VERSION "dbc-export 1 2026.26.6.5"

NS_ :

BS_:

BU_: ADSP APB APP APS APSB BB BMS CC CMP CMPD CP DAS DI DIF DIR DPB EPAS3P EPAS3S EPASTP EPASTS EPBL EPBR ESP EVSE FC GTW HCML HCMR HVP IBST ICR IDB LS OCS1P PARK PCS PCS2 PM PMF PMR PNCD PTC RADC RCM RCM2 RCM3 RCU SCCM SCM SCS SDCR TAS TCU TCU2 TPMS TRCM UI UIS UMC USM V2G VC VCBATT VCBATT0 VCBATT1 VCBATT2 VCCC VCFRONT VCFRONT1 VCFRONT2 VCLEFT VCRIGHT VCSEAT2L VCSEAT2R VCSEC VEH

BO_ 1060 PCS_alertLog: 8 PCS
 SG_ PCS_alertID M : 0|7@1+ (1,0) [0|127] "" Vector__XXX
 SG_ PCS_alertSet : 15|1@1+ (1,0) [0|1] "" Vector__XXX
 SG_ PCS_alertSource : 61|3@1+ (1,0) [0|7] "" Vector__XXX
 SG_ PCS_a001_llcFrequency m1 : 16|8@1+ (1,50) [50|305] "" Vector__XXX
 SG_ PCS_a001_llcCurrent m1 : 24|8@1+ (0.1,0) [0|25.5] "" Vector__XXX
 SG_ PCS_a001_phState m1 : 32|4@1+ (1,0) [0|15] "" Vector__XXX
 SG_ PCS_a001_pfcCurrentRms m1 : 36|9@1+ (0.1,0) [0|51.1] "" Vector__XXX
 SG_ PCS_a001_intBusV m1 : 45|9@1+ (1,0) [0|511] "" Vector__XXX
 SG_ PCS_a002_phState m2 : 16|4@1+ (1,0) [0|15] "" Vector__XXX
 SG_ PCS_a003_phState m3 : 16|4@1+ (1,0) [0|15] "" Vector__XXX
 SG_ PCS_a004_phState m4 : 16|4@1+ (1,0) [0|15] "" Vector__XXX
 SG_ PCS_a005_outputV m5 : 16|8@1+ (2,0) [0|510] "" Vector__XXX
 SG_ PCS_a005_outputVOvThreshold m5 : 24|8@1+ (2,0) [0|510] "" Vector__XXX
 SG_ PCS_a006_phState m6 : 16|4@1+ (1,0) [0|15] "" Vector__XXX
 SG_ PCS_a006_intBusPrechargeTarget m6 : 20|9@1+ (1,0) [0|511] "" Vector__XXX
 SG_ PCS_a006_intBusV m6 : 29|9@1+ (1,0) [0|511] "" Vector__XXX
 SG_ PCS_a006_inputVrms m6 : 38|9@1+ (1,0) [0|511] "" Vector__XXX
 SG_ PCS_a006_inputVToIntBusDeltaMax m6 : 47|7@1+ (1,0) [0|127] "" Vector__XXX
 SG_ PCS_a006_inputFrequency m6 : 54|7@1+ (1,40) [40|167] "" Vector__XXX
 SG_ PCS_a007_phATemperature m7 : 16|7@1+ (1,0) [0|127] "" Vector__XXX
 SG_ PCS_a007_phBTemperature m7 : 23|7@1+ (1,0) [0|127] "" Vector__XXX
 SG_ PCS_a007_phCTemperature m7 : 30|7@1+ (1,0) [0|127] "" Vector__XXX
 SG_ PCS_a007_ambientTemperature m7 : 37|7@1+ (1,0) [0|127] "" Vector__XXX
 SG_ PCS_a007_inputVrms m7 : 44|9@1+ (1,0) [0|511] "" Vector__XXX
 SG_ PCS_a007_inputIrms m7 : 53|8@1+ (0.5,0) [0|127.5] "" Vector__XXX
 SG_ PCS_a008_phState m8 : 16|4@1+ (1,0) [0|15] "" Vector__XXX
 SG_ PCS_a008_phaseTemperature m8 : 20|11@1- (0.1,40) [-62.4|142.3] "" Vector__XXX
 SG_ PCS_a008_inputVrms m8 : 31|9@1+ (1,0) [0|511] "" Vector__XXX
 SG_ PCS_a008_inputIrms m8 : 40|10@1+ (0.1,0) [0|102.3] "" Vector__XXX
 SG_ PCS_a009_phState m9 : 16|4@1+ (1,0) [0|15] "" Vector__XXX
 SG_ PCS_a009_pfcCurrentRms m9 : 20|9@1+ (0.1,0) [0|51.1] "" Vector__XXX
 SG_ PCS_a009_pfcCurrentTarget m9 : 32|12@1+ (0.01,0) [0|40.95] "" Vector__XXX
 SG_ PCS_a009_llcCurrent m9 : 44|8@1+ (0.1,0) [0|25.5] "" Vector__XXX
 SG_ PCS_a009_intBusV m9 : 52|8@1+ (2,0) [0|510] "" Vector__XXX
 SG_ PCS_a010_phState m10 : 16|4@1+ (1,0) [0|15] "" Vector__XXX
 SG_ PCS_a010_pfcCurrentRms m10 : 20|9@1+ (0.1,0) [0|51.1] "" Vector__XXX
 SG_ PCS_a010_llcCurrent m10 : 32|8@1+ (0.1,0) [0|25.5] "" Vector__XXX
 SG_ PCS_a010_intBusV m10 : 40|9@1+ (1,0) [0|511] "" Vector__XXX
 SG_ PCS_a010_intBusVTarget m10 : 49|9@1+ (1,0) [0|511] "" Vector__XXX
 SG_ PCS_a011_phState m11 : 16|4@1+ (1,0) [0|15] "" Vector__XXX
 SG_ PCS_a011_llcCurrent m11 : 20|8@1+ (0.1,0) [0|25.5] "" Vector__XXX
 SG_ PCS_a011_llcCurrentTarget m11 : 28|8@1+ (0.1,0) [0|25.5] "" Vector__XXX
 SG_ PCS_a011_llcFrequency m11 : 36|8@1+ (1,50) [50|305] "" Vector__XXX
 SG_ PCS_a011_intBusV m11 : 44|8@1+ (2,0) [0|510] "" Vector__XXX
 SG_ PCS_a011_outputV m11 : 52|8@1+ (2,0) [0|510] "" Vector__XXX
 SG_ PCS_a013_phState m13 : 16|4@1+ (1,0) [0|15] "" Vector__XXX
 SG_ PCS_a013_intBusPrechargeTarget m13 : 20|9@1+ (1,0) [0|511] "" Vector__XXX
 SG_ PCS_a013_intBusV m13 : 29|9@1+ (1,0) [0|511] "" Vector__XXX
 SG_ PCS_a013_inputVrms m13 : 38|9@1+ (1,0) [0|511] "" Vector__XXX
 SG_ PCS_a013_inputVToIntBusDeltaMax m13 : 47|7@1+ (1,0) [0|127] "" Vector__XXX
 SG_ PCS_a013_inputFrequency m13 : 54|7@1+ (1,40) [40|167] "" Vector__XXX
 SG_ PCS_a014_phaTemperature m14 : 16|11@1- (0.1,40) [-62.4|142.3] "" Vector__XXX
 SG_ PCS_a014_phbTemperature m14 : 27|11@1- (0.1,40) [-62.4|142.3] "" Vector__XXX
 SG_ PCS_a014_phcTemperature m14 : 40|11@1- (0.1,40) [-62.4|142.3] "" Vector__XXX
 SG_ PCS_a015_lvBusVoltage m15 : 16|8@1+ (0.15625,0) [0|39.84375] "" Vector__XXX
 SG_ PCS_a016_phAVoltSrcMissingDetect m16 : 16|1@1+ (1,0) [0|1] "" Vector__XXX
 SG_ PCS_a016_phBVoltSrcMissingDetect m16 : 17|1@1+ (1,0) [0|1] "" Vector__XXX
 SG_ PCS_a016_phCVoltSrcMissingDetect m16 : 18|1@1+ (1,0) [0|1] "" Vector__XXX
 SG_ PCS_a018_PhaseDiff_L1N_L2N m18 : 16|9@1+ (1,-1) [-1|510] "" Vector__XXX
 SG_ PCS_a018_PhaseDiff_L2N_L3N m18 : 25|9@1+ (1,-1) [-1|510] "" Vector__XXX
 SG_ PCS_a018_PhaseDiff_L1N_L3N m18 : 34|9@1+ (1,-1) [-1|510] "" Vector__XXX
 SG_ PCS_a018_PhaseDiff_L1L2_L1N m18 : 43|9@1+ (1,-1) [-1|510] "" Vector__XXX
 SG_ PCS_a018_L1NLocked m18 : 52|1@1+ (1,0) [0|1] "" Vector__XXX
 SG_ PCS_a018_L2NLocked m18 : 53|1@1+ (1,0) [0|1] "" Vector__XXX
 SG_ PCS_a018_L3NLocked m18 : 54|1@1+ (1,0) [0|1] "" Vector__XXX
 SG_ PCS_a018_L1L2Locked m18 : 55|1@1+ (1,0) [0|1] "" Vector__XXX
 SG_ PCS_a019_pcsMaxAvailablePower m19 : 16|8@1+ (0.1,0) [0|25.5] "" Vector__XXX
 SG_ PCS_a019_utilityPowerAvailable m19 : 24|8@1+ (0.1,0) [0|25.5] "" Vector__XXX
 SG_ PCS_a019_userPowerRequest m19 : 32|8@1+ (0.1,0) [0|25.5] "" Vector__XXX
 SG_ PCS_a019_phAFaulted m19 : 40|1@1+ (1,0) [0|1] "" Vector__XXX
 SG_ PCS_a019_phBFaulted m19 : 41|1@1+ (1,0) [0|1] "" Vector__XXX
 SG_ PCS_a019_phCFaulted m19 : 42|1@1+ (1,0) [0|1] "" Vector__XXX
 SG_ PCS_a020_chargeEnableLine m20 : 16|1@1+ (1,0) [0|1] "" Vector__XXX
 SG_ PCS_a020_chargeEnableCan m20 : 17|1@1+ (1,0) [0|1] "" Vector__XXX
 SG_ PCS_a021_HVP_hvsControl m21 : 16|1@1+ (1,0) [0|1] "" Vector__XXX
 SG_ PCS_a023_CP_chargeStatus m23 : 16|1@1+ (1,0) [0|1] "" Vector__XXX
 SG_ PCS_a023_CP_status m23 : 17|1@1+ (1,0) [0|1] "" Vector__XXX
 SG_ PCS_a024_VCFRONT_sensors m24 : 16|1@1+ (1,0) [0|1] "" Vector__XXX
 SG_ PCS_a024_VCFRONT_vehicleStatus m24 : 17|1@1+ (1,0) [0|1] "" Vector__XXX
 SG_ PCS_a024_VCFRONT_systemStatus m24 : 18|1@1+ (1,0) [0|1] "" Vector__XXX
 SG_ PCS_a024_VCFRONT_coolant m24 : 19|1@1+ (1,0) [0|1] "" Vector__XXX
 SG_ PCS_a024_VCFRONT_vehNm m24 : 20|1@1+ (1,0) [0|1] "" Vector__XXX
 SG_ PCS_a024_VC_pcsManagement m24 : 21|1@1+ (1,0) [0|1] "" Vector__XXX
 SG_ PCS_a024_VCFRONT_LVPowerState m24 : 22|1@1+ (1,0) [0|1] "" Vector__XXX
 SG_ PCS_a025_cpu2ErrorCode m25 : 16|4@1+ (1,0) [0|15] "" Vector__XXX
 SG_ PCS_a025_bootromStatus m25 : 20|4@1+ (1,0) [0|15] "" Vector__XXX
 SG_ PCS_a025_bootloaderStatus m25 : 24|4@1+ (1,0) [0|15] "" Vector__XXX
 SG_ PCS_a025_bootromRequestFlag m25 : 28|1@1+ (1,0) [0|1] "" Vector__XXX
 SG_ PCS_a025_bootromRequestStatusFla m25 : 29|1@1+ (1,0) [0|1] "" Vector__XXX
 SG_ PCS_a025_cpu2StoredAppCrcLsb16 m25 : 32|16@1+ (1,0) [0|65535] "" Vector__XXX
 SG_ PCS_a027_chgPhATemp m27 : 16|8@1- (1,40) [-88|167] "" Vector__XXX
 SG_ PCS_a027_chgPhBTemp m27 : 24|8@1- (1,40) [-88|167] "" Vector__XXX
 SG_ PCS_a027_chgPhCTemp m27 : 32|8@1- (1,40) [-88|167] "" Vector__XXX
 SG_ PCS_a027_chgPhANoFlowBucket m27 : 40|5@1+ (0.2,0) [0|6.2] "" Vector__XXX
 SG_ PCS_a027_chgPhBNoFlowBucket m27 : 48|5@1+ (0.2,0) [0|6.2] "" Vector__XXX
 SG_ PCS_a027_chgPhCNoFlowBucket m27 : 56|5@1+ (0.2,0) [0|6.2] "" Vector__XXX
 SG_ PCS_a028_outputV m28 : 16|10@1+ (0.5,0) [0|511.5] "" Vector__XXX
 SG_ PCS_a028_outputVUvThreshold m28 : 26|10@1+ (0.5,0) [0|511.5] "" Vector__XXX
 SG_ PCS_a029_inputVrms m29 : 16|9@1+ (1,0) [0|511] "" Vector__XXX
 SG_ PCS_a029_chgInputPower m29 : 32|8@1+ (0.1,0) [0|25.5] "" Vector__XXX
 SG_ PCS_a029_bmsPowerCommand m29 : 40|8@1+ (0.1,0) [0|25.5] "" Vector__XXX
 SG_ PCS_a029_phaseConfig m29 : 48|4@1+ (1,0) [0|15] "" Vector__XXX
 SG_ PCS_a032_phATransientRetryCount m32 : 16|9@1+ (0.1,0) [0|51.1] "" Vector__XXX
 SG_ PCS_a032_phBTransientRetryCount m32 : 25|9@1+ (0.1,0) [0|51.1] "" Vector__XXX
 SG_ PCS_a032_phCTransientRetryCount m32 : 34|9@1+ (0.1,0) [0|51.1] "" Vector__XXX
 SG_ PCS_a032_phAFaulted m32 : 43|1@1+ (1,0) [0|1] "" Vector__XXX
 SG_ PCS_a032_phBFaulted m32 : 44|1@1+ (1,0) [0|1] "" Vector__XXX
 SG_ PCS_a032_phCFaulted m32 : 45|1@1+ (1,0) [0|1] "" Vector__XXX
 SG_ PCS_a033_HV_busV m33 : 16|12@1+ (0.146484375,0) [0|599.853515625] "" Vector__XXX
 SG_ PCS_a034_HV_busV m34 : 16|12@1+ (0.146484375,0) [0|599.853515625] "" Vector__XXX
 SG_ PCS_a035_LV_busV m35 : 16|12@1+ (0.009765625,0) [0|39.990234375] "" Vector__XXX
 SG_ PCS_a037_dcdcPwmDeassertedCount m37 : 16|8@1+ (1,0) [0|255] "" Vector__XXX
 SG_ PCS_a038_dcdcClaFaultCode m38 : 16|4@1+ (1,0) [0|15] "" Vector__XXX
 SG_ PCS_a038_dcdcSubState m38 : 20|5@1+ (1,0) [0|31] "" Vector__XXX
 SG_ PCS_a038_dcdcLvBusV m38 : 25|8@1+ (0.15625,0) [0|39.84375] "" Vector__XXX
 SG_ PCS_a038_dcdcHvBusV m38 : 33|10@1+ (0.5859375,0) [0|599.4140625] "" Vector__XXX
 SG_ PCS_a038_dcdcLvBusCurrent_A m38 : 43|10@1- (0.78125,0) [-400|399.21875] "" Vector__XXX
 SG_ PCS_a038_dcdcPwmEnableDeasserted m38 : 53|7@1+ (1,0) [0|127] "" Vector__XXX
 SG_ PCS_a038_dcdcPwmEnableLine m38 : 60|1@1+ (1,0) [0|1] "" Vector__XXX
 SG_ PCS_a040_dcdcLvVoltageTarget m40 : 16|8@1+ (0.1,0) [0|25.5] "" Vector__XXX
 SG_ PCS_a040_dcdcLvVoltage m40 : 24|8@1+ (0.1,0) [0|25.5] "" Vector__XXX
 SG_ PCS_a040_dcdcLvOutputCurrent m40 : 32|13@1- (0.1,0) [-409.6|409.5] "" Vector__XXX
 SG_ PCS_a041_dcdcTemperature m41 : 16|11@1- (0.1,40) [-62.4|142.3] "" Vector__XXX
 SG_ PCS_a042_dcdcEnableLine m42 : 16|1@1+ (1,0) [0|1] "" Vector__XXX
 SG_ PCS_a042_dcdcEnableCan m42 : 17|1@1+ (1,0) [0|1] "" Vector__XXX
 SG_ PCS_a043_dcdcLvBusV m43 : 16|10@1+ (0.0390625,0) [0|39.9609375] "" Vector__XXX
 SG_ PCS_a043_dcdcHvBusV m43 : 26|12@1+ (0.146484375,0) [0|599.853515625] "" Vector__XXX
 SG_ PCS_a043_hvPrechargeTargetV m43 : 40|12@1+ (0.146484375,0) [0|599.853515625] "" Vector__XXX
 SG_ PCS_a044_FaultReasonCode m44 : 16|2@1+ (1,0) [0|3] "" Vector__XXX
 SG_ PCS_a044_shortTime_us m44 : 18|10@1+ (0.0312805473804,0) [0|31.9999999701] "" Vector__XXX
 SG_ PCS_a044_dcdcLvBusCurrent_A m44 : 28|10@1+ (0.391006857157,0) [0|400.000014872] "" Vector__XXX
 SG_ PCS_a044_vTankPeak_abs_V m44 : 38|10@1+ (1,0) [0|1023] "" Vector__XXX
 SG_ PCS_a045_hvBusEstimated_C_uF m45 : 16|10@1+ (7.820137,0) [0|8000.000151] "" Vector__XXX
 SG_ PCS_a045_hvBusEstimated_R_kOhm m45 : 26|10@1+ (0.0488758571446,0) [0|50.0000018589] "" Vector__XXX
 SG_ PCS_a046_hvBusEstimated_C_uF m46 : 16|10@1+ (7.820137,0) [0|8000.000151] "" Vector__XXX
 SG_ PCS_a046_hvBusEstimated_R_kOhm m46 : 26|10@1+ (0.0488758571446,0) [0|50.0000018589] "" Vector__XXX
 SG_ PCS_a047_cpu1BootLoaderCrcMismat m47 : 16|1@1+ (1,0) [0|1] "" Vector__XXX
 SG_ PCS_a047_cpu2BootLoaderCrcMismat m47 : 17|1@1+ (1,0) [0|1] "" Vector__XXX
 SG_ PCS_a047_calculatedBootloaderCrc m47 : 24|32@1+ (1,0) [0|4294967295] "" Vector__XXX
 SG_ PCS_a049_dcdcTemperature m49 : 16|11@1- (0.1,40) [-62.4|142.3] "" Vector__XXX
 SG_ PCS_a051_phState m51 : 16|4@1+ (1,0) [0|15] "" Vector__XXX
 SG_ PCS_a051_pfcCurrentRms m51 : 20|9@1+ (0.1,0) [0|51.1] "" Vector__XXX
 SG_ PCS_a051_llcCurrent m51 : 29|8@1+ (0.1,0) [0|25.5] "" Vector__XXX
 SG_ PCS_a051_intBusV m51 : 37|9@1+ (1,0) [0|511] "" Vector__XXX
 SG_ PCS_a051_intBusVTarget m51 : 46|9@1+ (1,0) [0|511] "" Vector__XXX
 SG_ PCS_a051_intBusStaticRipple m51 : 55|6@1+ (1,0) [0|63] "" Vector__XXX
 SG_ PCS_a052_inputVrms m52 : 16|9@1+ (1,0) [0|511] "" Vector__XXX
 SG_ PCS_a053_inputVrms m53 : 16|9@1+ (1,0) [0|511] "" Vector__XXX
 SG_ PCS_a053_inputIrms m53 : 25|10@1+ (0.1,0) [0|102.3] "" Vector__XXX
 SG_ PCS_a053_acChargeCurrentLimit m53 : 40|7@1+ (1,0) [0|127] "" Vector__XXX
 SG_ PCS_a053_startingInputVrms m53 : 47|9@1+ (1,0) [0|511] "" Vector__XXX
 SG_ PCS_a053_phaseConfig m53 : 56|4@1+ (1,0) [0|15] "" Vector__XXX
 SG_ PCS_a054_inputVrms m54 : 16|9@1+ (1,0) [0|511] "" Vector__XXX
 SG_ PCS_a054_inputIrms m54 : 25|10@1+ (0.1,0) [0|102.3] "" Vector__XXX
 SG_ PCS_a054_acChargeCurrentLimit m54 : 40|7@1+ (1,0) [0|127] "" Vector__XXX
 SG_ PCS_a054_startingInputVrms m54 : 47|9@1+ (1,0) [0|511] "" Vector__XXX
 SG_ PCS_a054_phaseConfig m54 : 56|4@1+ (1,0) [0|15] "" Vector__XXX
 SG_ PCS_a057_inputVrms m57 : 16|10@1+ (0.5,0) [0|511.5] "" Vector__XXX
 SG_ PCS_a057_inputFrequency m57 : 26|9@1+ (0.1,40) [40|91.1] "" Vector__XXX
 SG_ PCS_a058_inputVrms m58 : 16|10@1+ (0.5,0) [0|511.5] "" Vector__XXX
 SG_ PCS_a058_inputFrequency m58 : 26|12@1+ (0.01,40) [40|80.95] "" Vector__XXX
 SG_ PCS_a059_inputVrms m59 : 16|10@1+ (0.5,0) [0|511.5] "" Vector__XXX
 SG_ PCS_a059_inputOvRmsThreshold m59 : 26|10@1+ (0.5,0) [0|511.5] "" Vector__XXX
 SG_ PCS_a060_inputVPeak m60 : 16|10@1+ (0.5,0) [0|511.5] "" Vector__XXX
 SG_ PCS_a060_inputOvPeakThreshold m60 : 26|10@1+ (0.5,0) [0|511.5] "" Vector__XXX
 SG_ PCS_a061_chgInputVdcOffset_L1N m61 : 16|8@1+ (1,0) [0|255] "" Vector__XXX
 SG_ PCS_a061_chgInputVdcOffset_L2N m61 : 24|8@1+ (1,0) [0|255] "" Vector__XXX
 SG_ PCS_a061_chgInputVdcOffset_L3N m61 : 32|8@1+ (1,0) [0|255] "" Vector__XXX
 SG_ PCS_a061_chgInputVdcOffset_L1L2 m61 : 40|8@1+ (1,0) [0|255] "" Vector__XXX
 SG_ PCS_a061_PllSourceIrrational_L1N m61 : 48|1@1+ (1,0) [0|1] "" Vector__XXX
 SG_ PCS_a061_PllSourceIrrational_L2N m61 : 49|1@1+ (1,0) [0|1] "" Vector__XXX
 SG_ PCS_a061_PllSourceIrrational_L3N m61 : 50|1@1+ (1,0) [0|1] "" Vector__XXX
 SG_ PCS_a061_PllSourceIrrational_L1L m61 : 51|1@1+ (1,0) [0|1] "" Vector__XXX
 SG_ PCS_a062_chgInputIOffset m62 : 16|12@1- (0.01,0) [-20.48|20.47] "" Vector__XXX
 SG_ PCS_a063_chgOutputV m63 : 16|10@1+ (1,0) [0|1023] "" Vector__XXX
 SG_ PCS_a063_hvpHvLinkVoltage m63 : 26|11@1- (1,0) [-1024|1023] "" Vector__XXX
 SG_ PCS_a064_chgOutputIOffset m64 : 16|12@1- (0.01,0) [-20.48|20.47] "" Vector__XXX
 SG_ PCS_a065_inputVrms m65 : 16|10@1+ (0.5,0) [0|511.5] "" Vector__XXX
 SG_ PCS_a065_inputFrequency m65 : 26|9@1+ (0.1,40) [40|91.1] "" Vector__XXX
 SG_ PCS_a066_dcdcHvBusVolt m66 : 16|14@1+ (0.1,0) [0|1638.3] "" Vector__XXX
 SG_ PCS_a066_hvpHvLinkVoltage m66 : 32|11@1- (1,0) [-1024|1023] "" Vector__XXX
 SG_ PCS_a067_dcdcLvBusVolt m67 : 16|13@1+ (0.01,0) [0|81.91] "" Vector__XXX
 SG_ PCS_a067_vcfrontPcsEFuseV m67 : 29|10@1+ (0.1,0) [0|102.3] "" Vector__XXX
 SG_ PCS_a067_vcfrontVcrightVoltage m67 : 40|10@1+ (0.1,0) [0|102.3] "" Vector__XXX
 SG_ PCS_a068_dcdcTankVolt m68 : 16|16@1- (0.030517578125,0) [-1000|999.969482422] "" Vector__XXX
 SG_ PCS_a068_dcdcTankVoltOffset m68 : 32|16@1- (0.00152587890625,0) [-50|49.9984741211] "" Vector__XXX
 SG_ PCS_a071_phState m71 : 16|4@1+ (1,0) [0|15] "" Vector__XXX
 SG_ PCS_a071_inputVrms m71 : 20|10@1+ (0.5,0) [0|511.5] "" Vector__XXX
 SG_ PCS_a071_intBusV m71 : 30|9@1+ (1,0) [0|511] "" Vector__XXX
 SG_ PCS_a071_inputFrequency m71 : 39|9@1+ (0.1,40) [40|91.1] "" Vector__XXX
 SG_ PCS_a071_llcFrequency m71 : 48|8@1+ (1,50) [50|305] "" Vector__XXX
 SG_ PCS_a072_task1Stopped m72 : 16|1@1+ (1,0) [0|1] "" Vector__XXX
 SG_ PCS_a072_task2Stopped m72 : 17|1@1+ (1,0) [0|1] "" Vector__XXX
 SG_ PCS_a073_inputL1NVrms m73 : 16|9@1+ (1,0) [0|511] "" Vector__XXX
 SG_ PCS_a073_inputL2NVrms m73 : 25|9@1+ (1,0) [0|511] "" Vector__XXX
 SG_ PCS_a073_inputL3NVrms m73 : 34|9@1+ (1,0) [0|511] "" Vector__XXX
 SG_ PCS_a073_inputNGVrms m73 : 43|9@1+ (1,0) [0|511] "" Vector__XXX
 SG_ PCS_a073_phaseConfig m73 : 52|4@1+ (1,0) [0|15] "" Vector__XXX
 SG_ PCS_a073_cpType m73 : 56|2@1+ (1,0) [0|3] "" Vector__XXX
 SG_ PCS_a074_dcdcLvBusV m74 : 16|10@1+ (0.0390625,0) [0|39.9609375] "" Vector__XXX
 SG_ PCS_a074_dcdcHvBusV m74 : 26|12@1+ (0.146484375,0) [0|599.853515625] "" Vector__XXX
 SG_ PCS_a075_dcdcLvBusV m75 : 16|10@1+ (0.0390625,0) [0|39.9609375] "" Vector__XXX
 SG_ PCS_a075_dcdcHvBusV m75 : 26|12@1+ (0.146484375,0) [0|599.853515625] "" Vector__XXX
 SG_ PCS_a075_dcdcSubState m75 : 40|5@1+ (1,0) [0|31] "" Vector__XXX
 SG_ PCS_a076_pcsControlRequest m76 : 16|2@1+ (1,0) [0|3] "" Vector__XXX
 SG_ PCS_a076_dcdcSubState m76 : 18|5@1+ (1,0) [0|31] "" Vector__XXX
 SG_ PCS_a076_dcdcEnableLine m76 : 23|1@1+ (1,0) [0|1] "" Vector__XXX
 SG_ PCS_a076_dcdcPwmEnableDeasserted m76 : 24|8@1+ (1,0) [0|255] "" Vector__XXX
 SG_ PCS_a078_phaTemperature m78 : 16|8@1- (1,40) [-88|167] "" Vector__XXX
 SG_ PCS_a078_phbTemperature m78 : 24|8@1- (1,40) [-88|167] "" Vector__XXX
 SG_ PCS_a078_phcTemperature m78 : 32|8@1- (1,40) [-88|167] "" Vector__XXX
 SG_ PCS_a078_dcdcTemperature m78 : 40|8@1- (1,40) [-88|167] "" Vector__XXX
 SG_ PCS_a078_ptCoolantTemp m78 : 48|8@1- (1,40) [-88|167] "" Vector__XXX
 SG_ PCS_a079_eepromOperation m79 : 16|4@1+ (1,0) [0|15] "" Vector__XXX
 SG_ PCS_a079_eepromOperationRegion m79 : 20|2@1+ (1,0) [0|3] "" Vector__XXX
 SG_ PCS_a079_recordID m79 : 24|8@1+ (1,0) [0|255] "" Vector__XXX
 SG_ PCS_a079_eepromOperationErrorCod m79 : 32|5@1+ (1,0) [0|31] "" Vector__XXX
 SG_ PCS_a079_operationAddress m79 : 40|16@1+ (1,0) [0|65535] "" Vector__XXX
 SG_ PCS_a079_eepromErrorCount m79 : 56|5@1+ (1,0) [0|31] "" Vector__XXX
 SG_ PCS_a080_phADamaged m80 : 16|1@1+ (1,0) [0|1] "" Vector__XXX
 SG_ PCS_a080_phBDamaged m80 : 17|1@1+ (1,0) [0|1] "" Vector__XXX
 SG_ PCS_a080_phCDamaged m80 : 18|1@1+ (1,0) [0|1] "" Vector__XXX
 SG_ PCS_a080_phANVRAMStoredState m80 : 19|3@1+ (1,0) [0|7] "" Vector__XXX
 SG_ PCS_a080_phBNVRAMStoredState m80 : 24|3@1+ (1,0) [0|7] "" Vector__XXX
 SG_ PCS_a080_phCNVRAMStoredState m80 : 27|3@1+ (1,0) [0|7] "" Vector__XXX
 SG_ PCS_a081_dcdcLvBusV m81 : 16|10@1+ (0.0390625,0) [0|39.9609375] "" Vector__XXX
 SG_ PCS_a081_dcdcHvBusV m81 : 26|12@1+ (0.146484375,0) [0|599.853515625] "" Vector__XXX
 SG_ PCS_a081_faultedSubstate m81 : 40|5@1+ (1,0) [0|31] "" Vector__XXX
 SG_ PCS_a082_dcdcLvBusV m82 : 16|10@1+ (0.0390625,0) [0|39.9609375] "" Vector__XXX
 SG_ PCS_a082_dcdcHvBusV m82 : 26|12@1+ (0.146484375,0) [0|599.853515625] "" Vector__XXX
 SG_ PCS_a082_faultedSubstate m82 : 40|5@1+ (1,0) [0|31] "" Vector__XXX
 SG_ PCS_a085_dcdcHalfPeriodUs m85 : 16|16@1+ (0.005,0) [0|327.675] "" Vector__XXX
 SG_ PCS_a086_dcdcTemperature m86 : 16|12@1- (0.1,0) [-204.8|204.7] "" Vector__XXX
 SG_ PCS_a086_pcsAmbientTemperature m86 : 28|12@1- (0.1,0) [-204.8|204.7] "" Vector__XXX
 SG_ PCS_a086_vcfrontPTCoolantTemp m86 : 40|12@1- (0.1,0) [-204.8|204.7] "" Vector__XXX
 SG_ PCS_a088_gridConfig m88 : 16|4@1+ (1,0) [0|15] "" Vector__XXX
 SG_ PCS_a088_phAFrequency m88 : 20|12@1+ (0.01,40) [40|80.95] "" Vector__XXX
 SG_ PCS_a088_phBFrequency m88 : 32|12@1+ (0.01,40) [40|80.95] "" Vector__XXX
 SG_ PCS_a088_phCFrequency m88 : 44|12@1+ (0.01,40) [40|80.95] "" Vector__XXX
 SG_ PCS_a089_hvSlewRate m89 : 16|8@1- (2,0) [-256|254] "" Vector__XXX
 SG_ PCS_a089_avgSlewRate m89 : 24|8@1- (2,0) [-256|254] "" Vector__XXX
 SG_ PCS_a089_G m89 : 32|4@1+ (0.2,0) [0|3] "" Vector__XXX
 SG_ PCS_a089_HV_busV m89 : 36|9@1+ (0.8203125,0) [0|419.1796875] "" Vector__XXX
 SG_ PCS_a089_PhaseShift m89 : 45|5@1+ (0.5,0) [0|15.5] "" Vector__XXX
 SG_ PCS_a089_Freq m89 : 50|9@1+ (1,0) [0|511] "" Vector__XXX
 SG_ PCS_a089_fastDischargeMode m89 : 59|1@1+ (1,0) [0|1] "" Vector__XXX
 SG_ PCS_a089_slowDischargeMode m89 : 60|1@1+ (1,0) [0|1] "" Vector__XXX
 SG_ PCS_a090_vRmsL1N m90 : 16|9@1+ (1,0) [0|511] "" Vector__XXX
 SG_ PCS_a090_vRmsL2N m90 : 25|9@1+ (1,0) [0|511] "" Vector__XXX
 SG_ PCS_a090_vRmsL3N m90 : 34|9@1+ (1,0) [0|511] "" Vector__XXX
 SG_ PCS_a090_vRmsL1L2 m90 : 43|9@1+ (1,0) [0|511] "" Vector__XXX
 SG_ PCS_a090_evaluatedGridConfig m90 : 52|4@1+ (1,0) [0|15] "" Vector__XXX
 SG_ PCS_a090_phASourceMissing m90 : 56|1@1+ (1,0) [0|1] "" Vector__XXX
 SG_ PCS_a090_phBSourceMissing m90 : 57|1@1+ (1,0) [0|1] "" Vector__XXX
 SG_ PCS_a090_phCSourceMissing m90 : 58|1@1+ (1,0) [0|1] "" Vector__XXX
 SG_ PCS_a091_intBusTarget m91 : 16|9@1+ (1,0) [0|511] "" Vector__XXX
 SG_ PCS_a091_intBusMaxRippleLevel m91 : 25|9@1+ (0.1,0) [0|51.1] "" Vector__XXX
 SG_ PCS_a091_pfcCurrentIrms m91 : 34|8@1+ (0.1,0) [0|25.5] "" Vector__XXX
 SG_ PCS_a091_phaseInputVrms m91 : 42|9@1+ (1,0) [0|511] "" Vector__XXX
 SG_ PCS_a091_phaseTemp m91 : 51|8@1- (1,0) [-128|127] "" Vector__XXX
 SG_ PCS_a092_pfcIrmsPhA m92 : 16|7@1+ (0.2,0) [0|25.4] "" Vector__XXX
 SG_ PCS_a092_pfcIrmsPhB m92 : 23|7@1+ (0.2,0) [0|25.4] "" Vector__XXX
 SG_ PCS_a092_pfcIrmsPhC m92 : 30|7@1+ (0.2,0) [0|25.4] "" Vector__XXX
 SG_ PCS_a092_chgTempPhA m92 : 37|8@1- (1,40) [-88|167] "" Vector__XXX
 SG_ PCS_a092_chgTempPhB m92 : 45|8@1- (1,40) [-88|167] "" Vector__XXX
 SG_ PCS_a092_chgTempPhC m92 : 53|8@1- (1,40) [-88|167] "" Vector__XXX
 SG_ PCS_a093_powerRail5VN m93 : 16|10@1+ (0.01,0) [0|10.23] "" Vector__XXX
 SG_ PCS_a093_powerRail3V3 m93 : 26|10@1+ (0.01,0) [0|10.23] "" Vector__XXX
 SG_ PCS_a093_powerRail1V5 m93 : 40|8@1+ (0.01,0) [0|2.55] "" Vector__XXX
 SG_ PCS_a093_powerRail1V2 m93 : 48|8@1+ (0.01,0) [0|2.55] "" Vector__XXX
 SG_ PCS_a093_irrational1V2Rail m93 : 56|1@1+ (1,0) [0|1] "" Vector__XXX
 SG_ PCS_a093_irrational1V5Rail m93 : 57|1@1+ (1,0) [0|1] "" Vector__XXX
 SG_ PCS_a093_irrational3V3Rail m93 : 58|1@1+ (1,0) [0|1] "" Vector__XXX
 SG_ PCS_a093_irrational5VNRail m93 : 59|1@1+ (1,0) [0|1] "" Vector__XXX
 SG_ PCS_a094_malfunctionCode m94 : 16|2@1+ (1,0) [0|3] "" Vector__XXX
 SG_ PCS_a095_powerRail5VN m95 : 16|10@1+ (0.01,0) [0|10.23] "" Vector__XXX
 SG_ PCS_a095_pcsControlRequest m95 : 26|2@1+ (1,0) [0|3] "" Vector__XXX
 SG_ PCS_a096_gridConfig m96 : 16|4@1+ (1,0) [0|15] "" Vector__XXX
 SG_ PCS_a096_phAFrequency m96 : 20|12@1+ (0.01,40) [40|80.95] "" Vector__XXX
 SG_ PCS_a096_phBFrequency m96 : 32|12@1+ (0.01,40) [40|80.95] "" Vector__XXX
 SG_ PCS_a096_phCFrequency m96 : 44|12@1+ (0.01,40) [40|80.95] "" Vector__XXX
 SG_ PCS_a097_phADamaged m97 : 16|1@1+ (1,0) [0|1] "" Vector__XXX
 SG_ PCS_a097_phBDamaged m97 : 17|1@1+ (1,0) [0|1] "" Vector__XXX
 SG_ PCS_a097_phCDamaged m97 : 18|1@1+ (1,0) [0|1] "" Vector__XXX
 SG_ PCS_a097_phANVRAMStoredState m97 : 19|3@1+ (1,0) [0|7] "" Vector__XXX
 SG_ PCS_a097_phBNVRAMStoredState m97 : 24|3@1+ (1,0) [0|7] "" Vector__XXX
 SG_ PCS_a097_phCNVRAMStoredState m97 : 27|3@1+ (1,0) [0|7] "" Vector__XXX
 SG_ PCS_a100_inputVrms m100 : 16|9@1+ (1,0) [0|511] "" Vector__XXX
 SG_ PCS_a100_phIntBusVolt m100 : 25|9@1+ (1,0) [0|511] "" Vector__XXX
 SG_ PCS_a100_phKwhCounter m100 : 34|13@1+ (1,0) [0|8191] "" Vector__XXX
 SG_ PCS_a100_phKwhCounterDeltaFromMa m100 : 48|13@1+ (1,0) [0|8191] "" Vector__XXX
 SG_ PCS_a102_pcsControlRequest m102 : 16|2@1+ (1,0) [0|3] "" Vector__XXX
 SG_ PCS_a102_NMIFlagRegisters m102 : 18|11@1+ (1,0) [0|2047] "" Vector__XXX
 SG_ PCS_a102_systemResetRegisters m102 : 29|11@1+ (1,0) [0|2047] "" Vector__XXX
 SG_ PCS_a102_dcdcEnableLine m102 : 40|1@1+ (1,0) [0|1] "" Vector__XXX
 SG_ PCS_a104_ambientTemperature m104 : 16|11@1- (0.1,40) [-62.4|142.3] "" Vector__XXX
 SG_ PCS_a107_VC_pcsInterface m107 : 16|1@1+ (1,0) [0|1] "" Vector__XXX
 SG_ PCS_a108_installedInAWrongPlatfo m108 : 16|1@1+ (1,0) [0|1] "" Vector__XXX
 SG_ PCS_a109_inputL2NVrms m109 : 16|9@1+ (1,0) [0|511] "" Vector__XXX
 SG_ PCS_a109_inputL3NVrms m109 : 25|9@1+ (1,0) [0|511] "" Vector__XXX

BO_ 932 PCS_alertMatrix: 8 PCS
 SG_ PCS_matrixIndex M : 0|4@1+ (1,0) [0|15] "" Vector__XXX
 SG_ PCS_a001_chgHwInputOc m0 : 4|1@1+ (1,0) [0|1] "" Vector__XXX
 SG_ PCS_a002_chgHwOutputOc m0 : 5|1@1+ (1,0) [0|1] "" Vector__XXX
 SG_ PCS_a003_chgHwInputOv m0 : 6|1@1+ (1,0) [0|1] "" Vector__XXX
 SG_ PCS_a004_chgHwIntBusOv m0 : 7|1@1+ (1,0) [0|1] "" Vector__XXX
 SG_ PCS_a005_chgOutputOv m0 : 8|1@1+ (1,0) [0|1] "" Vector__XXX
 SG_ PCS_a006_chgPrechargeFailedScr m0 : 9|1@1+ (1,0) [0|1] "" Vector__XXX
 SG_ PCS_a007_chgPhaseTempHot m0 : 10|1@1+ (1,0) [0|1] "" Vector__XXX
 SG_ PCS_a008_chgPhaseOverTemp m0 : 11|1@1+ (1,0) [0|1] "" Vector__XXX
 SG_ PCS_a009_chgPfcCurrentRegulation m0 : 12|1@1+ (1,0) [0|1] "" Vector__XXX
 SG_ PCS_a010_chgIntBusVRegulation m0 : 13|1@1+ (1,0) [0|1] "" Vector__XXX
 SG_ PCS_a011_chgLlcCurrentRegulation m0 : 14|1@1+ (1,0) [0|1] "" Vector__XXX
 SG_ PCS_a012_chgPfcIBandTracerFault m0 : 15|1@1+ (1,0) [0|1] "" Vector__XXX
 SG_ PCS_a013_chgPrechargeFailedBoost m0 : 16|1@1+ (1,0) [0|1] "" Vector__XXX
 SG_ PCS_a014_chgTempRationality m0 : 17|1@1+ (1,0) [0|1] "" Vector__XXX
 SG_ PCS_a015_chg12vUv m0 : 18|1@1+ (1,0) [0|1] "" Vector__XXX
 SG_ PCS_a016_chgAllPhasesFaulted m0 : 19|1@1+ (1,0) [0|1] "" Vector__XXX
 SG_ PCS_a017_chgWallPowerRemoval m0 : 20|1@1+ (1,0) [0|1] "" Vector__XXX
 SG_ PCS_a018_chgUnknownGridConfig m0 : 21|1@1+ (1,0) [0|1] "" Vector__XXX
 SG_ PCS_a019_acChargePowerLimited m0 : 22|1@1+ (1,0) [0|1] "" Vector__XXX
 SG_ PCS_a020_chgEnableLineMismatch m0 : 23|1@1+ (1,0) [0|1] "" Vector__XXX
 SG_ PCS_a021_hvpMia m0 : 24|1@1+ (1,0) [0|1] "" Vector__XXX
 SG_ PCS_a022_bmsMia m0 : 25|1@1+ (1,0) [0|1] "" Vector__XXX
 SG_ PCS_a023_cpMia m0 : 26|1@1+ (1,0) [0|1] "" Vector__XXX
 SG_ PCS_a024_vcfrontMia m0 : 27|1@1+ (1,0) [0|1] "" Vector__XXX
 SG_ PCS_a025_cpu2Malfunction m0 : 28|1@1+ (1,0) [0|1] "" Vector__XXX
 SG_ PCS_a026_watchdogAlarmed m0 : 29|1@1+ (1,0) [0|1] "" Vector__XXX
 SG_ PCS_a027_chgInsufficientCooling m0 : 30|1@1+ (1,0) [0|1] "" Vector__XXX
 SG_ PCS_a028_chgOutputUv m0 : 31|1@1+ (1,0) [0|1] "" Vector__XXX
 SG_ PCS_a029_chgPowerRationality m0 : 32|1@1+ (1,0) [0|1] "" Vector__XXX
 SG_ PCS_a030_canRationality m0 : 33|1@1+ (1,0) [0|1] "" Vector__XXX
 SG_ PCS_a031_uiMia m0 : 34|1@1+ (1,0) [0|1] "" Vector__XXX
 SG_ PCS_a032_excessiveGridTransients m0 : 35|1@1+ (1,0) [0|1] "" Vector__XXX
 SG_ PCS_a033_hvBusUv m0 : 36|1@1+ (1,0) [0|1] "" Vector__XXX
 SG_ PCS_a034_hvBusOv m0 : 37|1@1+ (1,0) [0|1] "" Vector__XXX
 SG_ PCS_a035_lvBusUv m0 : 38|1@1+ (1,0) [0|1] "" Vector__XXX
 SG_ PCS_a036_lvBusOv m0 : 39|1@1+ (1,0) [0|1] "" Vector__XXX
 SG_ PCS_a037_resonantTankOc m0 : 40|1@1+ (1,0) [0|1] "" Vector__XXX
 SG_ PCS_a038_claFaulted m0 : 41|1@1+ (1,0) [0|1] "" Vector__XXX
 SG_ PCS_a039_sdModuleClkFault m0 : 42|1@1+ (1,0) [0|1] "" Vector__XXX
 SG_ PCS_a040_dcdcMaxPowerReached m0 : 43|1@1+ (1,0) [0|1] "" Vector__XXX
 SG_ PCS_a041_dcdcOverTemp m0 : 44|1@1+ (1,0) [0|1] "" Vector__XXX
 SG_ PCS_a042_dcdcEnableLineMismatch m0 : 45|1@1+ (1,0) [0|1] "" Vector__XXX
 SG_ PCS_a043_hvBusPrechargeFailure m0 : 46|1@1+ (1,0) [0|1] "" Vector__XXX
 SG_ PCS_a044_12vSupportRegulation m0 : 47|1@1+ (1,0) [0|1] "" Vector__XXX
 SG_ PCS_a045_hvBusLowImpedance m0 : 48|1@1+ (1,0) [0|1] "" Vector__XXX
 SG_ PCS_a046_hvBusHighImpedence m0 : 49|1@1+ (1,0) [0|1] "" Vector__XXX
 SG_ PCS_a047_bootloaderCrcMismatch m0 : 50|1@1+ (1,0) [0|1] "" Vector__XXX
 SG_ PCS_a048_softwareAssertion m0 : 51|1@1+ (1,0) [0|1] "" Vector__XXX
 SG_ PCS_a049_dcdcTempRationality m0 : 52|1@1+ (1,0) [0|1] "" Vector__XXX
 SG_ PCS_a050_dcdc12VsupportFaulted m0 : 53|1@1+ (1,0) [0|1] "" Vector__XXX
 SG_ PCS_a051_chgIntBusUv m0 : 54|1@1+ (1,0) [0|1] "" Vector__XXX
 SG_ PCS_a052_acVoltageNotPresent m0 : 55|1@1+ (1,0) [0|1] "" Vector__XXX
 SG_ PCS_a053_chgInputVDropHigh m0 : 56|1@1+ (1,0) [0|1] "" Vector__XXX
 SG_ PCS_a054_chgInputVDropTooHigh m0 : 57|1@1+ (1,0) [0|1] "" Vector__XXX
 SG_ PCS_a055_chgLineImpedanceHigh m0 : 58|1@1+ (1,0) [0|1] "" Vector__XXX
 SG_ PCS_a056_chgLineImpedanceTooHigh m0 : 59|1@1+ (1,0) [0|1] "" Vector__XXX
 SG_ PCS_a057_chgInputOverFreq m0 : 60|1@1+ (1,0) [0|1] "" Vector__XXX
 SG_ PCS_a058_chgInputUnderFreq m0 : 61|1@1+ (1,0) [0|1] "" Vector__XXX
 SG_ PCS_a059_chgInputOvRms m0 : 62|1@1+ (1,0) [0|1] "" Vector__XXX
 SG_ PCS_a060_chgInputOvPeak m0 : 63|1@1+ (1,0) [0|1] "" Vector__XXX
 SG_ PCS_a061_chgVLineRationality m1 : 4|1@1+ (1,0) [0|1] "" Vector__XXX
 SG_ PCS_a062_chgILineRationality m1 : 5|1@1+ (1,0) [0|1] "" Vector__XXX
 SG_ PCS_a063_chgVOutRationality m1 : 6|1@1+ (1,0) [0|1] "" Vector__XXX
 SG_ PCS_a064_chgIOutRationality m1 : 7|1@1+ (1,0) [0|1] "" Vector__XXX
 SG_ PCS_a065_chgPllNotLocked m1 : 8|1@1+ (1,0) [0|1] "" Vector__XXX
 SG_ PCS_a066_dcdcHvRationality m1 : 9|1@1+ (1,0) [0|1] "" Vector__XXX
 SG_ PCS_a067_dcdcLvRationality m1 : 10|1@1+ (1,0) [0|1] "" Vector__XXX
 SG_ PCS_a068_dcdcTankvRationality m1 : 11|1@1+ (1,0) [0|1] "" Vector__XXX
 SG_ PCS_a069_chgPfcLineDidt m1 : 12|1@1+ (1,0) [0|1] "" Vector__XXX
 SG_ PCS_a070_chgPfcLineDvdt m1 : 13|1@1+ (1,0) [0|1] "" Vector__XXX
 SG_ PCS_a071_chgPfcILoopRationality m1 : 14|1@1+ (1,0) [0|1] "" Vector__XXX
 SG_ PCS_a072_cpu2ClaStopped m1 : 15|1@1+ (1,0) [0|1] "" Vector__XXX
 SG_ PCS_a073_unexpectedAcInputVoltag m1 : 16|1@1+ (1,0) [0|1] "" Vector__XXX
 SG_ PCS_a074_hvBusDischargeFailure m1 : 17|1@1+ (1,0) [0|1] "" Vector__XXX
 SG_ PCS_a075_hvBusDischargeTimeout m1 : 18|1@1+ (1,0) [0|1] "" Vector__XXX
 SG_ PCS_a076_dcdcEnDeassertedErr m1 : 19|1@1+ (1,0) [0|1] "" Vector__XXX
 SG_ PCS_a077_microGridWobbleDetected m1 : 20|1@1+ (1,0) [0|1] "" Vector__XXX
 SG_ PCS_a078_chgStopDcdcTooHot m1 : 21|1@1+ (1,0) [0|1] "" Vector__XXX
 SG_ PCS_a079_eepromOperationError m1 : 22|1@1+ (1,0) [0|1] "" Vector__XXX
 SG_ PCS_a080_damagedPhaseDetected m1 : 23|1@1+ (1,0) [0|1] "" Vector__XXX
 SG_ PCS_a081_dcdcPchgTimeout m1 : 24|1@1+ (1,0) [0|1] "" Vector__XXX
 SG_ PCS_a082_dcdcPchgUnsafeDiVoltage m1 : 25|1@1+ (1,0) [0|1] "" Vector__XXX
 SG_ PCS_a083_triggerOdin m1 : 26|1@1+ (1,0) [0|1] "" Vector__XXX
 SG_ PCS_a084_vDropFastInParasiticDio m1 : 27|1@1+ (1,0) [0|1] "" Vector__XXX
 SG_ PCS_a085_dcdcFetsNotSwitching m1 : 28|1@1+ (1,0) [0|1] "" Vector__XXX
 SG_ PCS_a086_dcdcInsufficientCooling m1 : 29|1@1+ (1,0) [0|1] "" Vector__XXX
 SG_ PCS_a087_nvramRecordStatusError m1 : 30|1@1+ (1,0) [0|1] "" Vector__XXX
 SG_ PCS_a088_gridFreqDroopDetected m1 : 31|1@1+ (1,0) [0|1] "" Vector__XXX
 SG_ PCS_a089_hvBusDischargeIrrationa m1 : 32|1@1+ (1,0) [0|1] "" Vector__XXX
 SG_ PCS_a090_expectedAcVoltageSource m1 : 33|1@1+ (1,0) [0|1] "" Vector__XXX
 SG_ PCS_a091_chgIntBusRationality m1 : 34|1@1+ (1,0) [0|1] "" Vector__XXX
 SG_ PCS_a092_chgPowerLimitedByBusRip m1 : 35|1@1+ (1,0) [0|1] "" Vector__XXX
 SG_ PCS_a093_powerRailRationality m1 : 36|1@1+ (1,0) [0|1] "" Vector__XXX
 SG_ PCS_a094_pcsDcdcNeedService m1 : 37|1@1+ (1,0) [0|1] "" Vector__XXX
 SG_ PCS_a095_dcdcSensorlessModeActiv m1 : 38|1@1+ (1,0) [0|1] "" Vector__XXX
 SG_ PCS_a096_microGridOverLoaded m1 : 39|1@1+ (1,0) [0|1] "" Vector__XXX
 SG_ PCS_a097_rebootPhaseDetected m1 : 40|1@1+ (1,0) [0|1] "" Vector__XXX
 SG_ PCS_a098_gridFreqDroopDetectedSi m1 : 41|1@1+ (1,0) [0|1] "" Vector__XXX
 SG_ PCS_a099_microGridOverLoadedSile m1 : 42|1@1+ (1,0) [0|1] "" Vector__XXX
 SG_ PCS_a100_suspectedViperChipIssue m1 : 43|1@1+ (1,0) [0|1] "" Vector__XXX
 SG_ PCS_a101_phMachineModelIrrationa m1 : 44|1@1+ (1,0) [0|1] "" Vector__XXX
 SG_ PCS_a102_resetWithDCDCCmdAsserte m1 : 45|1@1+ (1,0) [0|1] "" Vector__XXX
 SG_ PCS_a103_pchgWithLowLvDetected m1 : 46|1@1+ (1,0) [0|1] "" Vector__XXX
 SG_ PCS_a104_ambientTempRationality m1 : 47|1@1+ (1,0) [0|1] "" Vector__XXX
 SG_ PCS_a105_redundantVoltageSourceI m1 : 48|1@1+ (1,0) [0|1] "" Vector__XXX
 SG_ PCS_a106_clockSourceNotFromExter m1 : 49|1@1+ (1,0) [0|1] "" Vector__XXX
 SG_ PCS_a107_vcPcsDCDCInterfaceMia m1 : 50|1@1+ (1,0) [0|1] "" Vector__XXX
 SG_ PCS_a108_misconfigurationDetecte m1 : 51|1@1+ (1,0) [0|1] "" Vector__XXX
 SG_ PCS_a109_deltaChargingL2L3Swappe m1 : 52|1@1+ (1,0) [0|1] "" Vector__XXX
 SG_ PCS_d110_dcdcNeedsService m1 : 53|1@1+ (1,0) [0|1] "" Vector__XXX
 SG_ PCS_d111_batteryChargerPowerLimi m1 : 54|1@1+ (1,0) [0|1] "" Vector__XXX
 SG_ PCS_d112_logicHardwareIssue m1 : 55|1@1+ (1,0) [0|1] "" Vector__XXX
 SG_ PCS_d113_dcdcConverterTempSensor m1 : 56|1@1+ (1,0) [0|1] "" Vector__XXX
 SG_ PCS_d114_dcdcConverterVoltSensor m1 : 57|1@1+ (1,0) [0|1] "" Vector__XXX
 SG_ PCS_d115_dcdcConverterTempSensor m1 : 58|1@1+ (1,0) [0|1] "" Vector__XXX
 SG_ PCS_d116_dcdcConverterVoltSensor m1 : 59|1@1+ (1,0) [0|1] "" Vector__XXX

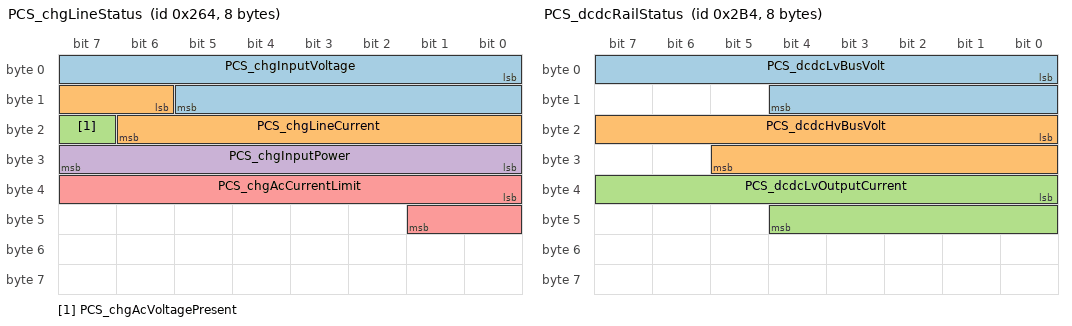
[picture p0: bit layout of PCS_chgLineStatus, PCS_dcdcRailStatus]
BO_ 612 PCS_chgLineStatus: 8 PCS
 SG_ PCS_chgInputVoltage : 0|14@1+ (0.033,0) [0|540.639] "V" Vector__XXX
 SG_ PCS_chgLineCurrent : 14|9@1+ (0.1,0) [0|50] "A" Vector__XXX
 SG_ PCS_chgAcVoltagePresent : 23|1@1+ (1,0) [0|1] "" Vector__XXX
 SG_ PCS_chgInputPower : 24|8@1+ (0.1,0) [0|20] "kW" Vector__XXX
 SG_ PCS_chgAcCurrentLimit : 32|10@1+ (0.1,0) [0|102.3] "A" Vector__XXX

BO_ 516 PCS_chgStatus: 8 PCS
 SG_ PCS_chgMainState : 0|4@1+ (1,0) [0|15] "" Vector__XXX
 SG_ PCS_powerTransferStatus : 4|2@1+ (1,0) [0|3] "" Vector__XXX
 SG_ PCS_gridConfig : 6|2@1+ (1,0) [0|3] "" Vector__XXX
 SG_ PCS_chgPHAEnable : 8|1@1+ (1,0) [0|1] "" Vector__XXX
 SG_ PCS_chgPHBEnable : 9|1@1+ (1,0) [0|1] "" Vector__XXX
 SG_ PCS_hvInletConductorEnergizedAc : 10|1@1+ (1,0) [0|1] "" Vector__XXX
 SG_ PCS_chgHighPowerActive : 11|1@1+ (1,0) [0|1] "" Vector__XXX
 SG_ PCS_chgPHCEnable : 12|1@1+ (1,0) [0|1] "" Vector__XXX
 SG_ PCS_chgInstantAcPowerAvailable : 16|8@1+ (0.1,0) [0|20] "kW" Vector__XXX
 SG_ PCS_chgMaxAcPowerAvailable : 24|8@1+ (0.1,0) [0|20] "kW" Vector__XXX
 SG_ PCS_chgPHALineCurrentRequest : 32|8@1+ (0.1,0) [0|20] "A" Vector__XXX
 SG_ PCS_chgPHBLineCurrentRequest : 40|8@1+ (0.1,0) [0|20] "A" Vector__XXX
 SG_ PCS_chgPHCLineCurrentRequest : 48|8@1+ (0.1,0) [0|20] "A" Vector__XXX
 SG_ PCS_chgPwmEnableLine : 56|1@1+ (1,0) [0|1] "" Vector__XXX
 SG_ PCS_powerTransferShutdownRequest : 57|2@1+ (1,0) [0|3] "" Vector__XXX
 SG_ PCS_hwVariantType : 59|2@1+ (1,0) [0|3] "" Vector__XXX
 SG_ PCS_dcacBidirectionalAllowed : 61|1@1+ (1,0) [0|1] "" Vector__XXX

BO_ 692 PCS_dcdcRailStatus: 8 PCS
 SG_ PCS_dcdcLvBusVolt : 0|13@1+ (0.01,0) [0|80] "V" Vector__XXX
 SG_ PCS_dcdcHvBusVolt : 16|14@1+ (0.1,0) [0|1600] "V" Vector__XXX
 SG_ PCS_dcdcLvOutputCurrent : 32|13@1- (0.1,0) [-400|400] "A" Vector__XXX

BO_ 548 PCS_dcdcStatus: 8 PCS
 SG_ PCS_dcdcPrechargeStatus : 0|2@1+ (1,0) [0|3] "" Vector__XXX
 SG_ PCS_dcdcLvSupportStatus : 2|2@1+ (1,0) [0|3] "" Vector__XXX
 SG_ PCS_dcdcHvBusDischargeStatus : 4|2@1+ (1,0) [0|3] "" Vector__XXX
 SG_ PCS_coldSleepAllowed : 8|1@1+ (1,0) [0|1] "" Vector__XXX
 SG_ PCS_dcdcPchgHVBusLowRDetected : 9|1@1+ (1,0) [0|1] "" Vector__XXX
 SG_ PCS_dcdcSubState : 10|5@1+ (1,0) [0|31] "" Vector__XXX
 SG_ PCS_dcdcFaulted : 15|1@1+ (1,0) [0|1] "" Vector__XXX
 SG_ PCS_dcdcEn13V5WithStrongPullup : 16|1@1+ (1,0) [0|1] "" Vector__XXX
 SG_ PCS_okToBePowerCycled : 27|1@1+ (1,0) [0|1] "" Vector__XXX
 SG_ PCS_dcdcOutputIsLimited : 28|1@1+ (1,0) [0|1] "" Vector__XXX
 SG_ PCS_dcdcMaxOutputCurrentAllowed : 29|12@1+ (0.1,0) [0|400] "A" Vector__XXX
 SG_ PCS_dcdcPrechargeRtyCnt : 41|3@1+ (1,0) [0|7] "" Vector__XXX
 SG_ PCS_dcdcLvSupportRtyCnt : 44|4@1+ (1,0) [0|15] "" Vector__XXX
 SG_ PCS_dcdcDischargeRtyCnt : 48|4@1+ (1,0) [0|15] "" Vector__XXX
 SG_ PCS_dcdcPwmEnableLine : 52|1@1+ (1,0) [0|1] "" Vector__XXX
 SG_ PCS_dcdcSupportingFixedLvTarget : 53|1@1+ (1,0) [0|1] "" Vector__XXX
 SG_ PCS_ecuLogUploadRequest : 54|2@1+ (1,0) [0|3] "" Vector__XXX
 SG_ PCS_dcdcPrechargeRestartCnt : 56|3@1+ (1,0) [0|7] "" Vector__XXX
 SG_ PCS_dcdcInitialPrechargeSubState : 59|5@1+ (1,0) [0|31] "" Vector__XXX

BO_ 964 PCS_info: 8 PCS
 SG_ PCS_infoIndex M : 0|8@1+ (1,0) [0|255] "" Vector__XXX
 SG_ PCS_buildType m10 : 8|8@1+ (1,0) [0|255] "" Vector__XXX
 SG_ PCS_buildConfigId m10 : 16|16@1+ (1,0) [0|65535] "" Vector__XXX
 SG_ PCS_hardwareId m10 : 32|16@1+ (1,0) [0|65535] "" Vector__XXX
 SG_ PCS_componentId m10 : 48|16@1+ (1,0) [0|65535] "" Vector__XXX
 SG_ PCS_pcbaId m11 : 16|8@1+ (1,0) [0|255] "" Vector__XXX
 SG_ PCS_assemblyId m11 : 24|8@1+ (1,0) [0|255] "" Vector__XXX
 SG_ PCS_usageId m11 : 32|16@1+ (1,0) [0|65535] "" Vector__XXX
 SG_ PCS_subUsageId m11 : 48|16@1+ (1,0) [0|65535] "" Vector__XXX
 SG_ PCS_platformType m13 : 8|8@1+ (1,0) [0|255] "" Vector__XXX
 SG_ PCS_appCrc m13 : 32|32@1+ (1,0) [0|4294967295] "" Vector__XXX
 SG_ PCS_cpu2AppCrc m16 : 32|32@1+ (1,0) [0|4294967295] "" Vector__XXX
 SG_ PCS_appGitHash m17 : 8|56@1+ (1,0) [0|7.20575940379e+16] "" Vector__XXX
 SG_ PCS_bootGitHash m18 : 8|56@1+ (1,0) [0|7.20575940379e+16] "" Vector__XXX
 SG_ PCS_bootUdsProtoVersion m20 : 8|8@1+ (1,0) [0|255] "" Vector__XXX
 SG_ PCS_bootCrc m20 : 32|32@1+ (1,0) [0|4294967295] "" Vector__XXX

BO_ 708 PCS_logging: 8 PCS
 SG_ PCS_logMessageSelect M : 0|5@1+ (1,0) [0|31] "" Vector__XXX
 SG_ PCS_chgPhAInputIrms m0 : 5|9@1+ (0.1,0) [0|51.1] "A" Vector__XXX
 SG_ PCS_chgPhAIntBusV m0 : 14|9@1+ (1,0) [0|511] "V" Vector__XXX
 SG_ PCS_chgPhAIntBusVTarget m0 : 23|9@1+ (1,0) [0|511] "V" Vector__XXX
 SG_ PCS_chgPhAOutputI m0 : 32|8@1+ (0.1,0) [0|25.5] "A" Vector__XXX
 SG_ PCS_chgPhAInputCurrentLimitReaso m0 : 40|3@1+ (1,0) [0|7] "" Vector__XXX
 SG_ PCS_chgPhBInputIrms m1 : 5|9@1+ (0.1,0) [0|51.1] "A" Vector__XXX
 SG_ PCS_chgPhBIntBusV m1 : 14|9@1+ (1,0) [0|511] "V" Vector__XXX
 SG_ PCS_chgPhBIntBusVTarget m1 : 23|9@1+ (1,0) [0|511] "V" Vector__XXX
 SG_ PCS_chgPhBOutputI m1 : 32|8@1+ (0.1,0) [0|25.5] "A" Vector__XXX
 SG_ PCS_chgPhBInputCurrentLimitReaso m1 : 40|3@1+ (1,0) [0|7] "" Vector__XXX
 SG_ PCS_chgPhCInputIrms m2 : 5|9@1+ (0.1,0) [0|51.1] "A" Vector__XXX
 SG_ PCS_chgPhCIntBusV m2 : 14|9@1+ (1,0) [0|511] "V" Vector__XXX
 SG_ PCS_chgPhCIntBusVTarget m2 : 23|9@1+ (1,0) [0|511] "V" Vector__XXX
 SG_ PCS_chgPhCOutputI m2 : 32|8@1+ (0.1,0) [0|25.5] "A" Vector__XXX
 SG_ PCS_chgPhCInputCurrentLimitReaso m2 : 40|3@1+ (1,0) [0|7] "" Vector__XXX
 SG_ PCS_chgInputL1NVrms m3 : 5|12@1+ (0.2,0) [0|819] "V" Vector__XXX
 SG_ PCS_chgInputL2NVrms m3 : 17|12@1+ (0.2,0) [0|819] "V" Vector__XXX
 SG_ PCS_chgInputL3NVrms m3 : 29|12@1+ (0.2,0) [0|819] "V" Vector__XXX
 SG_ PCS_chgInputL1L2Vrms m3 : 41|12@1+ (0.2,0) [0|819] "V" Vector__XXX
 SG_ PCS_chgInputNGVrms m3 : 53|9@1+ (1,0) [0|511] "V" Vector__XXX
 SG_ PCS_chgInputFrequencyL1N m4 : 5|12@1+ (0.01,40) [40|80.95] "Hz" Vector__XXX
 SG_ PCS_chgInputFrequencyL2N m4 : 17|12@1+ (0.01,40) [40|80.95] "Hz" Vector__XXX
 SG_ PCS_chgInputFrequencyL3N m4 : 29|12@1+ (0.01,40) [40|80.95] "Hz" Vector__XXX
 SG_ PCS_chgInternalPhaseConfig m4 : 41|4@1+ (1,0) [0|15] "" Vector__XXX
 SG_ PCS_chgPhasesPriority m4 : 45|6@1+ (1,0) [0|63] "" Vector__XXX
 SG_ PCS_chgOutputV m4 : 51|12@1+ (0.146484375,0) [0|599.853515625] "V" Vector__XXX
 SG_ PCS_chgPhAState m5 : 5|4@1+ (1,0) [0|15] "" Vector__XXX
 SG_ PCS_chgPhBState m5 : 9|4@1+ (1,0) [0|15] "" Vector__XXX
 SG_ PCS_chgPhCState m5 : 13|4@1+ (1,0) [0|15] "" Vector__XXX
 SG_ PCS_chgPhALastShutdownReason m5 : 17|5@1+ (1,0) [0|31] "" Vector__XXX
 SG_ PCS_chgPhBLastShutdownReason m5 : 22|5@1+ (1,0) [0|31] "" Vector__XXX
 SG_ PCS_chgPhCLastShutdownReason m5 : 27|5@1+ (1,0) [0|31] "" Vector__XXX
 SG_ PCS_chgPhARetryCount m5 : 32|3@1+ (1,0) [0|7] "" Vector__XXX
 SG_ PCS_chgPhBRetryCount m5 : 35|3@1+ (1,0) [0|7] "" Vector__XXX
 SG_ PCS_chgPhCRetryCount m5 : 38|3@1+ (1,0) [0|7] "" Vector__XXX
 SG_ PCS_chgRetryCount m5 : 41|3@1+ (1,0) [0|7] "" Vector__XXX
 SG_ PCS_chgPhManCurrentToDist m5 : 44|10@1+ (0.1,0) [0|100] "A" Vector__XXX
 SG_ PCS_chgL1NPllLocked m5 : 54|1@1+ (1,0) [0|1] "" Vector__XXX
 SG_ PCS_chgL2NPllLocked m5 : 55|1@1+ (1,0) [0|1] "" Vector__XXX
 SG_ PCS_chgL3NPllLocked m5 : 56|1@1+ (1,0) [0|1] "" Vector__XXX
 SG_ PCS_chgL1L2PllLocked m5 : 57|1@1+ (1,0) [0|1] "" Vector__XXX
 SG_ PCS_chgNgPllLocked m5 : 58|1@1+ (1,0) [0|1] "" Vector__XXX
 SG_ PCS_chgPhManOptimalPhsToUse m5 : 59|2@1+ (1,0) [0|3] "" Vector__XXX
 SG_ PCS_chg5VL1Enable m5 : 61|1@1+ (1,0) [0|1] "" Vector__XXX
 SG_ PCS_dcdcMaxLvOutputCurrent m6 : 8|12@1+ (0.1,0) [0|400] "A" Vector__XXX
 SG_ PCS_dcdcCurrentLimit m6 : 20|12@1+ (0.1,0) [0|400] "A" Vector__XXX
 SG_ PCS_dcdcLvOutputCurrentTempLimit m6 : 32|12@1+ (0.1,0) [0|400] "A" Vector__XXX
 SG_ PCS_dcdcLvOutputCurrentFiltered m6 : 44|12@1+ (0.1,0) [0|400] "A" Vector__XXX
 SG_ PCS_dcdcUnifiedCommand m7 : 5|10@1+ (0.001,0) [0|1] "1" Vector__XXX
 SG_ PCS_dcdcCLAControllerOutput m7 : 16|10@1+ (0.001,0) [0|1] "1" Vector__XXX
 SG_ PCS_dcdcTankVoltage m7 : 26|11@1- (1,0) [-1024|1023] "V" Vector__XXX
 SG_ PCS_dcdcTankVoltageTarget m7 : 37|10@1+ (1,0) [0|1023] "V" Vector__XXX
 SG_ PCS_dcdcClaCurrentFreq m7 : 48|12@1+ (0.09765625,0) [0|399.9] "kHz" Vector__XXX
 SG_ PCS_dcdcTCommMeasured m8 : 5|16@1- (0.001953125,0) [-64|63.998] "us" Vector__XXX
 SG_ PCS_dcdcShortTimeUs m8 : 21|16@1+ (0.00048828125,0) [0|31.9995] "us" Vector__XXX
 SG_ PCS_dcdcHalfPeriodUs m8 : 37|16@1+ (0.00048828125,0) [0|31.9995] "us" Vector__XXX
 SG_ PCS_dcdcLvBusVoltTargetWithOffse m8 : 53|11@1+ (0.01,0) [0|20] "V" Vector__XXX
 SG_ PCS_cpu2BootState m9 : 5|2@1+ (1,0) [0|3] "" Vector__XXX
 SG_ PCS_acChargeSelfTestState m9 : 7|1@1+ (1,0) [0|1] "" Vector__XXX
 SG_ PCS_1V5Min10s m9 : 8|11@1+ (0.001,0) [0|2.047] "V" Vector__XXX
 SG_ PCS_1V5Max10s m9 : 19|11@1+ (0.001,0) [0|2.047] "V" Vector__XXX
 SG_ PCS_1V2Min10s m9 : 32|11@1+ (0.001,0) [0|2.047] "V" Vector__XXX
 SG_ PCS_1V2Max10s m9 : 43|11@1+ (0.001,0) [0|2.047] "V" Vector__XXX
 SG_ PCS_5VNMax10s m9 : 54|10@1+ (0.01,0) [0|10.23] "V" Vector__XXX
 SG_ PCS_chgPhAIntBusVMin10s m10 : 5|9@1+ (1,0) [0|511] "V" Vector__XXX
 SG_ PCS_chgPhAIntBusVMax10s m10 : 14|9@1+ (1,0) [0|511] "V" Vector__XXX
 SG_ PCS_chgPhAPchgVoltDeltaMax10s m10 : 23|8@1+ (0.5,0) [0|127.5] "V" Vector__XXX
 SG_ PCS_chgPhALifetimekWh m10 : 31|24@1+ (0.01,0) [0|167772.15] "kWh" Vector__XXX
 SG_ PCS_chgPhATransientRetryCount m10 : 55|9@1+ (0.1,0) [0|51.1] "-" Vector__XXX
 SG_ PCS_chgPhBIntBusVMin10s m11 : 5|9@1+ (1,0) [0|511] "V" Vector__XXX
 SG_ PCS_chgPhBIntBusVMax10s m11 : 14|9@1+ (1,0) [0|511] "V" Vector__XXX
 SG_ PCS_chgPhBPchgVoltDeltaMax10s m11 : 23|8@1+ (0.5,0) [0|127.5] "V" Vector__XXX
 SG_ PCS_chgPhBLifetimekWh m11 : 31|24@1+ (0.01,0) [0|167772.15] "kWh" Vector__XXX
 SG_ PCS_chgPhBTransientRetryCount m11 : 55|9@1+ (0.1,0) [0|51.1] "-" Vector__XXX
 SG_ PCS_chgPhCIntBusVMin10s m12 : 5|9@1+ (1,0) [0|511] "V" Vector__XXX
 SG_ PCS_chgPhCIntBusVMax10s m12 : 14|9@1+ (1,0) [0|511] "V" Vector__XXX
 SG_ PCS_chgPhCPchgVoltDeltaMax10s m12 : 23|8@1+ (0.5,0) [0|127.5] "V" Vector__XXX
 SG_ PCS_chgPhCLifetimekWh m12 : 31|24@1+ (0.01,0) [0|167772.15] "kWh" Vector__XXX
 SG_ PCS_chgPhCTransientRetryCount m12 : 55|9@1+ (0.1,0) [0|51.1] "-" Vector__XXX
 SG_ PCS_chgPhANoFlowBucket m20 : 5|9@1+ (0.01,0) [0|5.11] "-" Vector__XXX
 SG_ PCS_chgPhBNoFlowBucket m20 : 14|9@1+ (0.01,0) [0|5.11] "-" Vector__XXX
 SG_ PCS_chgPhCNoFlowBucket m20 : 23|9@1+ (0.01,0) [0|5.11] "-" Vector__XXX
 SG_ PCS_chgCurrentSensorOutOfBandUs m20 : 32|10@1+ (0.01,0) [0|10.23] "us" Vector__XXX
 SG_ PCS_chgAcpwHeartbeatState m20 : 42|3@1+ (1,0) [0|7] "" Vector__XXX
 SG_ PCS_chgKwhLostByFreqDroop m20 : 48|8@1+ (0.1,0) [0|25.5] "kWh" Vector__XXX
 SG_ PCS_chgReqKwhLostByFreqDroop m20 : 56|8@1+ (0.1,0) [0|25.5] "kWh" Vector__XXX
 SG_ PCS_dcdcLvSupportLifetimekWh m22 : 8|24@1+ (0.01,0) [0|167772.15] "kWh" Vector__XXX
 SG_ PCS_chgPwmEnableLineErrorCount m22 : 32|10@1+ (1,0) [0|1023] "" Vector__XXX
 SG_ PCS_dcdcPwmEnableLineErrorCount m22 : 42|10@1+ (1,0) [0|1023] "" Vector__XXX
 SG_ PCS_numAlertsSet m22 : 56|7@1+ (1,0) [0|127] "" Vector__XXX
 SG_ PCS_dcdcPchgStartLvBusVolt m24 : 5|10@1+ (0.0390625,0) [0|39.9609375] "V" Vector__XXX
 SG_ PCS_dcdcPchgStartHvBusVolt m24 : 16|12@1+ (0.146484375,0) [0|599.853515625] "V" Vector__XXX
 SG_ PCS_dcdcHvBusEstimated_C_uF m24 : 28|10@1+ (7.820137,0) [0|8000] "uF" Vector__XXX
 SG_ PCS_dcdcHvBusEstimated_R_kOhm m24 : 38|10@1+ (0.0488758571446,0) [0|50] "kOhm" Vector__XXX
 SG_ PCS_processorDieIdLot m25 : 8|24@1+ (1,0) [0|16777215] "" Vector__XXX
 SG_ PCS_processorDieIdWafer m25 : 32|8@1+ (1,0) [0|255] "" Vector__XXX
 SG_ PCS_processorDieIdX m25 : 40|12@1+ (1,0) [0|4095] "" Vector__XXX
 SG_ PCS_processorDieIdY m25 : 52|12@1+ (1,0) [0|4095] "" Vector__XXX

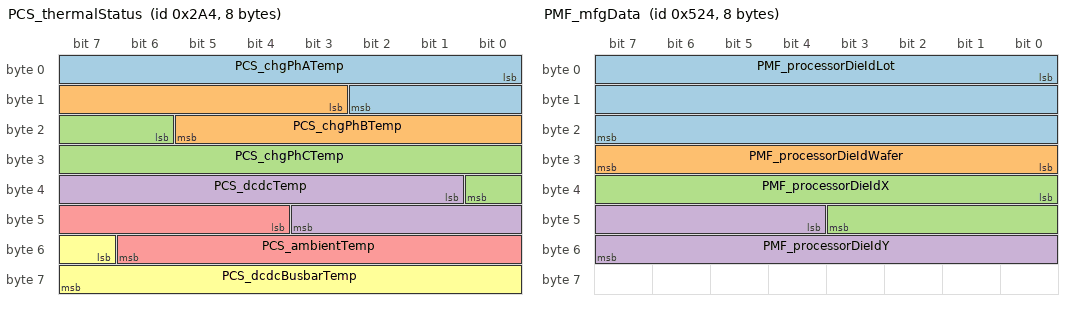
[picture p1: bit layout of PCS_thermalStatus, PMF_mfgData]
BO_ 676 PCS_thermalStatus: 8 PCS
 SG_ PCS_chgPhATemp : 0|11@1- (0.1,40) [-62.4|142.3] "C" Vector__XXX
 SG_ PCS_chgPhBTemp : 11|11@1- (0.1,40) [-62.4|142.3] "C" Vector__XXX
 SG_ PCS_chgPhCTemp : 22|11@1- (0.1,40) [-62.4|142.3] "C" Vector__XXX
 SG_ PCS_dcdcTemp : 33|11@1- (0.1,40) [-62.4|142.3] "C" Vector__XXX
 SG_ PCS_ambientTemp : 44|11@1- (0.1,40) [-62.4|142.3] "C" Vector__XXX
 SG_ PCS_dcdcBusbarTemp : 55|9@1+ (0.2935421,0) [0|150] "C" Vector__XXX

BO_ 1317 PMF_alertLog: 8 PMF
 SG_ PMF_alertID M : 0|7@1+ (1,0) [0|127] "" Vector__XXX
 SG_ PMF_alertState : 15|1@1+ (1,0) [0|1] "" Vector__XXX
 SG_ PMF_a001_w0 m1 : 16|16@1+ (1,0) [0|65535] "" Vector__XXX
 SG_ PMF_a001_w1 m1 : 32|16@1+ (1,0) [0|65535] "" Vector__XXX
 SG_ PMF_a001_w2 m1 : 48|16@1+ (1,0) [0|65535] "" Vector__XXX
 SG_ PMF_a002_torqueAverage m2 : 16|1@1+ (1,0) [0|1] "" Vector__XXX
 SG_ PMF_a002_torqueWindow m2 : 17|1@1+ (1,0) [0|1] "" Vector__XXX
 SG_ PMF_a002_torqueMeasured m2 : 18|13@1- (2,0) [-8192|8190] "" Vector__XXX
 SG_ PMF_a002_torqueAccelAverage m2 : 32|13@1- (2,0) [-8192|8190] "" Vector__XXX
 SG_ PMF_a002_torqueAccelWindow m2 : 48|13@1- (2,0) [-8192|8190] "" Vector__XXX
 SG_ PMF_a003_reverseGear m3 : 16|1@1+ (1,0) [0|1] "" Vector__XXX
 SG_ PMF_a003_pedalPos m3 : 24|8@1+ (0.4,0) [0|102] "" Vector__XXX
 SG_ PMF_a003_zeroPointPedal m3 : 32|8@1+ (0.4,0) [0|102] "" Vector__XXX
 SG_ PMF_a004_torqueAverage m4 : 16|1@1+ (1,0) [0|1] "" Vector__XXX
 SG_ PMF_a004_torqueWindow m4 : 17|1@1+ (1,0) [0|1] "" Vector__XXX
 SG_ PMF_a004_torqueMeasured m4 : 18|13@1- (2,0) [-8192|8190] "" Vector__XXX
 SG_ PMF_a004_torqueDecelAverage m4 : 32|13@1- (2,0) [-8192|8190] "" Vector__XXX
 SG_ PMF_a004_torqueDecelWindow m4 : 48|13@1- (2,0) [-8192|8190] "" Vector__XXX
 SG_ PMF_a005_torqueReason m5 : 16|2@1+ (1,0) [0|3] "" Vector__XXX
 SG_ PMF_a005_torqueMeasured m5 : 18|13@1- (2,0) [-8192|8190] "" Vector__XXX
 SG_ PMF_a005_iDQmagnitude m5 : 32|16@1- (0.0939,0) [-3076.9152|3076.8213] "" Vector__XXX
 SG_ PMF_a006_torqueActual m6 : 16|13@1- (2,0) [-8192|8190] "" Vector__XXX
 SG_ PMF_a006_motorRPM m6 : 32|16@1- (1,0) [-32768|32767] "" Vector__XXX
 SG_ PMF_a006_torqueMeasured m6 : 48|13@1- (2,0) [-8192|8190] "" Vector__XXX
 SG_ PMF_a010_messageId m10 : 16|16@1+ (1,0) [0|65535] "" Vector__XXX
 SG_ PMF_a010_DI_status m10 : 32|1@1+ (1,0) [0|1] "" Vector__XXX
 SG_ PMF_a010_DI_torque m10 : 33|1@1+ (1,0) [0|1] "" Vector__XXX
 SG_ PMF_a010_DI_slaveCommand m10 : 34|1@1+ (1,0) [0|1] "" Vector__XXX
 SG_ PMF_a010_DI_locStatus m10 : 35|1@1+ (1,0) [0|1] "" Vector__XXX
 SG_ PMF_a010_DI_speed m10 : 36|1@1+ (1,0) [0|1] "" Vector__XXX
 SG_ PMF_a010_DI_systemStatus m10 : 37|1@1+ (1,0) [0|1] "" Vector__XXX
 SG_ PMF_a010_DI_chassisControl m10 : 38|1@1+ (1,0) [0|1] "" Vector__XXX
 SG_ PMF_a010_DI_chassisControl2 m10 : 39|1@1+ (1,0) [0|1] "" Vector__XXX
 SG_ PMF_a010_vdcLeft m10 : 40|1@1+ (1,0) [0|1] "" Vector__XXX
 SG_ PMF_a010_vdcRight m10 : 41|1@1+ (1,0) [0|1] "" Vector__XXX
 SG_ PMF_a010_DI_vehicleEstimates m10 : 42|1@1+ (1,0) [0|1] "" Vector__XXX
 SG_ PMF_a010_DI_brakeCommand m10 : 43|1@1+ (1,0) [0|1] "" Vector__XXX
 SG_ PMF_a010_DI_autonomyHealth m10 : 44|1@1+ (1,0) [0|1] "" Vector__XXX
 SG_ PMF_a010_DI_difCommand m10 : 45|1@1+ (1,0) [0|1] "" Vector__XXX
 SG_ PMF_a010_DI_dirCommand m10 : 46|1@1+ (1,0) [0|1] "" Vector__XXX
 SG_ PMF_a010_DI_dirVehicle m10 : 47|1@1+ (1,0) [0|1] "" Vector__XXX
 SG_ PMF_a010_DI_locStatus2 m10 : 48|1@1+ (1,0) [0|1] "" Vector__XXX
 SG_ PMF_a011_Ia m11 : 16|9@1- (12.0192,0) [-3076.9152|3064.896] "" Vector__XXX
 SG_ PMF_a011_IaDelta m11 : 25|8@1- (24.0384,0) [-3076.9152|3052.8768] "" Vector__XXX
 SG_ PMF_a011_Ib m11 : 33|9@1- (12.0192,0) [-3076.9152|3064.896] "" Vector__XXX
 SG_ PMF_a011_IbDelta m11 : 42|8@1- (24.0384,0) [-3076.9152|3052.8768] "" Vector__XXX
 SG_ PMF_a011_currentVref m11 : 50|8@1+ (0.04,0) [0|10.2] "" Vector__XXX
 SG_ PMF_a011_badPhaseAsample m11 : 58|1@1+ (1,0) [0|1] "" Vector__XXX
 SG_ PMF_a011_badPhaseBsample m11 : 59|1@1+ (1,0) [0|1] "" Vector__XXX
 SG_ PMF_a011_sampleFreeze m11 : 60|1@1+ (1,0) [0|1] "" Vector__XXX
 SG_ PMF_a011_rateOfChangeIrrational m11 : 61|1@1+ (1,0) [0|1] "" Vector__XXX
 SG_ PMF_a011_currentReadingIrrationa m11 : 62|1@1+ (1,0) [0|1] "" Vector__XXX
 SG_ PMF_a011_vrefIrrational m11 : 63|1@1+ (1,0) [0|1] "" Vector__XXX
 SG_ PMF_a017_EPBL_status m17 : 16|1@1+ (1,0) [0|1] "" Vector__XXX
 SG_ PMF_a017_EPBR_status m17 : 17|1@1+ (1,0) [0|1] "" Vector__XXX
 SG_ PMF_a017_EPBL_autonomyHealth m17 : 18|1@1+ (1,0) [0|1] "" Vector__XXX
 SG_ PMF_a017_EPBR_autonomyHealth m17 : 19|1@1+ (1,0) [0|1] "" Vector__XXX
 SG_ PMF_a018_w0 m18 : 16|16@1+ (1,0) [0|65535] "" Vector__XXX
 SG_ PMF_a018_w1 m18 : 32|16@1+ (1,0) [0|65535] "" Vector__XXX
 SG_ PMF_a018_w2 m18 : 48|16@1+ (1,0) [0|65535] "" Vector__XXX
 SG_ PMF_a019_statorTemp1 m19 : 16|16@1- (0.1,0) [-3276.8|3276.7] "" Vector__XXX
 SG_ PMF_a019_statorTslope1 m19 : 32|16@1- (0.1,0) [-3276.8|3276.7] "" Vector__XXX
 SG_ PMF_a025_sccReset m25 : 16|1@1+ (1,0) [0|1] "" Vector__XXX
 SG_ PMF_a025_hibernate m25 : 17|1@1+ (1,0) [0|1] "" Vector__XXX
 SG_ PMF_a025_hwBist m25 : 18|1@1+ (1,0) [0|1] "" Vector__XXX
 SG_ PMF_a025_nmiWatchdog m25 : 19|1@1+ (1,0) [0|1] "" Vector__XXX
 SG_ PMF_a025_watchdog m25 : 20|1@1+ (1,0) [0|1] "" Vector__XXX
 SG_ PMF_a025_clockFailNmi m25 : 21|1@1+ (1,0) [0|1] "" Vector__XXX
 SG_ PMF_a025_ramUncErrorNmi m25 : 22|1@1+ (1,0) [0|1] "" Vector__XXX
 SG_ PMF_a025_flashUncErrorNmi m25 : 23|1@1+ (1,0) [0|1] "" Vector__XXX
 SG_ PMF_a025_cpu1signMismatchNmi m25 : 24|1@1+ (1,0) [0|1] "" Vector__XXX
 SG_ PMF_a025_cpu2signMismatchNmi m25 : 25|1@1+ (1,0) [0|1] "" Vector__XXX
 SG_ PMF_a025_pieVectErrorNmi m25 : 26|1@1+ (1,0) [0|1] "" Vector__XXX
 SG_ PMF_a025_sysDbgNmi m25 : 27|1@1+ (1,0) [0|1] "" Vector__XXX
 SG_ PMF_a025_rlNmi m25 : 28|1@1+ (1,0) [0|1] "" Vector__XXX
 SG_ PMF_a025_ovfNmi m25 : 29|1@1+ (1,0) [0|1] "" Vector__XXX
 SG_ PMF_a025_possibleSafetyICReset m25 : 30|1@1+ (1,0) [0|1] "" Vector__XXX
 SG_ PMF_a025_powerOnReset m25 : 31|1@1+ (1,0) [0|1] "" Vector__XXX
 SG_ PMF_a025_watchdogTimer0 m25 : 32|1@1+ (1,0) [0|1] "" Vector__XXX
 SG_ PMF_a025_watchdogTimer1 m25 : 33|1@1+ (1,0) [0|1] "" Vector__XXX
 SG_ PMF_a025_watchdogTimer2 m25 : 34|1@1+ (1,0) [0|1] "" Vector__XXX
 SG_ PMF_a025_watchdogTimer3 m25 : 35|1@1+ (1,0) [0|1] "" Vector__XXX
 SG_ PMF_a025_warmResetReq m25 : 36|1@1+ (1,0) [0|1] "" Vector__XXX
 SG_ PMF_a025_externalPadReset m25 : 37|1@1+ (1,0) [0|1] "" Vector__XXX
 SG_ PMF_a025_hwSecModuleWatchdogTime m25 : 38|1@1+ (1,0) [0|1] "" Vector__XXX
 SG_ PMF_a025_debugReset m25 : 39|1@1+ (1,0) [0|1] "" Vector__XXX
 SG_ PMF_a025_tempSense0 m25 : 40|1@1+ (1,0) [0|1] "" Vector__XXX
 SG_ PMF_a025_tempSense1 m25 : 41|1@1+ (1,0) [0|1] "" Vector__XXX
 SG_ PMF_a026_reason m26 : 16|1@1+ (1,0) [0|1] "" Vector__XXX
 SG_ PMF_a026_isrCount20kHz m26 : 17|5@1+ (1,0) [0|31] "" Vector__XXX
 SG_ PMF_a026_isrCount1kHz m26 : 22|4@1+ (1,0) [0|15] "" Vector__XXX
 SG_ PMF_a026_switchingActive m26 : 26|1@1+ (1,0) [0|1] "" Vector__XXX
 SG_ PMF_a026_systemStackOvf m26 : 27|1@1+ (1,0) [0|1] "" Vector__XXX
 SG_ PMF_a026_controlStackOvf m26 : 28|1@1+ (1,0) [0|1] "" Vector__XXX
 SG_ PMF_a026_idleStackOvf m26 : 29|1@1+ (1,0) [0|1] "" Vector__XXX
 SG_ PMF_a026_eepStackOvf m26 : 30|1@1+ (1,0) [0|1] "" Vector__XXX
 SG_ PMF_a026_immStackOvf m26 : 31|1@1+ (1,0) [0|1] "" Vector__XXX
 SG_ PMF_a026_xdcErrorIdMSW m26 : 32|10@1+ (1,0) [0|1023] "" Vector__XXX
 SG_ PMF_a026_xdcErrorArg1 m26 : 42|22@1- (1,0) [-2097152|2097151] "" Vector__XXX
 SG_ PMF_a032_w0 m32 : 16|16@1+ (1,0) [0|65535] "" Vector__XXX
 SG_ PMF_a032_w1 m32 : 32|16@1+ (1,0) [0|65535] "" Vector__XXX
 SG_ PMF_a032_w2 m32 : 48|16@1+ (1,0) [0|65535] "" Vector__XXX
 SG_ PMF_a033_state m33 : 16|4@1+ (1,0) [0|15] "" Vector__XXX
 SG_ PMF_a033_failReason m33 : 20|3@1+ (1,0) [0|7] "" Vector__XXX
 SG_ PMF_a033_DSADC_Ia m33 : 24|16@1- (0.0939,0) [-3076.9152|3076.8213] "" Vector__XXX
 SG_ PMF_a033_DSADC_Ib m33 : 40|16@1- (0.0939,0) [-3076.9152|3076.8213] "" Vector__XXX
 SG_ PMF_a036_timeSinceTxHWI m36 : 16|6@1+ (64,0) [0|4032] "" Vector__XXX
 SG_ PMF_a036_timeSinceRxHWI m36 : 22|6@1+ (64,0) [0|4032] "" Vector__XXX
 SG_ PMF_a036_timeSince100HzTxSWI m36 : 28|6@1+ (0.32,0) [0|20.16] "" Vector__XXX
 SG_ PMF_a036_timeSince1kHzCLK m36 : 34|6@1+ (32,0) [0|2016] "" Vector__XXX
 SG_ PMF_a036_timeSince1kHzSWI m36 : 40|6@1+ (32,0) [0|2016] "" Vector__XXX
 SG_ PMF_a036_timeSinceIdle m36 : 46|6@1+ (0.16,0) [0|10.08] "" Vector__XXX
 SG_ PMF_a036_ovfStackId m36 : 52|4@1+ (1,0) [0|15] "" Vector__XXX
 SG_ PMF_a036_inTxISR m36 : 56|1@1+ (1,0) [0|1] "" Vector__XXX
 SG_ PMF_a036_inTxHWI m36 : 57|1@1+ (1,0) [0|1] "" Vector__XXX
 SG_ PMF_a036_inRxHWI m36 : 58|1@1+ (1,0) [0|1] "" Vector__XXX
 SG_ PMF_a036_in1kHzSWI m36 : 59|1@1+ (1,0) [0|1] "" Vector__XXX
 SG_ PMF_a036_in1kHzCLK m36 : 60|1@1+ (1,0) [0|1] "" Vector__XXX
 SG_ PMF_a036_in100HzCLK m36 : 61|1@1+ (1,0) [0|1] "" Vector__XXX
 SG_ PMF_a036_in10HzCLK m36 : 62|1@1+ (1,0) [0|1] "" Vector__XXX
 SG_ PMF_a036_in1HzCLK m36 : 63|1@1+ (1,0) [0|1] "" Vector__XXX
 SG_ PMF_a037_hvpFaults m37 : 16|1@1+ (1,0) [0|1] "" Vector__XXX
 SG_ PMF_a039_DIS_status m39 : 16|1@1+ (1,0) [0|1] "" Vector__XXX
 SG_ PMF_a039_DIS_torque m39 : 17|1@1+ (1,0) [0|1] "" Vector__XXX
 SG_ PMF_a039_messageId m39 : 24|16@1+ (1,0) [0|65535] "" Vector__XXX
 SG_ PMF_a040_PM_state m40 : 16|1@1+ (1,0) [0|1] "" Vector__XXX
 SG_ PMF_a040_messageId m40 : 24|16@1+ (1,0) [0|65535] "" Vector__XXX
 SG_ PMF_a040_PM_locState m40 : 40|1@1+ (1,0) [0|1] "" Vector__XXX
 SG_ PMF_a042_GTW_carConfig m42 : 16|1@1+ (1,0) [0|1] "" Vector__XXX
 SG_ PMF_a042_GTW_time m42 : 17|1@1+ (1,0) [0|1] "" Vector__XXX
 SG_ PMF_a042_GTW_drivetrainType m42 : 18|3@1+ (1,0) [0|7] "" Vector__XXX
 SG_ PMF_a042_expectedPerformanceCfg m42 : 21|3@1+ (1,0) [0|7] "" Vector__XXX
 SG_ PMF_a042_gearControl m42 : 24|1@1+ (1,0) [0|1] "" Vector__XXX
 SG_ PMF_a053_LVPowerState m53 : 16|1@1+ (1,0) [0|1] "" Vector__XXX
 SG_ PMF_a053_coolant m53 : 17|1@1+ (1,0) [0|1] "" Vector__XXX
 SG_ PMF_a053_vcleftSwitchStatus m53 : 18|1@1+ (1,0) [0|1] "" Vector__XXX
 SG_ PMF_a053_restraintStatus m53 : 19|1@1+ (1,0) [0|1] "" Vector__XXX
 SG_ PMF_a053_sensors m53 : 20|1@1+ (1,0) [0|1] "" Vector__XXX
 SG_ PMF_a054_uiPowertrainControl m54 : 16|1@1+ (1,0) [0|1] "" Vector__XXX
 SG_ PMF_a054_uiChassisControl m54 : 17|1@1+ (1,0) [0|1] "" Vector__XXX
 SG_ PMF_a054_uiCruiseControl m54 : 18|1@1+ (1,0) [0|1] "" Vector__XXX
 SG_ PMF_a054_uiTrackModeSettings m54 : 19|1@1+ (1,0) [0|1] "" Vector__XXX
 SG_ PMF_a054_uiTPMSRCPSetting m54 : 20|1@1+ (1,0) [0|1] "" Vector__XXX
 SG_ PMF_a055_motorRPM m55 : 16|16@1- (1,0) [-32768|32767] "" Vector__XXX
 SG_ PMF_a055_phaseAngle m55 : 32|8@1+ (0.00308,0) [0|0.7854] "" Vector__XXX
 SG_ PMF_a055_commonGain m55 : 40|8@1+ (0.02,0) [0|5.1] "" Vector__XXX
 SG_ PMF_a055_notReady m55 : 48|1@1+ (1,0) [0|1] "" Vector__XXX
 SG_ PMF_a055_noCarrier m55 : 49|1@1+ (1,0) [0|1] "" Vector__XXX
 SG_ PMF_a055_phaseOutOfSpec m55 : 50|1@1+ (1,0) [0|1] "" Vector__XXX
 SG_ PMF_a055_diElecAngleMismatch m55 : 51|1@1+ (1,0) [0|1] "" Vector__XXX
 SG_ PMF_a055_diSpeedMismatch m55 : 52|1@1+ (1,0) [0|1] "" Vector__XXX
 SG_ PMF_a055_claMIA m55 : 53|1@1+ (1,0) [0|1] "" Vector__XXX
 SG_ PMF_a055_diMIA m55 : 54|1@1+ (1,0) [0|1] "" Vector__XXX
 SG_ PMF_a055_diElecAngleMismatchWarn m55 : 55|1@1+ (1,0) [0|1] "" Vector__XXX
 SG_ PMF_a058_hvilCurrent m58 : 16|8@1+ (0.1,0) [0|25.5] "" Vector__XXX
 SG_ PMF_a061_diIpcVersion m61 : 16|8@1+ (1,0) [0|255] "" Vector__XXX
 SG_ PMF_a061_pmIpcVersion m61 : 24|8@1+ (1,0) [0|255] "" Vector__XXX
 SG_ PMF_a062_address m62 : 16|32@1+ (1,0) [0|4294967295] "" Vector__XXX
 SG_ PMF_a062_errorType m62 : 48|4@1+ (1,0) [0|15] "" Vector__XXX
 SG_ PMF_a062_detectedByRamScrub m62 : 52|1@1+ (1,0) [0|1] "" Vector__XXX
 SG_ PMF_a064_interventionType m64 : 16|4@1+ (1,0) [0|15] "" Vector__XXX
 SG_ PMF_a064_torqueCmdState m64 : 20|4@1+ (1,0) [0|15] "" Vector__XXX
 SG_ PMF_a064_shortDetectedByDI m64 : 24|1@1+ (1,0) [0|1] "" Vector__XXX
 SG_ PMF_a064_UI_stoppingMode m64 : 25|2@1+ (1,0) [0|3] "" Vector__XXX
 SG_ PMF_a064_diCrsState m64 : 27|3@1+ (1,0) [0|7] "" Vector__XXX
 SG_ PMF_a064_pmCrsState m64 : 32|3@1+ (1,0) [0|7] "" Vector__XXX
 SG_ PMF_a082_faultAddress m82 : 16|32@1+ (1,0) [0|4294967295] "" Vector__XXX
 SG_ PMF_a082_isWriteNotRead m82 : 48|1@1+ (1,0) [0|1] "" Vector__XXX
 SG_ PMF_a084_faultAddress m84 : 16|32@1+ (1,0) [0|4294967295] "" Vector__XXX
 SG_ PMF_a084_firewallId m84 : 48|5@1+ (1,0) [0|31] "" Vector__XXX
 SG_ PMF_a084_privId m84 : 56|4@1+ (1,0) [0|15] "" Vector__XXX
 SG_ PMF_a084_ns m84 : 60|1@1+ (1,0) [0|1] "" Vector__XXX
 SG_ PMF_a084_faultType m84 : 61|3@1+ (1,0) [0|7] "" Vector__XXX
 SG_ PMF_a092_pllClockSource m92 : 16|2@1+ (1,0) [0|3] "" Vector__XXX
 SG_ PMF_a095_wwdErrIntFlag m95 : 16|1@1+ (1,0) [0|1] "" Vector__XXX
 SG_ PMF_a095_fwdErrIntFlag m95 : 17|1@1+ (1,0) [0|1] "" Vector__XXX
 SG_ PMF_a095_errMissStsFlag m95 : 18|1@1+ (1,0) [0|1] "" Vector__XXX
 SG_ PMF_a095_preRegulatorOT m95 : 19|1@1+ (1,0) [0|1] "" Vector__XXX
 SG_ PMF_a095_ucLdoOT m95 : 20|1@1+ (1,0) [0|1] "" Vector__XXX
 SG_ PMF_a095_monitoringOT m95 : 21|1@1+ (1,0) [0|1] "" Vector__XXX
 SG_ PMF_a095_preRegulatorVoltShort m95 : 22|1@1+ (1,0) [0|1] "" Vector__XXX
 SG_ PMF_a095_ucLdoShort m95 : 23|1@1+ (1,0) [0|1] "" Vector__XXX
 SG_ PMF_a095_standbyLdoShort m95 : 24|1@1+ (1,0) [0|1] "" Vector__XXX
 SG_ PMF_a095_coreVoltShort m95 : 25|1@1+ (1,0) [0|1] "" Vector__XXX
 SG_ PMF_a095_preRegulatorOV m95 : 26|1@1+ (1,0) [0|1] "" Vector__XXX
 SG_ PMF_a095_ucLdoOV m95 : 27|1@1+ (1,0) [0|1] "" Vector__XXX
 SG_ PMF_a095_standbyLdoOV m95 : 28|1@1+ (1,0) [0|1] "" Vector__XXX
 SG_ PMF_a095_coreOV m95 : 29|1@1+ (1,0) [0|1] "" Vector__XXX
 SG_ PMF_a095_voltRefOV m95 : 30|1@1+ (1,0) [0|1] "" Vector__XXX
 SG_ PMF_a095_ucLdoUV m95 : 31|1@1+ (1,0) [0|1] "" Vector__XXX
 SG_ PMF_a095_standbyLdoUV m95 : 32|1@1+ (1,0) [0|1] "" Vector__XXX
 SG_ PMF_a095_coreUV m95 : 33|1@1+ (1,0) [0|1] "" Vector__XXX
 SG_ PMF_a095_supplyVoltOV m95 : 34|1@1+ (1,0) [0|1] "" Vector__XXX
 SG_ PMF_a095_bandgapComparatorUV m95 : 35|1@1+ (1,0) [0|1] "" Vector__XXX
 SG_ PMF_a095_bandgapComparatorOV m95 : 36|1@1+ (1,0) [0|1] "" Vector__XXX
 SG_ PMF_a095_biasCurrentTooLow m95 : 37|1@1+ (1,0) [0|1] "" Vector__XXX
 SG_ PMF_a095_biasCurrentTooHigh m95 : 38|1@1+ (1,0) [0|1] "" Vector__XXX
 SG_ PMF_a095_safetyICstate m95 : 40|3@1+ (1,0) [0|7] "" Vector__XXX
 SG_ PMF_a095_motorRPM m95 : 43|12@1- (10,0) [-20480|20470] "" Vector__XXX
 SG_ PMF_a095_wwdErrCounter m95 : 56|4@1+ (1,0) [0|15] "" Vector__XXX
 SG_ PMF_a095_fwdErrCounter m95 : 60|4@1+ (1,0) [0|15] "" Vector__XXX
 SG_ PMF_a100_index1kHzPeriodic m100 : 16|8@1+ (1,0) [0|255] "" Vector__XXX
 SG_ PMF_a100_index100HzPeriodic m100 : 24|8@1+ (1,0) [0|255] "" Vector__XXX
 SG_ PMF_a100_index10HzPeriodic m100 : 32|8@1+ (1,0) [0|255] "" Vector__XXX
 SG_ PMF_a100_indexSWI m100 : 40|8@1+ (1,0) [0|255] "" Vector__XXX
 SG_ PMF_a100_eepEvent m100 : 48|8@1+ (1,0) [0|255] "" Vector__XXX
 SG_ PMF_a100_module500HzActive m100 : 56|1@1+ (1,0) [0|1] "" Vector__XXX
 SG_ PMF_a100_module50HzActive m100 : 57|1@1+ (1,0) [0|1] "" Vector__XXX
 SG_ PMF_a100_module1HzActive m100 : 58|1@1+ (1,0) [0|1] "" Vector__XXX
 SG_ PMF_a100_task10HzActive m100 : 59|1@1+ (1,0) [0|1] "" Vector__XXX
 SG_ PMF_a100_taskUdsActive m100 : 60|1@1+ (1,0) [0|1] "" Vector__XXX

BO_ 772 PMF_alertMatrix: 8 PMF
 SG_ PMF_matrixIndex M : 0|4@1+ (1,0) [0|15] "" Vector__XXX
 SG_ PMF_a001_absoluteTorque m0 : 4|1@1+ (1,0) [0|1] "" Vector__XXX
 SG_ PMF_a002_excessiveAccelTorque m0 : 5|1@1+ (1,0) [0|1] "" Vector__XXX
 SG_ PMF_a003_excessiveReversalTorque m0 : 6|1@1+ (1,0) [0|1] "" Vector__XXX
 SG_ PMF_a004_excessiveDecelTorque m0 : 7|1@1+ (1,0) [0|1] "" Vector__XXX
 SG_ PMF_a005_torqueInNeutralOrPark m0 : 8|1@1+ (1,0) [0|1] "" Vector__XXX
 SG_ PMF_a006_underTorqueCheck m0 : 9|1@1+ (1,0) [0|1] "" Vector__XXX
 SG_ PMF_a008_memoryError m0 : 11|1@1+ (1,0) [0|1] "" Vector__XXX
 SG_ PMF_a010_diMIA m0 : 13|1@1+ (1,0) [0|1] "" Vector__XXX
 SG_ PMF_a011_phaseCurrentIrrational m0 : 14|1@1+ (1,0) [0|1] "" Vector__XXX
 SG_ PMF_a012_canDataBusA m0 : 15|1@1+ (1,0) [0|1] "" Vector__XXX
 SG_ PMF_a013_canHardwareBusA m0 : 16|1@1+ (1,0) [0|1] "" Vector__XXX
 SG_ PMF_a017_brakeMIA m0 : 20|1@1+ (1,0) [0|1] "" Vector__XXX
 SG_ PMF_a018_encoderIrrational m0 : 21|1@1+ (1,0) [0|1] "" Vector__XXX
 SG_ PMF_a019_statorTempIrrational m0 : 22|1@1+ (1,0) [0|1] "" Vector__XXX
 SG_ PMF_a025_unintendedReset m0 : 28|1@1+ (1,0) [0|1] "" Vector__XXX
 SG_ PMF_a026_diHeartBeatMIA m0 : 29|1@1+ (1,0) [0|1] "" Vector__XXX
 SG_ PMF_a027_torqueEstimationOutOfBo m0 : 30|1@1+ (1,0) [0|1] "" Vector__XXX
 SG_ PMF_a028_torqueCmdError m0 : 31|1@1+ (1,0) [0|1] "" Vector__XXX
 SG_ PMF_a031_highStackUsage m0 : 34|1@1+ (1,0) [0|1] "" Vector__XXX
 SG_ PMF_a032_registerConfigError m0 : 35|1@1+ (1,0) [0|1] "" Vector__XXX
 SG_ PMF_a033_selfTest m0 : 36|1@1+ (1,0) [0|1] "" Vector__XXX
 SG_ PMF_a034_trqCrossCheck m0 : 37|1@1+ (1,0) [0|1] "" Vector__XXX
 SG_ PMF_a035_udsTransactionInitiated m0 : 38|1@1+ (1,0) [0|1] "" Vector__XXX
 SG_ PMF_a036_preWatchdog m0 : 39|1@1+ (1,0) [0|1] "" Vector__XXX
 SG_ PMF_a037_hvpMIA m0 : 40|1@1+ (1,0) [0|1] "" Vector__XXX
 SG_ PMF_a039_disMIA m0 : 42|1@1+ (1,0) [0|1] "" Vector__XXX
 SG_ PMF_a040_pmMIA m0 : 43|1@1+ (1,0) [0|1] "" Vector__XXX
 SG_ PMF_a042_gtwMIA m0 : 45|1@1+ (1,0) [0|1] "" Vector__XXX
 SG_ PMF_a045_motorMovementDetected m0 : 48|1@1+ (1,0) [0|1] "" Vector__XXX
 SG_ PMF_a053_vcfrontMIA m0 : 56|1@1+ (1,0) [0|1] "" Vector__XXX
 SG_ PMF_a054_uiMIA m0 : 57|1@1+ (1,0) [0|1] "" Vector__XXX
 SG_ PMF_a055_resolver m0 : 58|1@1+ (1,0) [0|1] "" Vector__XXX
 SG_ PMF_a056_canHardwareBusB m0 : 59|1@1+ (1,0) [0|1] "" Vector__XXX
 SG_ PMF_a057_canDataBusB m0 : 60|1@1+ (1,0) [0|1] "" Vector__XXX
 SG_ PMF_a058_measuredHvilCurrentFroz m0 : 61|1@1+ (1,0) [0|1] "" Vector__XXX
 SG_ PMF_a061_DIPMVersionMismatch m1 : 4|1@1+ (1,0) [0|1] "" Vector__XXX
 SG_ PMF_a062_eccError m1 : 5|1@1+ (1,0) [0|1] "" Vector__XXX
 SG_ PMF_a064_torqueIntervention m1 : 7|1@1+ (1,0) [0|1] "" Vector__XXX
 SG_ PMF_a080_exceptionPrefetchAbort m1 : 23|1@1+ (1,0) [0|1] "" Vector__XXX
 SG_ PMF_a081_exceptionDataAbort m1 : 24|1@1+ (1,0) [0|1] "" Vector__XXX
 SG_ PMF_a082_exceptionDataAbort2 m1 : 25|1@1+ (1,0) [0|1] "" Vector__XXX
 SG_ PMF_a083_ahbWriteError m1 : 26|1@1+ (1,0) [0|1] "" Vector__XXX
 SG_ PMF_a084_exceptionMpuFirewall m1 : 27|1@1+ (1,0) [0|1] "" Vector__XXX
 SG_ PMF_a086_exceptionUndefinedInstr m1 : 29|1@1+ (1,0) [0|1] "" Vector__XXX
 SG_ PMF_a092_xtalOscillator m1 : 35|1@1+ (1,0) [0|1] "" Vector__XXX
 SG_ PMF_a094_safetyICWarn m1 : 37|1@1+ (1,0) [0|1] "" Vector__XXX
 SG_ PMF_a095_safetyICFault m1 : 38|1@1+ (1,0) [0|1] "" Vector__XXX
 SG_ PMF_a096_safetyICDebug m1 : 39|1@1+ (1,0) [0|1] "" Vector__XXX
 SG_ PMF_a097_lowFlowAlmostTripped m1 : 40|1@1+ (1,0) [0|1] "" Vector__XXX
 SG_ PMF_a100_diTraceInfo1 m1 : 43|1@1+ (1,0) [0|1] "" Vector__XXX
 SG_ PMF_a114_ramScrubTimedOut m1 : 57|1@1+ (1,0) [0|1] "" Vector__XXX
 SG_ PMF_a121_unintendedReset2 m2 : 4|1@1+ (1,0) [0|1] "" Vector__XXX

BO_ 790 PMF_info: 8 PMF
 SG_ PMF_infoIndex M : 0|8@1+ (1,0) [0|255] "" Vector__XXX
 SG_ PMF_buildType m10 : 8|8@1+ (1,0) [0|255] "" Vector__XXX
 SG_ PMF_buildConfigurationId m10 : 16|16@1+ (1,0) [0|65535] "" Vector__XXX
 SG_ PMF_hardwareId m10 : 32|8@1+ (1,0) [0|252] "" Vector__XXX
 SG_ PMF_deviceFused m10 : 40|1@1+ (1,0) [0|1] "" Vector__XXX
 SG_ PMF_componentId m10 : 48|16@1+ (1,0) [0|65535] "" Vector__XXX
 SG_ PMF_pcbaId m11 : 16|8@1+ (1,0) [0|255] "" Vector__XXX
 SG_ PMF_assemblyId m11 : 24|8@1+ (1,0) [0|255] "" Vector__XXX
 SG_ PMF_usageId m11 : 32|16@1+ (1,0) [0|65535] "" Vector__XXX
 SG_ PMF_subUsageId m11 : 48|16@1+ (1,0) [0|65535] "" Vector__XXX
 SG_ PMF_applicationCrc m13 : 32|32@1+ (1,0) [0|4294967295] "" Vector__XXX
 SG_ PMF_appGitHash m17 : 8|56@1+ (1,0) [0|7.20575940379e+16] "" Vector__XXX
 SG_ PMF_bootGitHash m18 : 8|56@1+ (1,0) [0|7.20575940379e+16] "" Vector__XXX
 SG_ PMF_platformTyp m19 : 8|8@1+ (1,0) [0|255] "" Vector__XXX
 SG_ PMF_udsProtocolVersion m20 : 8|8@1+ (1,0) [0|255] "" Vector__XXX
 SG_ PMF_bootloaderCrc m20 : 32|32@1+ (1,0) [0|4294967295] "" Vector__XXX

BO_ 1316 PMF_mfgData: 8 PMF
 SG_ PMF_processorDieIdLot : 0|24@1+ (1,0) [0|16777215] "" Vector__XXX
 SG_ PMF_processorDieIdWafer : 24|8@1+ (1,0) [0|255] "" Vector__XXX
 SG_ PMF_processorDieIdX : 32|12@1+ (1,0) [0|4095] "" Vector__XXX
 SG_ PMF_processorDieIdY : 44|12@1+ (1,0) [0|4095] "" Vector__XXX

CM_ BO_ 1060 "Power conversion system (on-board charger and DC-DC converter) message: alert log";
CM_ SG_ 1060 PCS_alertID "Power conversion system (on-board charger and DC-DC converter): alert ID";
CM_ SG_ 1060 PCS_alertSet "Power conversion system (on-board charger and DC-DC converter): alert set";
CM_ SG_ 1060 PCS_alertSource "Power conversion system (on-board charger and DC-DC converter): alert source";
CM_ SG_ 1060 PCS_a001_llcFrequency "Power conversion system (on-board charger and DC-DC converter): a001 llc frequency";
CM_ SG_ 1060 PCS_a001_llcCurrent "Power conversion system (on-board charger and DC-DC converter): a001 llc current";
CM_ SG_ 1060 PCS_a001_phState "Power conversion system (on-board charger and DC-DC converter): a001 ph state";
CM_ SG_ 1060 PCS_a001_pfcCurrentRms "Power conversion system (on-board charger and DC-DC converter): a001 pfc current rms";
CM_ SG_ 1060 PCS_a001_intBusV "Power conversion system (on-board charger and DC-DC converter): a001 int bus v";
CM_ SG_ 1060 PCS_a002_phState "Power conversion system (on-board charger and DC-DC converter): a002 ph state";
CM_ SG_ 1060 PCS_a003_phState "Power conversion system (on-board charger and DC-DC converter): a003 ph state";
CM_ SG_ 1060 PCS_a004_phState "Power conversion system (on-board charger and DC-DC converter): a004 ph state";
CM_ SG_ 1060 PCS_a005_outputV "Power conversion system (on-board charger and DC-DC converter): a005 output v";
CM_ SG_ 1060 PCS_a005_outputVOvThreshold "Power conversion system (on-board charger and DC-DC converter): a005 output v ov threshold";
CM_ SG_ 1060 PCS_a006_phState "Power conversion system (on-board charger and DC-DC converter): a006 ph state";
CM_ SG_ 1060 PCS_a006_intBusPrechargeTarget "Power conversion system (on-board charger and DC-DC converter): a006 int bus precharge target";
CM_ SG_ 1060 PCS_a006_intBusV "Power conversion system (on-board charger and DC-DC converter): a006 int bus v";
CM_ SG_ 1060 PCS_a006_inputVrms "Power conversion system (on-board charger and DC-DC converter): a006 input vrms";
CM_ SG_ 1060 PCS_a006_inputVToIntBusDeltaMax "Power conversion system (on-board charger and DC-DC converter): a006 input v to int bus delta max";
CM_ SG_ 1060 PCS_a006_inputFrequency "Power conversion system (on-board charger and DC-DC converter): a006 input frequency";
CM_ SG_ 1060 PCS_a007_phATemperature "Power conversion system (on-board charger and DC-DC converter): a007 ph a temperature";
CM_ SG_ 1060 PCS_a007_phBTemperature "Power conversion system (on-board charger and DC-DC converter): a007 ph b temperature";
CM_ SG_ 1060 PCS_a007_phCTemperature "Power conversion system (on-board charger and DC-DC converter): a007 ph c temperature";
CM_ SG_ 1060 PCS_a007_ambientTemperature "Power conversion system (on-board charger and DC-DC converter): a007 ambient temperature";
CM_ SG_ 1060 PCS_a007_inputVrms "Power conversion system (on-board charger and DC-DC converter): a007 input vrms";
CM_ SG_ 1060 PCS_a007_inputIrms "Power conversion system (on-board charger and DC-DC converter): a007 input irms";
CM_ SG_ 1060 PCS_a008_phState "Power conversion system (on-board charger and DC-DC converter): a008 ph state";
CM_ SG_ 1060 PCS_a008_phaseTemperature "Power conversion system (on-board charger and DC-DC converter): a008 phase temperature";
CM_ SG_ 1060 PCS_a008_inputVrms "Power conversion system (on-board charger and DC-DC converter): a008 input vrms";
CM_ SG_ 1060 PCS_a008_inputIrms "Power conversion system (on-board charger and DC-DC converter): a008 input irms";
CM_ SG_ 1060 PCS_a009_phState "Power conversion system (on-board charger and DC-DC converter): a009 ph state";
CM_ SG_ 1060 PCS_a009_pfcCurrentRms "Power conversion system (on-board charger and DC-DC converter): a009 pfc current rms";
CM_ SG_ 1060 PCS_a009_pfcCurrentTarget "Power conversion system (on-board charger and DC-DC converter): a009 pfc current target";
CM_ SG_ 1060 PCS_a009_llcCurrent "Power conversion system (on-board charger and DC-DC converter): a009 llc current";
CM_ SG_ 1060 PCS_a009_intBusV "Power conversion system (on-board charger and DC-DC converter): a009 int bus v";
CM_ SG_ 1060 PCS_a010_phState "Power conversion system (on-board charger and DC-DC converter): a010 ph state";
CM_ SG_ 1060 PCS_a010_pfcCurrentRms "Power conversion system (on-board charger and DC-DC converter): a010 pfc current rms";
CM_ SG_ 1060 PCS_a010_llcCurrent "Power conversion system (on-board charger and DC-DC converter): a010 llc current";
CM_ SG_ 1060 PCS_a010_intBusV "Power conversion system (on-board charger and DC-DC converter): a010 int bus v";
CM_ SG_ 1060 PCS_a010_intBusVTarget "Power conversion system (on-board charger and DC-DC converter): a010 int bus v target";
CM_ SG_ 1060 PCS_a011_phState "Power conversion system (on-board charger and DC-DC converter): a011 ph state";
CM_ SG_ 1060 PCS_a011_llcCurrent "Power conversion system (on-board charger and DC-DC converter): a011 llc current";
CM_ SG_ 1060 PCS_a011_llcCurrentTarget "Power conversion system (on-board charger and DC-DC converter): a011 llc current target";
CM_ SG_ 1060 PCS_a011_llcFrequency "Power conversion system (on-board charger and DC-DC converter): a011 llc frequency";
CM_ SG_ 1060 PCS_a011_intBusV "Power conversion system (on-board charger and DC-DC converter): a011 int bus v";
CM_ SG_ 1060 PCS_a011_outputV "Power conversion system (on-board charger and DC-DC converter): a011 output v";
CM_ SG_ 1060 PCS_a013_phState "Power conversion system (on-board charger and DC-DC converter): a013 ph state";
CM_ SG_ 1060 PCS_a013_intBusPrechargeTarget "Power conversion system (on-board charger and DC-DC converter): a013 int bus precharge target";
CM_ SG_ 1060 PCS_a013_intBusV "Power conversion system (on-board charger and DC-DC converter): a013 int bus v";
CM_ SG_ 1060 PCS_a013_inputVrms "Power conversion system (on-board charger and DC-DC converter): a013 input vrms";
CM_ SG_ 1060 PCS_a013_inputVToIntBusDeltaMax "Power conversion system (on-board charger and DC-DC converter): a013 input v to int bus delta max";
CM_ SG_ 1060 PCS_a013_inputFrequency "Power conversion system (on-board charger and DC-DC converter): a013 input frequency";
CM_ SG_ 1060 PCS_a014_phaTemperature "Power conversion system (on-board charger and DC-DC converter): a014 pha temperature";
CM_ SG_ 1060 PCS_a014_phbTemperature "Power conversion system (on-board charger and DC-DC converter): a014 phb temperature";
CM_ SG_ 1060 PCS_a014_phcTemperature "Power conversion system (on-board charger and DC-DC converter): a014 phc temperature";
CM_ SG_ 1060 PCS_a015_lvBusVoltage "Power conversion system (on-board charger and DC-DC converter): a015 lv bus voltage";
CM_ SG_ 1060 PCS_a016_phAVoltSrcMissingDetect "Power conversion system (on-board charger and DC-DC converter): a016 ph a volt src missing detected";
CM_ SG_ 1060 PCS_a016_phBVoltSrcMissingDetect "Power conversion system (on-board charger and DC-DC converter): a016 ph b volt src missing detected";
CM_ SG_ 1060 PCS_a016_phCVoltSrcMissingDetect "Power conversion system (on-board charger and DC-DC converter): a016 ph c volt src missing detected";
CM_ SG_ 1060 PCS_a018_PhaseDiff_L1N_L2N "Power conversion system (on-board charger and DC-DC converter): a018 phase diff L1 n L2 n";
CM_ SG_ 1060 PCS_a018_PhaseDiff_L2N_L3N "Power conversion system (on-board charger and DC-DC converter): a018 phase diff L2 n L3 n";
CM_ SG_ 1060 PCS_a018_PhaseDiff_L1N_L3N "Power conversion system (on-board charger and DC-DC converter): a018 phase diff L1 n L3 n";
CM_ SG_ 1060 PCS_a018_PhaseDiff_L1L2_L1N "Power conversion system (on-board charger and DC-DC converter): a018 phase diff L1 L2 L1 n";
CM_ SG_ 1060 PCS_a018_L1NLocked "Power conversion system (on-board charger and DC-DC converter): a018 L1 n locked";
CM_ SG_ 1060 PCS_a018_L2NLocked "Power conversion system (on-board charger and DC-DC converter): a018 L2 n locked";
CM_ SG_ 1060 PCS_a018_L3NLocked "Power conversion system (on-board charger and DC-DC converter): a018 L3 n locked";
CM_ SG_ 1060 PCS_a018_L1L2Locked "Power conversion system (on-board charger and DC-DC converter): a018 L1 L2 locked";
CM_ SG_ 1060 PCS_a019_pcsMaxAvailablePower "Power conversion system (on-board charger and DC-DC converter): a019 pcs max available power";
CM_ SG_ 1060 PCS_a019_utilityPowerAvailable "Power conversion system (on-board charger and DC-DC converter): a019 utility power available";
CM_ SG_ 1060 PCS_a019_userPowerRequest "Power conversion system (on-board charger and DC-DC converter): a019 user power request";
CM_ SG_ 1060 PCS_a019_phAFaulted "Power conversion system (on-board charger and DC-DC converter): a019 ph a faulted";
CM_ SG_ 1060 PCS_a019_phBFaulted "Power conversion system (on-board charger and DC-DC converter): a019 ph b faulted";
CM_ SG_ 1060 PCS_a019_phCFaulted "Power conversion system (on-board charger and DC-DC converter): a019 ph c faulted";
CM_ SG_ 1060 PCS_a020_chargeEnableLine "Power conversion system (on-board charger and DC-DC converter): a020 charge enable line";
CM_ SG_ 1060 PCS_a020_chargeEnableCan "Power conversion system (on-board charger and DC-DC converter): a020 charge enable can";
CM_ SG_ 1060 PCS_a021_HVP_hvsControl "Power conversion system (on-board charger and DC-DC converter): a021 HVP hvs control";
CM_ SG_ 1060 PCS_a023_CP_chargeStatus "Power conversion system (on-board charger and DC-DC converter): a023 CP charge status";
CM_ SG_ 1060 PCS_a023_CP_status "Power conversion system (on-board charger and DC-DC converter): a023 CP status";
CM_ SG_ 1060 PCS_a024_VCFRONT_sensors "Power conversion system (on-board charger and DC-DC converter): a024 VCFRONT sensors";
CM_ SG_ 1060 PCS_a024_VCFRONT_vehicleStatus "Power conversion system (on-board charger and DC-DC converter): a024 VCFRONT vehicle status";
CM_ SG_ 1060 PCS_a024_VCFRONT_systemStatus "Power conversion system (on-board charger and DC-DC converter): a024 VCFRONT system status";
CM_ SG_ 1060 PCS_a024_VCFRONT_coolant "Power conversion system (on-board charger and DC-DC converter): a024 VCFRONT coolant";
CM_ SG_ 1060 PCS_a024_VCFRONT_vehNm "Power conversion system (on-board charger and DC-DC converter): a024 VCFRONT veh nm";
CM_ SG_ 1060 PCS_a024_VC_pcsManagement "Power conversion system (on-board charger and DC-DC converter): a024 VC pcs management";
CM_ SG_ 1060 PCS_a024_VCFRONT_LVPowerState "Power conversion system (on-board charger and DC-DC converter): a024 VCFRONT LV power state";
CM_ SG_ 1060 PCS_a025_cpu2ErrorCode "Power conversion system (on-board charger and DC-DC converter): a025 cpu2 error code";
CM_ SG_ 1060 PCS_a025_bootromStatus "Power conversion system (on-board charger and DC-DC converter): a025 bootrom status";
CM_ SG_ 1060 PCS_a025_bootloaderStatus "Power conversion system (on-board charger and DC-DC converter): a025 bootloader status";
CM_ SG_ 1060 PCS_a025_bootromRequestFlag "Power conversion system (on-board charger and DC-DC converter): a025 bootrom request flag";
CM_ SG_ 1060 PCS_a025_bootromRequestStatusFla "Power conversion system (on-board charger and DC-DC converter): a025 bootrom request status flag";
CM_ SG_ 1060 PCS_a025_cpu2StoredAppCrcLsb16 "Power conversion system (on-board charger and DC-DC converter): a025 cpu2 stored app crc lsb16";
CM_ SG_ 1060 PCS_a027_chgPhATemp "Power conversion system (on-board charger and DC-DC converter): a027 chg ph a temp";
CM_ SG_ 1060 PCS_a027_chgPhBTemp "Power conversion system (on-board charger and DC-DC converter): a027 chg ph b temp";
CM_ SG_ 1060 PCS_a027_chgPhCTemp "Power conversion system (on-board charger and DC-DC converter): a027 chg ph c temp";
CM_ SG_ 1060 PCS_a027_chgPhANoFlowBucket "Power conversion system (on-board charger and DC-DC converter): a027 chg ph a no flow bucket";
CM_ SG_ 1060 PCS_a027_chgPhBNoFlowBucket "Power conversion system (on-board charger and DC-DC converter): a027 chg ph b no flow bucket";
CM_ SG_ 1060 PCS_a027_chgPhCNoFlowBucket "Power conversion system (on-board charger and DC-DC converter): a027 chg ph c no flow bucket";
CM_ SG_ 1060 PCS_a028_outputV "Power conversion system (on-board charger and DC-DC converter): a028 output v";
CM_ SG_ 1060 PCS_a028_outputVUvThreshold "Power conversion system (on-board charger and DC-DC converter): a028 output v uv threshold";
CM_ SG_ 1060 PCS_a029_inputVrms "Power conversion system (on-board charger and DC-DC converter): a029 input vrms";
CM_ SG_ 1060 PCS_a029_chgInputPower "Power conversion system (on-board charger and DC-DC converter): a029 chg input power";
CM_ SG_ 1060 PCS_a029_bmsPowerCommand "Power conversion system (on-board charger and DC-DC converter): a029 bms power command";
CM_ SG_ 1060 PCS_a029_phaseConfig "Power conversion system (on-board charger and DC-DC converter): a029 phase config";
CM_ SG_ 1060 PCS_a032_phATransientRetryCount "Power conversion system (on-board charger and DC-DC converter): a032 ph a transient retry count";
CM_ SG_ 1060 PCS_a032_phBTransientRetryCount "Power conversion system (on-board charger and DC-DC converter): a032 ph b transient retry count";
CM_ SG_ 1060 PCS_a032_phCTransientRetryCount "Power conversion system (on-board charger and DC-DC converter): a032 ph c transient retry count";
CM_ SG_ 1060 PCS_a032_phAFaulted "Power conversion system (on-board charger and DC-DC converter): a032 ph a faulted";
CM_ SG_ 1060 PCS_a032_phBFaulted "Power conversion system (on-board charger and DC-DC converter): a032 ph b faulted";
CM_ SG_ 1060 PCS_a032_phCFaulted "Power conversion system (on-board charger and DC-DC converter): a032 ph c faulted";
CM_ SG_ 1060 PCS_a033_HV_busV "Power conversion system (on-board charger and DC-DC converter): a033 HV bus v";
CM_ SG_ 1060 PCS_a034_HV_busV "Power conversion system (on-board charger and DC-DC converter): a034 HV bus v";
CM_ SG_ 1060 PCS_a035_LV_busV "Power conversion system (on-board charger and DC-DC converter): a035 LV bus v";
CM_ SG_ 1060 PCS_a037_dcdcPwmDeassertedCount "Power conversion system (on-board charger and DC-DC converter): a037 dcdc pwm deasserted count";
CM_ SG_ 1060 PCS_a038_dcdcClaFaultCode "Power conversion system (on-board charger and DC-DC converter): a038 dcdc cla fault code";
CM_ SG_ 1060 PCS_a038_dcdcSubState "Power conversion system (on-board charger and DC-DC converter): a038 dcdc sub state";
CM_ SG_ 1060 PCS_a038_dcdcLvBusV "Power conversion system (on-board charger and DC-DC converter): a038 dcdc lv bus v";
CM_ SG_ 1060 PCS_a038_dcdcHvBusV "Power conversion system (on-board charger and DC-DC converter): a038 dcdc hv bus v";
CM_ SG_ 1060 PCS_a038_dcdcLvBusCurrent_A "Power conversion system (on-board charger and DC-DC converter): a038 dcdc lv bus current a";
CM_ SG_ 1060 PCS_a038_dcdcPwmEnableDeasserted "Power conversion system (on-board charger and DC-DC converter): a038 dcdc pwm enable deasserted count";
CM_ SG_ 1060 PCS_a038_dcdcPwmEnableLine "Power conversion system (on-board charger and DC-DC converter): a038 dcdc pwm enable line";
CM_ SG_ 1060 PCS_a040_dcdcLvVoltageTarget "Power conversion system (on-board charger and DC-DC converter): a040 dcdc lv voltage target";
CM_ SG_ 1060 PCS_a040_dcdcLvVoltage "Power conversion system (on-board charger and DC-DC converter): a040 dcdc lv voltage";
CM_ SG_ 1060 PCS_a040_dcdcLvOutputCurrent "Power conversion system (on-board charger and DC-DC converter): a040 dcdc lv output current";
CM_ SG_ 1060 PCS_a041_dcdcTemperature "Power conversion system (on-board charger and DC-DC converter): a041 dcdc temperature";
CM_ SG_ 1060 PCS_a042_dcdcEnableLine "Power conversion system (on-board charger and DC-DC converter): a042 dcdc enable line";
CM_ SG_ 1060 PCS_a042_dcdcEnableCan "Power conversion system (on-board charger and DC-DC converter): a042 dcdc enable can";
CM_ SG_ 1060 PCS_a043_dcdcLvBusV "Power conversion system (on-board charger and DC-DC converter): a043 dcdc lv bus v";
CM_ SG_ 1060 PCS_a043_dcdcHvBusV "Power conversion system (on-board charger and DC-DC converter): a043 dcdc hv bus v";
CM_ SG_ 1060 PCS_a043_hvPrechargeTargetV "Power conversion system (on-board charger and DC-DC converter): a043 hv precharge target v";
CM_ SG_ 1060 PCS_a044_FaultReasonCode "Power conversion system (on-board charger and DC-DC converter): a044 fault reason code";
CM_ SG_ 1060 PCS_a044_shortTime_us "Power conversion system (on-board charger and DC-DC converter): a044 short time us";
CM_ SG_ 1060 PCS_a044_dcdcLvBusCurrent_A "Power conversion system (on-board charger and DC-DC converter): a044 dcdc lv bus current a";
CM_ SG_ 1060 PCS_a044_vTankPeak_abs_V "Power conversion system (on-board charger and DC-DC converter): a044 v tank peak abs v";
CM_ SG_ 1060 PCS_a045_hvBusEstimated_C_uF "Power conversion system (on-board charger and DC-DC converter): a045 hv bus estimated c u f";
CM_ SG_ 1060 PCS_a045_hvBusEstimated_R_kOhm "Power conversion system (on-board charger and DC-DC converter): a045 hv bus estimated r k ohm";
CM_ SG_ 1060 PCS_a046_hvBusEstimated_C_uF "Power conversion system (on-board charger and DC-DC converter): a046 hv bus estimated c u f";
CM_ SG_ 1060 PCS_a046_hvBusEstimated_R_kOhm "Power conversion system (on-board charger and DC-DC converter): a046 hv bus estimated r k ohm";
CM_ SG_ 1060 PCS_a047_cpu1BootLoaderCrcMismat "Power conversion system (on-board charger and DC-DC converter): a047 cpu1 boot loader crc mismatch";
CM_ SG_ 1060 PCS_a047_cpu2BootLoaderCrcMismat "Power conversion system (on-board charger and DC-DC converter): a047 cpu2 boot loader crc mismatch";
CM_ SG_ 1060 PCS_a047_calculatedBootloaderCrc "Power conversion system (on-board charger and DC-DC converter): a047 calculated bootloader crc";
CM_ SG_ 1060 PCS_a049_dcdcTemperature "Power conversion system (on-board charger and DC-DC converter): a049 dcdc temperature";
CM_ SG_ 1060 PCS_a051_phState "Power conversion system (on-board charger and DC-DC converter): a051 ph state";
CM_ SG_ 1060 PCS_a051_pfcCurrentRms "Power conversion system (on-board charger and DC-DC converter): a051 pfc current rms";
CM_ SG_ 1060 PCS_a051_llcCurrent "Power conversion system (on-board charger and DC-DC converter): a051 llc current";
CM_ SG_ 1060 PCS_a051_intBusV "Power conversion system (on-board charger and DC-DC converter): a051 int bus v";
CM_ SG_ 1060 PCS_a051_intBusVTarget "Power conversion system (on-board charger and DC-DC converter): a051 int bus v target";
CM_ SG_ 1060 PCS_a051_intBusStaticRipple "Power conversion system (on-board charger and DC-DC converter): a051 int bus static ripple";
CM_ SG_ 1060 PCS_a052_inputVrms "Power conversion system (on-board charger and DC-DC converter): a052 input vrms";
CM_ SG_ 1060 PCS_a053_inputVrms "Power conversion system (on-board charger and DC-DC converter): a053 input vrms";
CM_ SG_ 1060 PCS_a053_inputIrms "Power conversion system (on-board charger and DC-DC converter): a053 input irms";
CM_ SG_ 1060 PCS_a053_acChargeCurrentLimit "Power conversion system (on-board charger and DC-DC converter): a053 ac charge current limit";
CM_ SG_ 1060 PCS_a053_startingInputVrms "Power conversion system (on-board charger and DC-DC converter): a053 starting input vrms";
CM_ SG_ 1060 PCS_a053_phaseConfig "Power conversion system (on-board charger and DC-DC converter): a053 phase config";
CM_ SG_ 1060 PCS_a054_inputVrms "Power conversion system (on-board charger and DC-DC converter): a054 input vrms";
CM_ SG_ 1060 PCS_a054_inputIrms "Power conversion system (on-board charger and DC-DC converter): a054 input irms";
CM_ SG_ 1060 PCS_a054_acChargeCurrentLimit "Power conversion system (on-board charger and DC-DC converter): a054 ac charge current limit";
CM_ SG_ 1060 PCS_a054_startingInputVrms "Power conversion system (on-board charger and DC-DC converter): a054 starting input vrms";
CM_ SG_ 1060 PCS_a054_phaseConfig "Power conversion system (on-board charger and DC-DC converter): a054 phase config";
CM_ SG_ 1060 PCS_a057_inputVrms "Power conversion system (on-board charger and DC-DC converter): a057 input vrms";
CM_ SG_ 1060 PCS_a057_inputFrequency "Power conversion system (on-board charger and DC-DC converter): a057 input frequency";
CM_ SG_ 1060 PCS_a058_inputVrms "Power conversion system (on-board charger and DC-DC converter): a058 input vrms";
CM_ SG_ 1060 PCS_a058_inputFrequency "Power conversion system (on-board charger and DC-DC converter): a058 input frequency";
CM_ SG_ 1060 PCS_a059_inputVrms "Power conversion system (on-board charger and DC-DC converter): a059 input vrms";
CM_ SG_ 1060 PCS_a059_inputOvRmsThreshold "Power conversion system (on-board charger and DC-DC converter): a059 input ov rms threshold";
CM_ SG_ 1060 PCS_a060_inputVPeak "Power conversion system (on-board charger and DC-DC converter): a060 input v peak";
CM_ SG_ 1060 PCS_a060_inputOvPeakThreshold "Power conversion system (on-board charger and DC-DC converter): a060 input ov peak threshold";
CM_ SG_ 1060 PCS_a061_chgInputVdcOffset_L1N "Power conversion system (on-board charger and DC-DC converter): a061 chg input vdc offset L1 n";
CM_ SG_ 1060 PCS_a061_chgInputVdcOffset_L2N "Power conversion system (on-board charger and DC-DC converter): a061 chg input vdc offset L2 n";
CM_ SG_ 1060 PCS_a061_chgInputVdcOffset_L3N "Power conversion system (on-board charger and DC-DC converter): a061 chg input vdc offset L3 n";
CM_ SG_ 1060 PCS_a061_chgInputVdcOffset_L1L2 "Power conversion system (on-board charger and DC-DC converter): a061 chg input vdc offset L1 L2";
CM_ SG_ 1060 PCS_a061_PllSourceIrrational_L1N "Power conversion system (on-board charger and DC-DC converter): a061 pll source irrational L1 n";
CM_ SG_ 1060 PCS_a061_PllSourceIrrational_L2N "Power conversion system (on-board charger and DC-DC converter): a061 pll source irrational L2 n";
CM_ SG_ 1060 PCS_a061_PllSourceIrrational_L3N "Power conversion system (on-board charger and DC-DC converter): a061 pll source irrational L3 n";
CM_ SG_ 1060 PCS_a061_PllSourceIrrational_L1L "Power conversion system (on-board charger and DC-DC converter): a061 pll source irrational L1 L2";
CM_ SG_ 1060 PCS_a062_chgInputIOffset "Power conversion system (on-board charger and DC-DC converter): a062 chg input i offset";
CM_ SG_ 1060 PCS_a063_chgOutputV "Power conversion system (on-board charger and DC-DC converter): a063 chg output v";
CM_ SG_ 1060 PCS_a063_hvpHvLinkVoltage "Power conversion system (on-board charger and DC-DC converter): a063 hvp hv link voltage";
CM_ SG_ 1060 PCS_a064_chgOutputIOffset "Power conversion system (on-board charger and DC-DC converter): a064 chg output i offset";
CM_ SG_ 1060 PCS_a065_inputVrms "Power conversion system (on-board charger and DC-DC converter): a065 input vrms";
CM_ SG_ 1060 PCS_a065_inputFrequency "Power conversion system (on-board charger and DC-DC converter): a065 input frequency";
CM_ SG_ 1060 PCS_a066_dcdcHvBusVolt "Power conversion system (on-board charger and DC-DC converter): a066 dcdc hv bus volt";
CM_ SG_ 1060 PCS_a066_hvpHvLinkVoltage "Power conversion system (on-board charger and DC-DC converter): a066 hvp hv link voltage";
CM_ SG_ 1060 PCS_a067_dcdcLvBusVolt "Power conversion system (on-board charger and DC-DC converter): a067 dcdc lv bus volt";
CM_ SG_ 1060 PCS_a067_vcfrontPcsEFuseV "Power conversion system (on-board charger and DC-DC converter): a067 vcfront pcs e fuse v";
CM_ SG_ 1060 PCS_a067_vcfrontVcrightVoltage "Power conversion system (on-board charger and DC-DC converter): a067 vcfront vcright voltage";
CM_ SG_ 1060 PCS_a068_dcdcTankVolt "Power conversion system (on-board charger and DC-DC converter): a068 dcdc tank volt";
CM_ SG_ 1060 PCS_a068_dcdcTankVoltOffset "Power conversion system (on-board charger and DC-DC converter): a068 dcdc tank volt offset";
CM_ SG_ 1060 PCS_a071_phState "Power conversion system (on-board charger and DC-DC converter): a071 ph state";
CM_ SG_ 1060 PCS_a071_inputVrms "Power conversion system (on-board charger and DC-DC converter): a071 input vrms";
CM_ SG_ 1060 PCS_a071_intBusV "Power conversion system (on-board charger and DC-DC converter): a071 int bus v";
CM_ SG_ 1060 PCS_a071_inputFrequency "Power conversion system (on-board charger and DC-DC converter): a071 input frequency";
CM_ SG_ 1060 PCS_a071_llcFrequency "Power conversion system (on-board charger and DC-DC converter): a071 llc frequency";
CM_ SG_ 1060 PCS_a072_task1Stopped "Power conversion system (on-board charger and DC-DC converter): a072 task1 stopped";
CM_ SG_ 1060 PCS_a072_task2Stopped "Power conversion system (on-board charger and DC-DC converter): a072 task2 stopped";
CM_ SG_ 1060 PCS_a073_inputL1NVrms "Power conversion system (on-board charger and DC-DC converter): a073 input L1 n vrms";
CM_ SG_ 1060 PCS_a073_inputL2NVrms "Power conversion system (on-board charger and DC-DC converter): a073 input L2 n vrms";
CM_ SG_ 1060 PCS_a073_inputL3NVrms "Power conversion system (on-board charger and DC-DC converter): a073 input L3 n vrms";
CM_ SG_ 1060 PCS_a073_inputNGVrms "Power conversion system (on-board charger and DC-DC converter): a073 input NG vrms";
CM_ SG_ 1060 PCS_a073_phaseConfig "Power conversion system (on-board charger and DC-DC converter): a073 phase config";
CM_ SG_ 1060 PCS_a073_cpType "Power conversion system (on-board charger and DC-DC converter): a073 cp type";
CM_ SG_ 1060 PCS_a074_dcdcLvBusV "Power conversion system (on-board charger and DC-DC converter): a074 dcdc lv bus v";
CM_ SG_ 1060 PCS_a074_dcdcHvBusV "Power conversion system (on-board charger and DC-DC converter): a074 dcdc hv bus v";
CM_ SG_ 1060 PCS_a075_dcdcLvBusV "Power conversion system (on-board charger and DC-DC converter): a075 dcdc lv bus v";
CM_ SG_ 1060 PCS_a075_dcdcHvBusV "Power conversion system (on-board charger and DC-DC converter): a075 dcdc hv bus v";
CM_ SG_ 1060 PCS_a075_dcdcSubState "Power conversion system (on-board charger and DC-DC converter): a075 dcdc sub state";
CM_ SG_ 1060 PCS_a076_pcsControlRequest "Power conversion system (on-board charger and DC-DC converter): a076 pcs control request";
CM_ SG_ 1060 PCS_a076_dcdcSubState "Power conversion system (on-board charger and DC-DC converter): a076 dcdc sub state";
CM_ SG_ 1060 PCS_a076_dcdcEnableLine "Power conversion system (on-board charger and DC-DC converter): a076 dcdc enable line";
CM_ SG_ 1060 PCS_a076_dcdcPwmEnableDeasserted "Power conversion system (on-board charger and DC-DC converter): a076 dcdc pwm enable deasserted count";
CM_ SG_ 1060 PCS_a078_phaTemperature "Power conversion system (on-board charger and DC-DC converter): a078 pha temperature";
CM_ SG_ 1060 PCS_a078_phbTemperature "Power conversion system (on-board charger and DC-DC converter): a078 phb temperature";
CM_ SG_ 1060 PCS_a078_phcTemperature "Power conversion system (on-board charger and DC-DC converter): a078 phc temperature";
CM_ SG_ 1060 PCS_a078_dcdcTemperature "Power conversion system (on-board charger and DC-DC converter): a078 dcdc temperature";
CM_ SG_ 1060 PCS_a078_ptCoolantTemp "Power conversion system (on-board charger and DC-DC converter): a078 pt coolant temp";
CM_ SG_ 1060 PCS_a079_eepromOperation "Power conversion system (on-board charger and DC-DC converter): a079 eeprom operation";
CM_ SG_ 1060 PCS_a079_eepromOperationRegion "Power conversion system (on-board charger and DC-DC converter): a079 eeprom operation region";
CM_ SG_ 1060 PCS_a079_recordID "Power conversion system (on-board charger and DC-DC converter): a079 record ID";
CM_ SG_ 1060 PCS_a079_eepromOperationErrorCod "Power conversion system (on-board charger and DC-DC converter): a079 eeprom operation error code";
CM_ SG_ 1060 PCS_a079_operationAddress "Power conversion system (on-board charger and DC-DC converter): a079 operation address";
CM_ SG_ 1060 PCS_a079_eepromErrorCount "Power conversion system (on-board charger and DC-DC converter): a079 eeprom error count";
CM_ SG_ 1060 PCS_a080_phADamaged "Power conversion system (on-board charger and DC-DC converter): a080 ph a damaged";
CM_ SG_ 1060 PCS_a080_phBDamaged "Power conversion system (on-board charger and DC-DC converter): a080 ph b damaged";
CM_ SG_ 1060 PCS_a080_phCDamaged "Power conversion system (on-board charger and DC-DC converter): a080 ph c damaged";
CM_ SG_ 1060 PCS_a080_phANVRAMStoredState "Power conversion system (on-board charger and DC-DC converter): a080 ph ANVRAM stored state";
CM_ SG_ 1060 PCS_a080_phBNVRAMStoredState "Power conversion system (on-board charger and DC-DC converter): a080 ph BNVRAM stored state";
CM_ SG_ 1060 PCS_a080_phCNVRAMStoredState "Power conversion system (on-board charger and DC-DC converter): a080 ph CNVRAM stored state";
CM_ SG_ 1060 PCS_a081_dcdcLvBusV "Power conversion system (on-board charger and DC-DC converter): a081 dcdc lv bus v";
CM_ SG_ 1060 PCS_a081_dcdcHvBusV "Power conversion system (on-board charger and DC-DC converter): a081 dcdc hv bus v";
CM_ SG_ 1060 PCS_a081_faultedSubstate "Power conversion system (on-board charger and DC-DC converter): a081 faulted substate";
CM_ SG_ 1060 PCS_a082_dcdcLvBusV "Power conversion system (on-board charger and DC-DC converter): a082 dcdc lv bus v";
CM_ SG_ 1060 PCS_a082_dcdcHvBusV "Power conversion system (on-board charger and DC-DC converter): a082 dcdc hv bus v";
CM_ SG_ 1060 PCS_a082_faultedSubstate "Power conversion system (on-board charger and DC-DC converter): a082 faulted substate";
CM_ SG_ 1060 PCS_a085_dcdcHalfPeriodUs "Power conversion system (on-board charger and DC-DC converter): a085 dcdc half period us";
CM_ SG_ 1060 PCS_a086_dcdcTemperature "Power conversion system (on-board charger and DC-DC converter): a086 dcdc temperature";
CM_ SG_ 1060 PCS_a086_pcsAmbientTemperature "Power conversion system (on-board charger and DC-DC converter): a086 pcs ambient temperature";
CM_ SG_ 1060 PCS_a086_vcfrontPTCoolantTemp "Power conversion system (on-board charger and DC-DC converter): a086 vcfront PT coolant temp";
CM_ SG_ 1060 PCS_a088_gridConfig "Power conversion system (on-board charger and DC-DC converter): a088 grid config";
CM_ SG_ 1060 PCS_a088_phAFrequency "Power conversion system (on-board charger and DC-DC converter): a088 ph a frequency";
CM_ SG_ 1060 PCS_a088_phBFrequency "Power conversion system (on-board charger and DC-DC converter): a088 ph b frequency";
CM_ SG_ 1060 PCS_a088_phCFrequency "Power conversion system (on-board charger and DC-DC converter): a088 ph c frequency";
CM_ SG_ 1060 PCS_a089_hvSlewRate "Power conversion system (on-board charger and DC-DC converter): a089 hv slew rate";
CM_ SG_ 1060 PCS_a089_avgSlewRate "Power conversion system (on-board charger and DC-DC converter): a089 avg slew rate";
CM_ SG_ 1060 PCS_a089_G "Power conversion system (on-board charger and DC-DC converter): a089 g";
CM_ SG_ 1060 PCS_a089_HV_busV "Power conversion system (on-board charger and DC-DC converter): a089 HV bus v";
CM_ SG_ 1060 PCS_a089_PhaseShift "Power conversion system (on-board charger and DC-DC converter): a089 phase shift";
CM_ SG_ 1060 PCS_a089_Freq "Power conversion system (on-board charger and DC-DC converter): a089 freq";
CM_ SG_ 1060 PCS_a089_fastDischargeMode "Power conversion system (on-board charger and DC-DC converter): a089 fast discharge mode";
CM_ SG_ 1060 PCS_a089_slowDischargeMode "Power conversion system (on-board charger and DC-DC converter): a089 slow discharge mode";
CM_ SG_ 1060 PCS_a090_vRmsL1N "Power conversion system (on-board charger and DC-DC converter): a090 v rms L1 n";
CM_ SG_ 1060 PCS_a090_vRmsL2N "Power conversion system (on-board charger and DC-DC converter): a090 v rms L2 n";
CM_ SG_ 1060 PCS_a090_vRmsL3N "Power conversion system (on-board charger and DC-DC converter): a090 v rms L3 n";
CM_ SG_ 1060 PCS_a090_vRmsL1L2 "Power conversion system (on-board charger and DC-DC converter): a090 v rms L1 L2";
CM_ SG_ 1060 PCS_a090_evaluatedGridConfig "Power conversion system (on-board charger and DC-DC converter): a090 evaluated grid config";
CM_ SG_ 1060 PCS_a090_phASourceMissing "Power conversion system (on-board charger and DC-DC converter): a090 ph a source missing";
CM_ SG_ 1060 PCS_a090_phBSourceMissing "Power conversion system (on-board charger and DC-DC converter): a090 ph b source missing";
CM_ SG_ 1060 PCS_a090_phCSourceMissing "Power conversion system (on-board charger and DC-DC converter): a090 ph c source missing";
CM_ SG_ 1060 PCS_a091_intBusTarget "Power conversion system (on-board charger and DC-DC converter): a091 int bus target";
CM_ SG_ 1060 PCS_a091_intBusMaxRippleLevel "Power conversion system (on-board charger and DC-DC converter): a091 int bus max ripple level";
CM_ SG_ 1060 PCS_a091_pfcCurrentIrms "Power conversion system (on-board charger and DC-DC converter): a091 pfc current irms";
CM_ SG_ 1060 PCS_a091_phaseInputVrms "Power conversion system (on-board charger and DC-DC converter): a091 phase input vrms";
CM_ SG_ 1060 PCS_a091_phaseTemp "Power conversion system (on-board charger and DC-DC converter): a091 phase temp";
CM_ SG_ 1060 PCS_a092_pfcIrmsPhA "Power conversion system (on-board charger and DC-DC converter): a092 pfc irms ph a";
CM_ SG_ 1060 PCS_a092_pfcIrmsPhB "Power conversion system (on-board charger and DC-DC converter): a092 pfc irms ph b";
CM_ SG_ 1060 PCS_a092_pfcIrmsPhC "Power conversion system (on-board charger and DC-DC converter): a092 pfc irms ph c";
CM_ SG_ 1060 PCS_a092_chgTempPhA "Power conversion system (on-board charger and DC-DC converter): a092 chg temp ph a";
CM_ SG_ 1060 PCS_a092_chgTempPhB "Power conversion system (on-board charger and DC-DC converter): a092 chg temp ph b";
CM_ SG_ 1060 PCS_a092_chgTempPhC "Power conversion system (on-board charger and DC-DC converter): a092 chg temp ph c";
CM_ SG_ 1060 PCS_a093_powerRail5VN "Power conversion system (on-board charger and DC-DC converter): a093 power rail5 VN";
CM_ SG_ 1060 PCS_a093_powerRail3V3 "Power conversion system (on-board charger and DC-DC converter): a093 power rail3 V3";
CM_ SG_ 1060 PCS_a093_powerRail1V5 "Power conversion system (on-board charger and DC-DC converter): a093 power rail1 V5";
CM_ SG_ 1060 PCS_a093_powerRail1V2 "Power conversion system (on-board charger and DC-DC converter): a093 power rail1 V2";
CM_ SG_ 1060 PCS_a093_irrational1V2Rail "Power conversion system (on-board charger and DC-DC converter): a093 irrational1 V2 rail";
CM_ SG_ 1060 PCS_a093_irrational1V5Rail "Power conversion system (on-board charger and DC-DC converter): a093 irrational1 V5 rail";
CM_ SG_ 1060 PCS_a093_irrational3V3Rail "Power conversion system (on-board charger and DC-DC converter): a093 irrational3 V3 rail";
CM_ SG_ 1060 PCS_a093_irrational5VNRail "Power conversion system (on-board charger and DC-DC converter): a093 irrational5 VN rail";
CM_ SG_ 1060 PCS_a094_malfunctionCode "Power conversion system (on-board charger and DC-DC converter): a094 malfunction code";
CM_ SG_ 1060 PCS_a095_powerRail5VN "Power conversion system (on-board charger and DC-DC converter): a095 power rail5 VN";
CM_ SG_ 1060 PCS_a095_pcsControlRequest "Power conversion system (on-board charger and DC-DC converter): a095 pcs control request";
CM_ SG_ 1060 PCS_a096_gridConfig "Power conversion system (on-board charger and DC-DC converter): a096 grid config";
CM_ SG_ 1060 PCS_a096_phAFrequency "Power conversion system (on-board charger and DC-DC converter): a096 ph a frequency";
CM_ SG_ 1060 PCS_a096_phBFrequency "Power conversion system (on-board charger and DC-DC converter): a096 ph b frequency";
CM_ SG_ 1060 PCS_a096_phCFrequency "Power conversion system (on-board charger and DC-DC converter): a096 ph c frequency";
CM_ SG_ 1060 PCS_a097_phADamaged "Power conversion system (on-board charger and DC-DC converter): a097 ph a damaged";
CM_ SG_ 1060 PCS_a097_phBDamaged "Power conversion system (on-board charger and DC-DC converter): a097 ph b damaged";
CM_ SG_ 1060 PCS_a097_phCDamaged "Power conversion system (on-board charger and DC-DC converter): a097 ph c damaged";
CM_ SG_ 1060 PCS_a097_phANVRAMStoredState "Power conversion system (on-board charger and DC-DC converter): a097 ph ANVRAM stored state";
CM_ SG_ 1060 PCS_a097_phBNVRAMStoredState "Power conversion system (on-board charger and DC-DC converter): a097 ph BNVRAM stored state";
CM_ SG_ 1060 PCS_a097_phCNVRAMStoredState "Power conversion system (on-board charger and DC-DC converter): a097 ph CNVRAM stored state";
CM_ SG_ 1060 PCS_a100_inputVrms "Power conversion system (on-board charger and DC-DC converter): a100 input vrms";
CM_ SG_ 1060 PCS_a100_phIntBusVolt "Power conversion system (on-board charger and DC-DC converter): a100 ph int bus volt";
CM_ SG_ 1060 PCS_a100_phKwhCounter "Power conversion system (on-board charger and DC-DC converter): a100 ph kwh counter";
CM_ SG_ 1060 PCS_a100_phKwhCounterDeltaFromMa "Power conversion system (on-board charger and DC-DC converter): a100 ph kwh counter delta from max";
CM_ SG_ 1060 PCS_a102_pcsControlRequest "Power conversion system (on-board charger and DC-DC converter): a102 pcs control request";
CM_ SG_ 1060 PCS_a102_NMIFlagRegisters "Power conversion system (on-board charger and DC-DC converter): a102 NMI flag registers";
CM_ SG_ 1060 PCS_a102_systemResetRegisters "Power conversion system (on-board charger and DC-DC converter): a102 system reset registers";
CM_ SG_ 1060 PCS_a102_dcdcEnableLine "Power conversion system (on-board charger and DC-DC converter): a102 dcdc enable line";
CM_ SG_ 1060 PCS_a104_ambientTemperature "Power conversion system (on-board charger and DC-DC converter): a104 ambient temperature";
CM_ SG_ 1060 PCS_a107_VC_pcsInterface "Power conversion system (on-board charger and DC-DC converter): a107 VC pcs interface";
CM_ SG_ 1060 PCS_a108_installedInAWrongPlatfo "Power conversion system (on-board charger and DC-DC converter): a108 installed in a wrong platform";
CM_ SG_ 1060 PCS_a109_inputL2NVrms "Power conversion system (on-board charger and DC-DC converter): a109 input L2 n vrms";
CM_ SG_ 1060 PCS_a109_inputL3NVrms "Power conversion system (on-board charger and DC-DC converter): a109 input L3 n vrms";
CM_ BO_ 932 "Power conversion system (on-board charger and DC-DC converter) message: alert matrix";
CM_ SG_ 932 PCS_matrixIndex "Power conversion system (on-board charger and DC-DC converter): matrix index";
CM_ SG_ 932 PCS_a001_chgHwInputOc "Power conversion system (on-board charger and DC-DC converter): a001 chg hw input oc";
CM_ SG_ 932 PCS_a002_chgHwOutputOc "Power conversion system (on-board charger and DC-DC converter): a002 chg hw output oc";
CM_ SG_ 932 PCS_a003_chgHwInputOv "Power conversion system (on-board charger and DC-DC converter): a003 chg hw input ov";
CM_ SG_ 932 PCS_a004_chgHwIntBusOv "Power conversion system (on-board charger and DC-DC converter): a004 chg hw int bus ov";
CM_ SG_ 932 PCS_a005_chgOutputOv "Power conversion system (on-board charger and DC-DC converter): a005 chg output ov";
CM_ SG_ 932 PCS_a006_chgPrechargeFailedScr "Power conversion system (on-board charger and DC-DC converter): a006 chg precharge failed scr";
CM_ SG_ 932 PCS_a007_chgPhaseTempHot "Power conversion system (on-board charger and DC-DC converter): a007 chg phase temp hot";
CM_ SG_ 932 PCS_a008_chgPhaseOverTemp "Power conversion system (on-board charger and DC-DC converter): a008 chg phase over temp";
CM_ SG_ 932 PCS_a009_chgPfcCurrentRegulation "Power conversion system (on-board charger and DC-DC converter): a009 chg pfc current regulation";
CM_ SG_ 932 PCS_a010_chgIntBusVRegulation "Power conversion system (on-board charger and DC-DC converter): a010 chg int bus v regulation";
CM_ SG_ 932 PCS_a011_chgLlcCurrentRegulation "Power conversion system (on-board charger and DC-DC converter): a011 chg llc current regulation";
CM_ SG_ 932 PCS_a012_chgPfcIBandTracerFault "Power conversion system (on-board charger and DC-DC converter): a012 chg pfc i band tracer fault";
CM_ SG_ 932 PCS_a013_chgPrechargeFailedBoost "Power conversion system (on-board charger and DC-DC converter): a013 chg precharge failed boost";
CM_ SG_ 932 PCS_a014_chgTempRationality "Power conversion system (on-board charger and DC-DC converter): a014 chg temp rationality";
CM_ SG_ 932 PCS_a015_chg12vUv "Power conversion system (on-board charger and DC-DC converter): a015 chg12v uv";
CM_ SG_ 932 PCS_a016_chgAllPhasesFaulted "Power conversion system (on-board charger and DC-DC converter): a016 chg all phases faulted";
CM_ SG_ 932 PCS_a017_chgWallPowerRemoval "Power conversion system (on-board charger and DC-DC converter): a017 chg wall power removal";
CM_ SG_ 932 PCS_a018_chgUnknownGridConfig "Power conversion system (on-board charger and DC-DC converter): a018 chg unknown grid config";
CM_ SG_ 932 PCS_a019_acChargePowerLimited "Power conversion system (on-board charger and DC-DC converter): a019 ac charge power limited";
CM_ SG_ 932 PCS_a020_chgEnableLineMismatch "Power conversion system (on-board charger and DC-DC converter): a020 chg enable line mismatch";
CM_ SG_ 932 PCS_a021_hvpMia "Power conversion system (on-board charger and DC-DC converter): a021 hvp mia";
CM_ SG_ 932 PCS_a022_bmsMia "Power conversion system (on-board charger and DC-DC converter): a022 bms mia";
CM_ SG_ 932 PCS_a023_cpMia "Power conversion system (on-board charger and DC-DC converter): a023 cp mia";
CM_ SG_ 932 PCS_a024_vcfrontMia "Power conversion system (on-board charger and DC-DC converter): a024 vcfront mia";
CM_ SG_ 932 PCS_a025_cpu2Malfunction "Power conversion system (on-board charger and DC-DC converter): a025 cpu2 malfunction";
CM_ SG_ 932 PCS_a026_watchdogAlarmed "Power conversion system (on-board charger and DC-DC converter): a026 watchdog alarmed";
CM_ SG_ 932 PCS_a027_chgInsufficientCooling "Power conversion system (on-board charger and DC-DC converter): a027 chg insufficient cooling";
CM_ SG_ 932 PCS_a028_chgOutputUv "Power conversion system (on-board charger and DC-DC converter): a028 chg output uv";
CM_ SG_ 932 PCS_a029_chgPowerRationality "Power conversion system (on-board charger and DC-DC converter): a029 chg power rationality";
CM_ SG_ 932 PCS_a030_canRationality "Power conversion system (on-board charger and DC-DC converter): a030 can rationality";
CM_ SG_ 932 PCS_a031_uiMia "Power conversion system (on-board charger and DC-DC converter): a031 ui mia";
CM_ SG_ 932 PCS_a032_excessiveGridTransients "Power conversion system (on-board charger and DC-DC converter): a032 excessive grid transients detected";
CM_ SG_ 932 PCS_a033_hvBusUv "Power conversion system (on-board charger and DC-DC converter): a033 hv bus uv";
CM_ SG_ 932 PCS_a034_hvBusOv "Power conversion system (on-board charger and DC-DC converter): a034 hv bus ov";
CM_ SG_ 932 PCS_a035_lvBusUv "Power conversion system (on-board charger and DC-DC converter): a035 lv bus uv";
CM_ SG_ 932 PCS_a036_lvBusOv "Power conversion system (on-board charger and DC-DC converter): a036 lv bus ov";
CM_ SG_ 932 PCS_a037_resonantTankOc "Power conversion system (on-board charger and DC-DC converter): a037 resonant tank oc";
CM_ SG_ 932 PCS_a038_claFaulted "Power conversion system (on-board charger and DC-DC converter): a038 cla faulted";
CM_ SG_ 932 PCS_a039_sdModuleClkFault "Power conversion system (on-board charger and DC-DC converter): a039 sd module clk fault";
CM_ SG_ 932 PCS_a040_dcdcMaxPowerReached "Power conversion system (on-board charger and DC-DC converter): a040 dcdc max power reached";
CM_ SG_ 932 PCS_a041_dcdcOverTemp "Power conversion system (on-board charger and DC-DC converter): a041 dcdc over temp";
CM_ SG_ 932 PCS_a042_dcdcEnableLineMismatch "Power conversion system (on-board charger and DC-DC converter): a042 dcdc enable line mismatch";
CM_ SG_ 932 PCS_a043_hvBusPrechargeFailure "Power conversion system (on-board charger and DC-DC converter): a043 hv bus precharge failure";
CM_ SG_ 932 PCS_a044_12vSupportRegulation "Power conversion system (on-board charger and DC-DC converter): a044 12v support regulation";
CM_ SG_ 932 PCS_a045_hvBusLowImpedance "Power conversion system (on-board charger and DC-DC converter): a045 hv bus low impedance";
CM_ SG_ 932 PCS_a046_hvBusHighImpedence "Power conversion system (on-board charger and DC-DC converter): a046 hv bus high impedence";
CM_ SG_ 932 PCS_a047_bootloaderCrcMismatch "Power conversion system (on-board charger and DC-DC converter): a047 bootloader crc mismatch";
CM_ SG_ 932 PCS_a048_softwareAssertion "Power conversion system (on-board charger and DC-DC converter): a048 software assertion";
CM_ SG_ 932 PCS_a049_dcdcTempRationality "Power conversion system (on-board charger and DC-DC converter): a049 dcdc temp rationality";
CM_ SG_ 932 PCS_a050_dcdc12VsupportFaulted "Power conversion system (on-board charger and DC-DC converter): a050 dcdc12 vsupport faulted";
CM_ SG_ 932 PCS_a051_chgIntBusUv "Power conversion system (on-board charger and DC-DC converter): a051 chg int bus uv";
CM_ SG_ 932 PCS_a052_acVoltageNotPresent "Power conversion system (on-board charger and DC-DC converter): a052 ac voltage not present";
CM_ SG_ 932 PCS_a053_chgInputVDropHigh "Power conversion system (on-board charger and DC-DC converter): a053 chg input v drop high";
CM_ SG_ 932 PCS_a054_chgInputVDropTooHigh "Power conversion system (on-board charger and DC-DC converter): a054 chg input v drop too high";
CM_ SG_ 932 PCS_a055_chgLineImpedanceHigh "Power conversion system (on-board charger and DC-DC converter): a055 chg line impedance high";
CM_ SG_ 932 PCS_a056_chgLineImpedanceTooHigh "Power conversion system (on-board charger and DC-DC converter): a056 chg line impedance too high";
CM_ SG_ 932 PCS_a057_chgInputOverFreq "Power conversion system (on-board charger and DC-DC converter): a057 chg input over freq";
CM_ SG_ 932 PCS_a058_chgInputUnderFreq "Power conversion system (on-board charger and DC-DC converter): a058 chg input under freq";
CM_ SG_ 932 PCS_a059_chgInputOvRms "Power conversion system (on-board charger and DC-DC converter): a059 chg input ov rms";
CM_ SG_ 932 PCS_a060_chgInputOvPeak "Power conversion system (on-board charger and DC-DC converter): a060 chg input ov peak";
CM_ SG_ 932 PCS_a061_chgVLineRationality "Power conversion system (on-board charger and DC-DC converter): a061 chg v line rationality";
CM_ SG_ 932 PCS_a062_chgILineRationality "Power conversion system (on-board charger and DC-DC converter): a062 chg i line rationality";
CM_ SG_ 932 PCS_a063_chgVOutRationality "Power conversion system (on-board charger and DC-DC converter): a063 chg v out rationality";
CM_ SG_ 932 PCS_a064_chgIOutRationality "Power conversion system (on-board charger and DC-DC converter): a064 chg i out rationality";
CM_ SG_ 932 PCS_a065_chgPllNotLocked "Power conversion system (on-board charger and DC-DC converter): a065 chg pll not locked";
CM_ SG_ 932 PCS_a066_dcdcHvRationality "Power conversion system (on-board charger and DC-DC converter): a066 dcdc hv rationality";
CM_ SG_ 932 PCS_a067_dcdcLvRationality "Power conversion system (on-board charger and DC-DC converter): a067 dcdc lv rationality";
CM_ SG_ 932 PCS_a068_dcdcTankvRationality "Power conversion system (on-board charger and DC-DC converter): a068 dcdc tankv rationality";
CM_ SG_ 932 PCS_a069_chgPfcLineDidt "Power conversion system (on-board charger and DC-DC converter): a069 chg pfc line didt";
CM_ SG_ 932 PCS_a070_chgPfcLineDvdt "Power conversion system (on-board charger and DC-DC converter): a070 chg pfc line dvdt";
CM_ SG_ 932 PCS_a071_chgPfcILoopRationality "Power conversion system (on-board charger and DC-DC converter): a071 chg pfc i loop rationality";
CM_ SG_ 932 PCS_a072_cpu2ClaStopped "Power conversion system (on-board charger and DC-DC converter): a072 cpu2 cla stopped";
CM_ SG_ 932 PCS_a073_unexpectedAcInputVoltag "Power conversion system (on-board charger and DC-DC converter): a073 unexpected ac input voltage";
CM_ SG_ 932 PCS_a074_hvBusDischargeFailure "Power conversion system (on-board charger and DC-DC converter): a074 hv bus discharge failure";
CM_ SG_ 932 PCS_a075_hvBusDischargeTimeout "Power conversion system (on-board charger and DC-DC converter): a075 hv bus discharge timeout";
CM_ SG_ 932 PCS_a076_dcdcEnDeassertedErr "Power conversion system (on-board charger and DC-DC converter): a076 dcdc en deasserted err";
CM_ SG_ 932 PCS_a077_microGridWobbleDetected "Power conversion system (on-board charger and DC-DC converter): a077 micro grid wobble detected";
CM_ SG_ 932 PCS_a078_chgStopDcdcTooHot "Power conversion system (on-board charger and DC-DC converter): a078 chg stop dcdc too hot";
CM_ SG_ 932 PCS_a079_eepromOperationError "Power conversion system (on-board charger and DC-DC converter): a079 eeprom operation error";
CM_ SG_ 932 PCS_a080_damagedPhaseDetected "Power conversion system (on-board charger and DC-DC converter): a080 damaged phase detected";
CM_ SG_ 932 PCS_a081_dcdcPchgTimeout "Power conversion system (on-board charger and DC-DC converter): a081 dcdc pchg timeout";
CM_ SG_ 932 PCS_a082_dcdcPchgUnsafeDiVoltage "Power conversion system (on-board charger and DC-DC converter): a082 dcdc pchg unsafe di voltage";
CM_ SG_ 932 PCS_a083_triggerOdin "Signal reported by Power conversion system (on-board charger and DC-DC converter)";
CM_ SG_ 932 PCS_a084_vDropFastInParasiticDio "Power conversion system (on-board charger and DC-DC converter): a084 v drop fast in parasitic diode region";
CM_ SG_ 932 PCS_a085_dcdcFetsNotSwitching "Power conversion system (on-board charger and DC-DC converter): a085 dcdc fets not switching";
CM_ SG_ 932 PCS_a086_dcdcInsufficientCooling "Power conversion system (on-board charger and DC-DC converter): a086 dcdc insufficient cooling";
CM_ SG_ 932 PCS_a087_nvramRecordStatusError "Power conversion system (on-board charger and DC-DC converter): a087 nvram record status error";
CM_ SG_ 932 PCS_a088_gridFreqDroopDetected "Power conversion system (on-board charger and DC-DC converter): a088 grid freq droop detected";
CM_ SG_ 932 PCS_a089_hvBusDischargeIrrationa "Power conversion system (on-board charger and DC-DC converter): a089 hv bus discharge irrational";
CM_ SG_ 932 PCS_a090_expectedAcVoltageSource "Power conversion system (on-board charger and DC-DC converter): a090 expected ac voltage source missing";
CM_ SG_ 932 PCS_a091_chgIntBusRationality "Power conversion system (on-board charger and DC-DC converter): a091 chg int bus rationality";
CM_ SG_ 932 PCS_a092_chgPowerLimitedByBusRip "Power conversion system (on-board charger and DC-DC converter): a092 chg power limited by bus ripple";
CM_ SG_ 932 PCS_a093_powerRailRationality "Power conversion system (on-board charger and DC-DC converter): a093 power rail rationality";
CM_ SG_ 932 PCS_a094_pcsDcdcNeedService "Power conversion system (on-board charger and DC-DC converter): a094 pcs dcdc need service";
CM_ SG_ 932 PCS_a095_dcdcSensorlessModeActiv "Power conversion system (on-board charger and DC-DC converter): a095 dcdc sensorless mode active";
CM_ SG_ 932 PCS_a096_microGridOverLoaded "Power conversion system (on-board charger and DC-DC converter): a096 micro grid over loaded";
CM_ SG_ 932 PCS_a097_rebootPhaseDetected "Power conversion system (on-board charger and DC-DC converter): a097 reboot phase detected";
CM_ SG_ 932 PCS_a098_gridFreqDroopDetectedSi "Power conversion system (on-board charger and DC-DC converter): a098 grid freq droop detected silent";
CM_ SG_ 932 PCS_a099_microGridOverLoadedSile "Power conversion system (on-board charger and DC-DC converter): a099 micro grid over loaded silent";
CM_ SG_ 932 PCS_a100_suspectedViperChipIssue "Power conversion system (on-board charger and DC-DC converter): a100 suspected viper chip issue";
CM_ SG_ 932 PCS_a101_phMachineModelIrrationa "Power conversion system (on-board charger and DC-DC converter): a101 ph machine model irrational";
CM_ SG_ 932 PCS_a102_resetWithDCDCCmdAsserte "Power conversion system (on-board charger and DC-DC converter): a102 reset with DCDC cmd asserted";
CM_ SG_ 932 PCS_a103_pchgWithLowLvDetected "Power conversion system (on-board charger and DC-DC converter): a103 pchg with low lv detected";
CM_ SG_ 932 PCS_a104_ambientTempRationality "Power conversion system (on-board charger and DC-DC converter): a104 ambient temp rationality";
CM_ SG_ 932 PCS_a105_redundantVoltageSourceI "Power conversion system (on-board charger and DC-DC converter): a105 redundant voltage source irrational";
CM_ SG_ 932 PCS_a106_clockSourceNotFromExter "Power conversion system (on-board charger and DC-DC converter): a106 clock source not from external crystal";
CM_ SG_ 932 PCS_a107_vcPcsDCDCInterfaceMia "Power conversion system (on-board charger and DC-DC converter): a107 vc pcs DCDC interface mia";
CM_ SG_ 932 PCS_a108_misconfigurationDetecte "Power conversion system (on-board charger and DC-DC converter): a108 misconfiguration detected";
CM_ SG_ 932 PCS_a109_deltaChargingL2L3Swappe "Power conversion system (on-board charger and DC-DC converter): a109 delta charging L2 L3 swapped detected";
CM_ SG_ 932 PCS_d110_dcdcNeedsService "Power conversion system (on-board charger and DC-DC converter): d110 dcdc needs service";
CM_ SG_ 932 PCS_d111_batteryChargerPowerLimi "Power conversion system (on-board charger and DC-DC converter): d111 battery charger power limited";
CM_ SG_ 932 PCS_d112_logicHardwareIssue "Power conversion system (on-board charger and DC-DC converter): d112 logic hardware issue";
CM_ SG_ 932 PCS_d113_dcdcConverterTempSensor "Power conversion system (on-board charger and DC-DC converter): d113 dcdc converter temp sensor a issue";
CM_ SG_ 932 PCS_d114_dcdcConverterVoltSensor "Power conversion system (on-board charger and DC-DC converter): d114 dcdc converter volt sensor a issue";
CM_ SG_ 932 PCS_d115_dcdcConverterTempSensor "Power conversion system (on-board charger and DC-DC converter): d115 dcdc converter temp sensor b issue";
CM_ SG_ 932 PCS_d116_dcdcConverterVoltSensor "Power conversion system (on-board charger and DC-DC converter): d116 dcdc converter volt sensor b issue";
CM_ BO_ 612 "Power conversion system (on-board charger and DC-DC converter) message: chg line status";
CM_ SG_ 612 PCS_chgInputVoltage "RMS value of AC charger's sensed input voltage";
CM_ SG_ 612 PCS_chgLineCurrent "AC charger's sensed input line current";
CM_ SG_ 612 PCS_chgAcVoltagePresent "Indicates whether AC voltage is present on the PCS input";
CM_ SG_ 612 PCS_chgInputPower "Total AC charger input power";
CM_ SG_ 612 PCS_chgAcCurrentLimit "Maximum AC current that can be pulled from a single conductor";
CM_ BO_ 516 "Power conversion system (on-board charger and DC-DC converter) message: chg status";
CM_ SG_ 516 PCS_chgMainState "Power conversion system (on-board charger and DC-DC converter): chg main state";
CM_ SG_ 516 PCS_powerTransferStatus "Reports the AC power transfer interface state of the Power Conversion System (PCS).";
CM_ SG_ 516 PCS_gridConfig "AC charger sensed grid configuration";
CM_ SG_ 516 PCS_chgPHAEnable "Indicates whether AC charger phase A is enabled";
CM_ SG_ 516 PCS_chgPHBEnable "Indicates whether AC charger phase B is enabled";
CM_ SG_ 516 PCS_hvInletConductorEnergizedAc "Power conversion system (on-board charger and DC-DC converter): hv inlet conductor energized ac";
CM_ SG_ 516 PCS_chgHighPowerActive "Power conversion system (on-board charger and DC-DC converter): chg high power active";
CM_ SG_ 516 PCS_chgPHCEnable "Indicates whether AC charger phase C is enabled";
CM_ SG_ 516 PCS_chgInstantAcPowerAvailable "Instantaneous power capability of the AC charger";
CM_ SG_ 516 PCS_chgMaxAcPowerAvailable "Maximum power capability of the AC charger";
CM_ SG_ 516 PCS_chgPHALineCurrentRequest "AC charger phase A input current command";
CM_ SG_ 516 PCS_chgPHBLineCurrentRequest "AC charger phase B input current command";
CM_ SG_ 516 PCS_chgPHCLineCurrentRequest "AC charger phase B input current command";
CM_ SG_ 516 PCS_chgPwmEnableLine "Sensed state of the charger PWM enable hardline";
CM_ SG_ 516 PCS_powerTransferShutdownRequest "The Power Conversion System (PCS) request to shut down AC power transfer.";
CM_ SG_ 516 PCS_hwVariantType "Hardware variant of AC charger";
CM_ SG_ 516 PCS_dcacBidirectionalAllowed "Indicates whether bidirectional DCAC capability is supported by this PCS variant";
CM_ BO_ 692 "Power conversion system (on-board charger and DC-DC converter) message: dcdc rail status";
CM_ SG_ 692 PCS_dcdcLvBusVolt "DCDC's sensed LV bus voltage";
CM_ SG_ 692 PCS_dcdcHvBusVolt "DCDC's sensed HV bus voltage";
CM_ SG_ 692 PCS_dcdcLvOutputCurrent "DCDC's computed LV output current";
CM_ BO_ 548 "Power conversion system (on-board charger and DC-DC converter) message: dcdc status";
CM_ SG_ 548 PCS_dcdcPrechargeStatus "Status of DCDC HV bus precharge";
CM_ SG_ 548 PCS_dcdcLvSupportStatus "Status of DCDC LV support";
CM_ SG_ 548 PCS_dcdcHvBusDischargeStatus "Power conversion system (on-board charger and DC-DC converter): dcdc hv bus discharge status";
CM_ SG_ 548 PCS_coldSleepAllowed "Power conversion system (on-board charger and DC-DC converter): cold sleep allowed";
CM_ SG_ 548 PCS_dcdcPchgHVBusLowRDetected "Power conversion system (on-board charger and DC-DC converter): dcdc pchg HV bus low r detected";
CM_ SG_ 548 PCS_dcdcSubState "Substate of DCDC state machine";
CM_ SG_ 548 PCS_dcdcFaulted "Whether the DCDC is in faulted state";
CM_ SG_ 548 PCS_dcdcEn13V5WithStrongPullup "Indicates if PCS-Mini has the Vehicle Controller Right (VCR) DCDC enable line 13.5 V strong pull-up (true) or 3.3 V direct (false).";
CM_ SG_ 548 PCS_okToBePowerCycled "Power conversion system (on-board charger and DC-DC converter): ok to be power cycled";
CM_ SG_ 548 PCS_dcdcOutputIsLimited "Whether the DCDC's output is current limiting";
CM_ SG_ 548 PCS_dcdcMaxOutputCurrentAllowed "Maximum LV output current capability of DCDC based on operating point";
CM_ SG_ 548 PCS_dcdcPrechargeRtyCnt "Power conversion system (on-board charger and DC-DC converter): dcdc precharge rty cnt";
CM_ SG_ 548 PCS_dcdcLvSupportRtyCnt "Power conversion system (on-board charger and DC-DC converter): dcdc lv support rty cnt";
CM_ SG_ 548 PCS_dcdcDischargeRtyCnt "Power conversion system (on-board charger and DC-DC converter): dcdc discharge rty cnt";
CM_ SG_ 548 PCS_dcdcPwmEnableLine "Sensed state of the DCDC PWM enable hardline";
CM_ SG_ 548 PCS_dcdcSupportingFixedLvTarget "Whether DCDC is running LV support at a fixed voltage target";
CM_ SG_ 548 PCS_ecuLogUploadRequest "Power conversion system (on-board charger and DC-DC converter): ecu log upload request";
CM_ SG_ 548 PCS_dcdcPrechargeRestartCnt "Power conversion system (on-board charger and DC-DC converter): dcdc precharge restart cnt";
CM_ SG_ 548 PCS_dcdcInitialPrechargeSubState "Power conversion system (on-board charger and DC-DC converter): dcdc initial precharge sub state";
CM_ BO_ 964 "Power conversion system (on-board charger and DC-DC converter) message: info";
CM_ SG_ 964 PCS_infoIndex "Power conversion system (on-board charger and DC-DC converter): info index";
CM_ SG_ 964 PCS_buildType "Power conversion system (on-board charger and DC-DC converter): build type";
CM_ SG_ 964 PCS_buildConfigId "Power conversion system (on-board charger and DC-DC converter): build config id";
CM_ SG_ 964 PCS_hardwareId "Power conversion system (on-board charger and DC-DC converter): hardware id";
CM_ SG_ 964 PCS_componentId "Power conversion system (on-board charger and DC-DC converter): component id";
CM_ SG_ 964 PCS_pcbaId "PCBA ID portion of component hardware ID as reported by application";
CM_ SG_ 964 PCS_assemblyId "Power conversion system (on-board charger and DC-DC converter): assembly id";
CM_ SG_ 964 PCS_usageId "Usage ID portion of component hardware ID as reported by application";
CM_ SG_ 964 PCS_subUsageId "Sub-usage ID portion of component hardware ID as reported by application";
CM_ SG_ 964 PCS_platformType "Power conversion system (on-board charger and DC-DC converter): platform type";
CM_ SG_ 964 PCS_appCrc "Power conversion system (on-board charger and DC-DC converter): app crc";
CM_ SG_ 964 PCS_cpu2AppCrc "Power conversion system (on-board charger and DC-DC converter): cpu2 app crc";
CM_ SG_ 964 PCS_appGitHash "Power conversion system (on-board charger and DC-DC converter): app git hash";
CM_ SG_ 964 PCS_bootGitHash "Power conversion system (on-board charger and DC-DC converter): boot git hash";
CM_ SG_ 964 PCS_bootUdsProtoVersion "Power conversion system (on-board charger and DC-DC converter): boot uds proto version";
CM_ SG_ 964 PCS_bootCrc "Power conversion system (on-board charger and DC-DC converter): boot crc";
CM_ BO_ 708 "Power conversion system (on-board charger and DC-DC converter) message: logging";
CM_ SG_ 708 PCS_logMessageSelect "Power conversion system (on-board charger and DC-DC converter): log message select";
CM_ SG_ 708 PCS_chgPhAInputIrms "AC charger phase A's sensed RMS input current";
CM_ SG_ 708 PCS_chgPhAIntBusV "AC charger phase A's sensed intermediate bus voltage";
CM_ SG_ 708 PCS_chgPhAIntBusVTarget "AC charger phase A's intermediate bus voltage target";
CM_ SG_ 708 PCS_chgPhAOutputI "AC charger phase A sensed output current";
CM_ SG_ 708 PCS_chgPhAInputCurrentLimitReaso "Provides the reason behind the input AC charging current limit for phase A";
CM_ SG_ 708 PCS_chgPhBInputIrms "AC charger phase B's sensed RMS input current";
CM_ SG_ 708 PCS_chgPhBIntBusV "AC charger phase B's sensed intermediate bus voltage";
CM_ SG_ 708 PCS_chgPhBIntBusVTarget "AC charger phase B's intermediate bus voltage target";
CM_ SG_ 708 PCS_chgPhBOutputI "AC charger phase B sensed output current";
CM_ SG_ 708 PCS_chgPhBInputCurrentLimitReaso "Provides the reason behind the input AC charging current limit for phase B";
CM_ SG_ 708 PCS_chgPhCInputIrms "AC charger phase C's sensed RMS input current";
CM_ SG_ 708 PCS_chgPhCIntBusV "AC charger phase C's sensed intermediate bus voltage";
CM_ SG_ 708 PCS_chgPhCIntBusVTarget "AC charger phase C's intermediate bus voltage target";
CM_ SG_ 708 PCS_chgPhCOutputI "AC charger phase C sensed output current";
CM_ SG_ 708 PCS_chgPhCInputCurrentLimitReaso "Provides the reason behind the input AC charging current limit for phase C";
CM_ SG_ 708 PCS_chgInputL1NVrms "AC charger's sensed AC RMS voltage of L1-N voltage source";
CM_ SG_ 708 PCS_chgInputL2NVrms "AC charger's sensed AC RMS voltage of L2-N voltage source";
CM_ SG_ 708 PCS_chgInputL3NVrms "AC charger's sensed AC RMS voltage of L3-N voltage source";
CM_ SG_ 708 PCS_chgInputL1L2Vrms "AC charger's sensed input frequency of L2-N voltage source";
CM_ SG_ 708 PCS_chgInputNGVrms "AC charger's sensed AC RMS voltage of N-G voltage source";
CM_ SG_ 708 PCS_chgInputFrequencyL1N "AC charger's sensed input frequency of L1-N voltage source";
CM_ SG_ 708 PCS_chgInputFrequencyL2N "AC charger's sensed input frequency of L2-N voltage source";
CM_ SG_ 708 PCS_chgInputFrequencyL3N "AC charger's sensed input frequency of L3-N voltage source";
CM_ SG_ 708 PCS_chgInternalPhaseConfig "Internal phase configuration of the AC charger (three phase vs. single phase)";
CM_ SG_ 708 PCS_chgPhasesPriority "AC charger phase manager's priority logic for enabling phases in single phase PCS variant";
CM_ SG_ 708 PCS_chgOutputV "Sensed output voltage of AC charger";
CM_ SG_ 708 PCS_chgPhAState "State of AC charger phase A";
CM_ SG_ 708 PCS_chgPhBState "State of AC charger phase B";
CM_ SG_ 708 PCS_chgPhCState "State of AC charger phase C";
CM_ SG_ 708 PCS_chgPhALastShutdownReason "Last reason for shutting down AC charger phase A";
CM_ SG_ 708 PCS_chgPhBLastShutdownReason "Last reason for shutting down AC charger phase B";
CM_ SG_ 708 PCS_chgPhCLastShutdownReason "Last reason for shutting down AC charger phase C";
CM_ SG_ 708 PCS_chgPhARetryCount "AC charger phase A number of retries used during the current charge session";
CM_ SG_ 708 PCS_chgPhBRetryCount "AC charger phase B number of retries used during the current charge session";
CM_ SG_ 708 PCS_chgPhCRetryCount "AC charger phase C number of retries used during the current charge session";
CM_ SG_ 708 PCS_chgRetryCount "AC charger number of system level retries used during the current charge session";
CM_ SG_ 708 PCS_chgPhManCurrentToDist "Power conversion system (on-board charger and DC-DC converter): chg ph man current to dist";
CM_ SG_ 708 PCS_chgL1NPllLocked "Power conversion system (on-board charger and DC-DC converter): chg L1 n pll locked";
CM_ SG_ 708 PCS_chgL2NPllLocked "Power conversion system (on-board charger and DC-DC converter): chg L2 n pll locked";
CM_ SG_ 708 PCS_chgL3NPllLocked "Power conversion system (on-board charger and DC-DC converter): chg L3 n pll locked";
CM_ SG_ 708 PCS_chgL1L2PllLocked "Power conversion system (on-board charger and DC-DC converter): chg L1 L2 pll locked";
CM_ SG_ 708 PCS_chgNgPllLocked "Power conversion system (on-board charger and DC-DC converter): chg ng pll locked";
CM_ SG_ 708 PCS_chgPhManOptimalPhsToUse "Power conversion system (on-board charger and DC-DC converter): chg ph man optimal phs to use";
CM_ SG_ 708 PCS_chg5VL1Enable "Power conversion system (on-board charger and DC-DC converter): chg5 VL1 enable";
CM_ SG_ 708 PCS_dcdcMaxLvOutputCurrent "Overall maxmum LV output current capability of DCDC";
CM_ SG_ 708 PCS_dcdcCurrentLimit "Power conversion system (on-board charger and DC-DC converter): dcdc current limit";
CM_ SG_ 708 PCS_dcdcLvOutputCurrentTempLimit "Maximum LV output current capability of DCDC based on thermals";
CM_ SG_ 708 PCS_dcdcLvOutputCurrentFiltered "DCDC's filtered LV output current";
CM_ SG_ 708 PCS_dcdcUnifiedCommand "Power conversion system (on-board charger and DC-DC converter): dcdc unified command";
CM_ SG_ 708 PCS_dcdcCLAControllerOutput "Power conversion system (on-board charger and DC-DC converter): dcdc CLA controller output";
CM_ SG_ 708 PCS_dcdcTankVoltage "Power conversion system (on-board charger and DC-DC converter): dcdc tank voltage";
CM_ SG_ 708 PCS_dcdcTankVoltageTarget "Power conversion system (on-board charger and DC-DC converter): dcdc tank voltage target";
CM_ SG_ 708 PCS_dcdcClaCurrentFreq "Power conversion system (on-board charger and DC-DC converter): dcdc cla current freq";
CM_ SG_ 708 PCS_dcdcTCommMeasured "Power conversion system (on-board charger and DC-DC converter): dcdc t comm measured";
CM_ SG_ 708 PCS_dcdcShortTimeUs "Power conversion system (on-board charger and DC-DC converter): dcdc short time us";
CM_ SG_ 708 PCS_dcdcHalfPeriodUs "Power conversion system (on-board charger and DC-DC converter): dcdc half period us";
CM_ SG_ 708 PCS_dcdcLvBusVoltTargetWithOffse "LV support Voltage target with Feed-forward offset";
CM_ SG_ 708 PCS_cpu2BootState "Power conversion system (on-board charger and DC-DC converter): cpu2 boot state";
CM_ SG_ 708 PCS_acChargeSelfTestState "Power conversion system (on-board charger and DC-DC converter): ac charge self test state";
CM_ SG_ 708 PCS_1V5Min10s "Power conversion system (on-board charger and DC-DC converter): 1 V5 min10s";
CM_ SG_ 708 PCS_1V5Max10s "Power conversion system (on-board charger and DC-DC converter): 1 V5 max10s";
CM_ SG_ 708 PCS_1V2Min10s "Power conversion system (on-board charger and DC-DC converter): 1 V2 min10s";
CM_ SG_ 708 PCS_1V2Max10s "Power conversion system (on-board charger and DC-DC converter): 1 V2 max10s";
CM_ SG_ 708 PCS_5VNMax10s "Power conversion system (on-board charger and DC-DC converter): 5 VN max10s";
CM_ SG_ 708 PCS_chgPhAIntBusVMin10s "AC charger phase A's minimum sensed intermediate bus voltage over the last ten seconds";
CM_ SG_ 708 PCS_chgPhAIntBusVMax10s "AC charger phase A's maximum sensed intermediate bus voltage over the last ten seconds";
CM_ SG_ 708 PCS_chgPhAPchgVoltDeltaMax10s "AC charger phase A maximum sensed voltage delta between line and intermediate bus in the last 10 seconds during SCR precharge";
CM_ SG_ 708 PCS_chgPhALifetimekWh "Lifetime total energy throughput of AC charger phase A";
CM_ SG_ 708 PCS_chgPhATransientRetryCount "AC charger phase A number of transient retries used during the current charge session";
CM_ SG_ 708 PCS_chgPhBIntBusVMin10s "AC charger phase B's minimum sensed intermediate bus voltage over the last ten seconds";
CM_ SG_ 708 PCS_chgPhBIntBusVMax10s "AC charger phase B's maximum sensed intermediate bus voltage over the last ten seconds";
CM_ SG_ 708 PCS_chgPhBPchgVoltDeltaMax10s "AC charger phase B maximum sensed voltage delta between line and intermediate bus in the last 10 seconds during SCR precharge";
CM_ SG_ 708 PCS_chgPhBLifetimekWh "Lifetime total energy throughput of AC charger phase B";
CM_ SG_ 708 PCS_chgPhBTransientRetryCount "AC charger phase B number of transient retries used during the current charge session";
CM_ SG_ 708 PCS_chgPhCIntBusVMin10s "AC charger phase C's minimum sensed intermediate bus voltage over the last ten seconds";
CM_ SG_ 708 PCS_chgPhCIntBusVMax10s "AC charger phase C's maximum sensed intermediate bus voltage over the last ten seconds";
CM_ SG_ 708 PCS_chgPhCPchgVoltDeltaMax10s "AC charger phase C maximum sensed voltage delta between line and intermediate bus in the last 10 seconds during SCR precharge";
CM_ SG_ 708 PCS_chgPhCLifetimekWh "Lifetime total energy throughput of AC charger phase C";
CM_ SG_ 708 PCS_chgPhCTransientRetryCount "AC charger phase C number of transient retries used during the current charge session";
CM_ SG_ 708 PCS_chgPhANoFlowBucket "Power conversion system (on-board charger and DC-DC converter): chg ph a no flow bucket";
CM_ SG_ 708 PCS_chgPhBNoFlowBucket "Power conversion system (on-board charger and DC-DC converter): chg ph b no flow bucket";
CM_ SG_ 708 PCS_chgPhCNoFlowBucket "Power conversion system (on-board charger and DC-DC converter): chg ph c no flow bucket";
CM_ SG_ 708 PCS_chgCurrentSensorOutOfBandUs "Power conversion system (on-board charger and DC-DC converter): chg current sensor out of band us";
CM_ SG_ 708 PCS_chgAcpwHeartbeatState "A signal to indicate if PCS detects the heartbeat signature from AC Power Wall";
CM_ SG_ 708 PCS_chgKwhLostByFreqDroop "Power conversion system (on-board charger and DC-DC converter): chg kwh lost by freq droop";
CM_ SG_ 708 PCS_chgReqKwhLostByFreqDroop "Power conversion system (on-board charger and DC-DC converter): chg req kwh lost by freq droop";
CM_ SG_ 708 PCS_dcdcLvSupportLifetimekWh "Lifetime energy throughput of DCDC LV support mode";
CM_ SG_ 708 PCS_chgPwmEnableLineErrorCount "Power conversion system (on-board charger and DC-DC converter): chg pwm enable line error count";
CM_ SG_ 708 PCS_dcdcPwmEnableLineErrorCount "Number of deassertions detected for DCDC PWM enable line";
CM_ SG_ 708 PCS_numAlertsSet "Power conversion system (on-board charger and DC-DC converter): num alerts set";
CM_ SG_ 708 PCS_dcdcPchgStartLvBusVolt "Sensed LV bus votlage when beginning DCDC precharge";
CM_ SG_ 708 PCS_dcdcPchgStartHvBusVolt "Sensed HV bus votlage when beginning DCDC precharge";
CM_ SG_ 708 PCS_dcdcHvBusEstimated_C_uF "Power conversion system (on-board charger and DC-DC converter): dcdc hv bus estimated c u f";
CM_ SG_ 708 PCS_dcdcHvBusEstimated_R_kOhm "Power conversion system (on-board charger and DC-DC converter): dcdc hv bus estimated r k ohm";
CM_ SG_ 708 PCS_processorDieIdLot "Power conversion system (on-board charger and DC-DC converter): processor die id lot";
CM_ SG_ 708 PCS_processorDieIdWafer "Power conversion system (on-board charger and DC-DC converter): processor die id wafer";
CM_ SG_ 708 PCS_processorDieIdX "Power conversion system (on-board charger and DC-DC converter): processor die id x";
CM_ SG_ 708 PCS_processorDieIdY "Power conversion system (on-board charger and DC-DC converter): processor die id y";
CM_ BO_ 676 "Power conversion system (on-board charger and DC-DC converter) message: thermal status";
CM_ SG_ 676 PCS_chgPhATemp "Sensed temperature of AC charger phase A";
CM_ SG_ 676 PCS_chgPhBTemp "Sensed temperature of AC charger phase B";
CM_ SG_ 676 PCS_chgPhCTemp "Sensed temperature of AC charger phase C";
CM_ SG_ 676 PCS_dcdcTemp "Sensed temperature of DCDC";
CM_ SG_ 676 PCS_ambientTemp "Ambient temperature sensed by the PCS";
CM_ SG_ 676 PCS_dcdcBusbarTemp "Sensed temperature of DCDC busbar";
CM_ BO_ 1317 "PMF ECU message: alert log";
CM_ SG_ 1317 PMF_alertID "PMF ECU: alert ID";
CM_ SG_ 1317 PMF_alertState "PMF ECU: alert state";
CM_ SG_ 1317 PMF_a001_w0 "PMF ECU: a001 w0";
CM_ SG_ 1317 PMF_a001_w1 "PMF ECU: a001 w1";
CM_ SG_ 1317 PMF_a001_w2 "PMF ECU: a001 w2";
CM_ SG_ 1317 PMF_a002_torqueAverage "PMF ECU: a002 torque average";
CM_ SG_ 1317 PMF_a002_torqueWindow "PMF ECU: a002 torque window";
CM_ SG_ 1317 PMF_a002_torqueMeasured "PMF ECU: a002 torque measured";
CM_ SG_ 1317 PMF_a002_torqueAccelAverage "PMF ECU: a002 torque accel average";
CM_ SG_ 1317 PMF_a002_torqueAccelWindow "PMF ECU: a002 torque accel window";
CM_ SG_ 1317 PMF_a003_reverseGear "PMF ECU: a003 reverse gear";
CM_ SG_ 1317 PMF_a003_pedalPos "PMF ECU: a003 pedal pos";
CM_ SG_ 1317 PMF_a003_zeroPointPedal "PMF ECU: a003 zero point pedal";
CM_ SG_ 1317 PMF_a004_torqueAverage "PMF ECU: a004 torque average";
CM_ SG_ 1317 PMF_a004_torqueWindow "PMF ECU: a004 torque window";
CM_ SG_ 1317 PMF_a004_torqueMeasured "PMF ECU: a004 torque measured";
CM_ SG_ 1317 PMF_a004_torqueDecelAverage "PMF ECU: a004 torque decel average";
CM_ SG_ 1317 PMF_a004_torqueDecelWindow "PMF ECU: a004 torque decel window";
CM_ SG_ 1317 PMF_a005_torqueReason "PMF ECU: a005 torque reason";
CM_ SG_ 1317 PMF_a005_torqueMeasured "PMF ECU: a005 torque measured";
CM_ SG_ 1317 PMF_a005_iDQmagnitude "PMF ECU: a005 i d qmagnitude";
CM_ SG_ 1317 PMF_a006_torqueActual "PMF ECU: a006 torque actual";
CM_ SG_ 1317 PMF_a006_motorRPM "PMF ECU: a006 motor RPM";
CM_ SG_ 1317 PMF_a006_torqueMeasured "PMF ECU: a006 torque measured";
CM_ SG_ 1317 PMF_a010_messageId "PMF ECU: a010 message id";
CM_ SG_ 1317 PMF_a010_DI_status "PMF ECU: a010 DI status";
CM_ SG_ 1317 PMF_a010_DI_torque "PMF ECU: a010 DI torque";
CM_ SG_ 1317 PMF_a010_DI_slaveCommand "PMF ECU: a010 DI slave command";
CM_ SG_ 1317 PMF_a010_DI_locStatus "PMF ECU: a010 DI loc status";
CM_ SG_ 1317 PMF_a010_DI_speed "PMF ECU: a010 DI speed";
CM_ SG_ 1317 PMF_a010_DI_systemStatus "PMF ECU: a010 DI system status";
CM_ SG_ 1317 PMF_a010_DI_chassisControl "PMF ECU: a010 DI chassis control";
CM_ SG_ 1317 PMF_a010_DI_chassisControl2 "PMF ECU: a010 DI chassis control2";
CM_ SG_ 1317 PMF_a010_vdcLeft "PMF ECU: a010 vdc left";
CM_ SG_ 1317 PMF_a010_vdcRight "PMF ECU: a010 vdc right";
CM_ SG_ 1317 PMF_a010_DI_vehicleEstimates "PMF ECU: a010 DI vehicle estimates";
CM_ SG_ 1317 PMF_a010_DI_brakeCommand "PMF ECU: a010 DI brake command";
CM_ SG_ 1317 PMF_a010_DI_autonomyHealth "PMF ECU: a010 DI autonomy health";
CM_ SG_ 1317 PMF_a010_DI_difCommand "PMF ECU: a010 DI dif command";
CM_ SG_ 1317 PMF_a010_DI_dirCommand "PMF ECU: a010 DI dir command";
CM_ SG_ 1317 PMF_a010_DI_dirVehicle "PMF ECU: a010 DI dir vehicle";
CM_ SG_ 1317 PMF_a010_DI_locStatus2 "PMF ECU: a010 DI loc status2";
CM_ SG_ 1317 PMF_a011_Ia "PMF ECU: a011 ia";
CM_ SG_ 1317 PMF_a011_IaDelta "PMF ECU: a011 ia delta";
CM_ SG_ 1317 PMF_a011_Ib "PMF ECU: a011 ib";
CM_ SG_ 1317 PMF_a011_IbDelta "PMF ECU: a011 ib delta";
CM_ SG_ 1317 PMF_a011_currentVref "PMF ECU: a011 current vref";
CM_ SG_ 1317 PMF_a011_badPhaseAsample "PMF ECU: a011 bad phase asample";
CM_ SG_ 1317 PMF_a011_badPhaseBsample "PMF ECU: a011 bad phase bsample";
CM_ SG_ 1317 PMF_a011_sampleFreeze "PMF ECU: a011 sample freeze";
CM_ SG_ 1317 PMF_a011_rateOfChangeIrrational "PMF ECU: a011 rate of change irrational";
CM_ SG_ 1317 PMF_a011_currentReadingIrrationa "PMF ECU: a011 current reading irrational";
CM_ SG_ 1317 PMF_a011_vrefIrrational "PMF ECU: a011 vref irrational";
CM_ SG_ 1317 PMF_a017_EPBL_status "PMF ECU: a017 EPBL status";
CM_ SG_ 1317 PMF_a017_EPBR_status "PMF ECU: a017 EPBR status";
CM_ SG_ 1317 PMF_a017_EPBL_autonomyHealth "PMF ECU: a017 EPBL autonomy health";
CM_ SG_ 1317 PMF_a017_EPBR_autonomyHealth "PMF ECU: a017 EPBR autonomy health";
CM_ SG_ 1317 PMF_a018_w0 "PMF ECU: a018 w0";
CM_ SG_ 1317 PMF_a018_w1 "PMF ECU: a018 w1";
CM_ SG_ 1317 PMF_a018_w2 "PMF ECU: a018 w2";
CM_ SG_ 1317 PMF_a019_statorTemp1 "PMF ECU: a019 stator temp1";
CM_ SG_ 1317 PMF_a019_statorTslope1 "PMF ECU: a019 stator tslope1";
CM_ SG_ 1317 PMF_a025_sccReset "PMF ECU: a025 scc reset";
CM_ SG_ 1317 PMF_a025_hibernate "PMF ECU: a025 hibernate";
CM_ SG_ 1317 PMF_a025_hwBist "PMF ECU: a025 hw bist";
CM_ SG_ 1317 PMF_a025_nmiWatchdog "PMF ECU: a025 nmi watchdog";
CM_ SG_ 1317 PMF_a025_watchdog "PMF ECU: a025 watchdog";
CM_ SG_ 1317 PMF_a025_clockFailNmi "PMF ECU: a025 clock fail nmi";
CM_ SG_ 1317 PMF_a025_ramUncErrorNmi "PMF ECU: a025 ram unc error nmi";
CM_ SG_ 1317 PMF_a025_flashUncErrorNmi "PMF ECU: a025 flash unc error nmi";
CM_ SG_ 1317 PMF_a025_cpu1signMismatchNmi "PMF ECU: a025 cpu1sign mismatch nmi";
CM_ SG_ 1317 PMF_a025_cpu2signMismatchNmi "PMF ECU: a025 cpu2sign mismatch nmi";
CM_ SG_ 1317 PMF_a025_pieVectErrorNmi "PMF ECU: a025 pie vect error nmi";
CM_ SG_ 1317 PMF_a025_sysDbgNmi "PMF ECU: a025 sys dbg nmi";
CM_ SG_ 1317 PMF_a025_rlNmi "PMF ECU: a025 rl nmi";
CM_ SG_ 1317 PMF_a025_ovfNmi "PMF ECU: a025 ovf nmi";
CM_ SG_ 1317 PMF_a025_possibleSafetyICReset "PMF ECU: a025 possible safety IC reset";
CM_ SG_ 1317 PMF_a025_powerOnReset "PMF ECU: a025 power on reset";
CM_ SG_ 1317 PMF_a025_watchdogTimer0 "PMF ECU: a025 watchdog timer0";
CM_ SG_ 1317 PMF_a025_watchdogTimer1 "PMF ECU: a025 watchdog timer1";
CM_ SG_ 1317 PMF_a025_watchdogTimer2 "PMF ECU: a025 watchdog timer2";
CM_ SG_ 1317 PMF_a025_watchdogTimer3 "PMF ECU: a025 watchdog timer3";
CM_ SG_ 1317 PMF_a025_warmResetReq "PMF ECU: a025 warm reset req";
CM_ SG_ 1317 PMF_a025_externalPadReset "PMF ECU: a025 external pad reset";
CM_ SG_ 1317 PMF_a025_hwSecModuleWatchdogTime "PMF ECU: a025 hw sec module watchdog timer";
CM_ SG_ 1317 PMF_a025_debugReset "PMF ECU: a025 debug reset";
CM_ SG_ 1317 PMF_a025_tempSense0 "PMF ECU: a025 temp sense0";
CM_ SG_ 1317 PMF_a025_tempSense1 "PMF ECU: a025 temp sense1";
CM_ SG_ 1317 PMF_a026_reason "PMF ECU: a026 reason";
CM_ SG_ 1317 PMF_a026_isrCount20kHz "PMF ECU: a026 isr count20k hz";
CM_ SG_ 1317 PMF_a026_isrCount1kHz "PMF ECU: a026 isr count1k hz";
CM_ SG_ 1317 PMF_a026_switchingActive "PMF ECU: a026 switching active";
CM_ SG_ 1317 PMF_a026_systemStackOvf "PMF ECU: a026 system stack ovf";
CM_ SG_ 1317 PMF_a026_controlStackOvf "PMF ECU: a026 control stack ovf";
CM_ SG_ 1317 PMF_a026_idleStackOvf "PMF ECU: a026 idle stack ovf";
CM_ SG_ 1317 PMF_a026_eepStackOvf "PMF ECU: a026 eep stack ovf";
CM_ SG_ 1317 PMF_a026_immStackOvf "PMF ECU: a026 imm stack ovf";
CM_ SG_ 1317 PMF_a026_xdcErrorIdMSW "PMF ECU: a026 xdc error id MSW";
CM_ SG_ 1317 PMF_a026_xdcErrorArg1 "PMF ECU: a026 xdc error arg1";
CM_ SG_ 1317 PMF_a032_w0 "PMF ECU: a032 w0";
CM_ SG_ 1317 PMF_a032_w1 "PMF ECU: a032 w1";
CM_ SG_ 1317 PMF_a032_w2 "PMF ECU: a032 w2";
CM_ SG_ 1317 PMF_a033_state "PMF ECU: a033 state";
CM_ SG_ 1317 PMF_a033_failReason "PMF ECU: a033 fail reason";
CM_ SG_ 1317 PMF_a033_DSADC_Ia "PMF ECU: a033 DSADC ia";
CM_ SG_ 1317 PMF_a033_DSADC_Ib "PMF ECU: a033 DSADC ib";
CM_ SG_ 1317 PMF_a036_timeSinceTxHWI "PMF ECU: a036 time since tx HWI";
CM_ SG_ 1317 PMF_a036_timeSinceRxHWI "PMF ECU: a036 time since rx HWI";
CM_ SG_ 1317 PMF_a036_timeSince100HzTxSWI "PMF ECU: a036 time since100 hz tx SWI";
CM_ SG_ 1317 PMF_a036_timeSince1kHzCLK "PMF ECU: a036 time since1k hz CLK";
CM_ SG_ 1317 PMF_a036_timeSince1kHzSWI "PMF ECU: a036 time since1k hz SWI";
CM_ SG_ 1317 PMF_a036_timeSinceIdle "PMF ECU: a036 time since idle";
CM_ SG_ 1317 PMF_a036_ovfStackId "PMF ECU: a036 ovf stack id";
CM_ SG_ 1317 PMF_a036_inTxISR "PMF ECU: a036 in tx ISR";
CM_ SG_ 1317 PMF_a036_inTxHWI "PMF ECU: a036 in tx HWI";
CM_ SG_ 1317 PMF_a036_inRxHWI "PMF ECU: a036 in rx HWI";
CM_ SG_ 1317 PMF_a036_in1kHzSWI "PMF ECU: a036 in1k hz SWI";
CM_ SG_ 1317 PMF_a036_in1kHzCLK "PMF ECU: a036 in1k hz CLK";
CM_ SG_ 1317 PMF_a036_in100HzCLK "PMF ECU: a036 in100 hz CLK";
CM_ SG_ 1317 PMF_a036_in10HzCLK "PMF ECU: a036 in10 hz CLK";
CM_ SG_ 1317 PMF_a036_in1HzCLK "PMF ECU: a036 in1 hz CLK";
CM_ SG_ 1317 PMF_a037_hvpFaults "PMF ECU: a037 hvp faults";
CM_ SG_ 1317 PMF_a039_DIS_status "PMF ECU: a039 DIS status";
CM_ SG_ 1317 PMF_a039_DIS_torque "PMF ECU: a039 DIS torque";
CM_ SG_ 1317 PMF_a039_messageId "PMF ECU: a039 message id";
CM_ SG_ 1317 PMF_a040_PM_state "PMF ECU: a040 PM state";
CM_ SG_ 1317 PMF_a040_messageId "PMF ECU: a040 message id";
CM_ SG_ 1317 PMF_a040_PM_locState "PMF ECU: a040 PM loc state";
CM_ SG_ 1317 PMF_a042_GTW_carConfig "PMF ECU: a042 GTW car config";
CM_ SG_ 1317 PMF_a042_GTW_time "PMF ECU: a042 GTW time";
CM_ SG_ 1317 PMF_a042_GTW_drivetrainType "PMF ECU: a042 GTW drivetrain type";
CM_ SG_ 1317 PMF_a042_expectedPerformanceCfg "PMF ECU: a042 expected performance cfg";
CM_ SG_ 1317 PMF_a042_gearControl "PMF ECU: a042 gear control";
CM_ SG_ 1317 PMF_a053_LVPowerState "PMF ECU: a053 LV power state";
CM_ SG_ 1317 PMF_a053_coolant "PMF ECU: a053 coolant";
CM_ SG_ 1317 PMF_a053_vcleftSwitchStatus "PMF ECU: a053 vcleft switch status";
CM_ SG_ 1317 PMF_a053_restraintStatus "PMF ECU: a053 restraint status";
CM_ SG_ 1317 PMF_a053_sensors "PMF ECU: a053 sensors";
CM_ SG_ 1317 PMF_a054_uiPowertrainControl "PMF ECU: a054 ui powertrain control";
CM_ SG_ 1317 PMF_a054_uiChassisControl "PMF ECU: a054 ui chassis control";
CM_ SG_ 1317 PMF_a054_uiCruiseControl "PMF ECU: a054 ui cruise control";
CM_ SG_ 1317 PMF_a054_uiTrackModeSettings "PMF ECU: a054 ui track mode settings";
CM_ SG_ 1317 PMF_a054_uiTPMSRCPSetting "PMF ECU: a054 ui TPMSRCP setting";
CM_ SG_ 1317 PMF_a055_motorRPM "PMF ECU: a055 motor RPM";
CM_ SG_ 1317 PMF_a055_phaseAngle "PMF ECU: a055 phase angle";
CM_ SG_ 1317 PMF_a055_commonGain "PMF ECU: a055 common gain";
CM_ SG_ 1317 PMF_a055_notReady "PMF ECU: a055 not ready";
CM_ SG_ 1317 PMF_a055_noCarrier "PMF ECU: a055 no carrier";
CM_ SG_ 1317 PMF_a055_phaseOutOfSpec "PMF ECU: a055 phase out of spec";
CM_ SG_ 1317 PMF_a055_diElecAngleMismatch "PMF ECU: a055 di elec angle mismatch";
CM_ SG_ 1317 PMF_a055_diSpeedMismatch "PMF ECU: a055 di speed mismatch";
CM_ SG_ 1317 PMF_a055_claMIA "PMF ECU: a055 cla MIA";
CM_ SG_ 1317 PMF_a055_diMIA "PMF ECU: a055 di MIA";
CM_ SG_ 1317 PMF_a055_diElecAngleMismatchWarn "PMF ECU: a055 di elec angle mismatch warn";
CM_ SG_ 1317 PMF_a058_hvilCurrent "PMF ECU: a058 hvil current";
CM_ SG_ 1317 PMF_a061_diIpcVersion "PMF ECU: a061 di ipc version";
CM_ SG_ 1317 PMF_a061_pmIpcVersion "PMF ECU: a061 pm ipc version";
CM_ SG_ 1317 PMF_a062_address "PMF ECU: a062 address";
CM_ SG_ 1317 PMF_a062_errorType "PMF ECU: a062 error type";
CM_ SG_ 1317 PMF_a062_detectedByRamScrub "PMF ECU: a062 detected by ram scrub";
CM_ SG_ 1317 PMF_a064_interventionType "PMF ECU: a064 intervention type";
CM_ SG_ 1317 PMF_a064_torqueCmdState "PMF ECU: a064 torque cmd state";
CM_ SG_ 1317 PMF_a064_shortDetectedByDI "PMF ECU: a064 short detected by DI";
CM_ SG_ 1317 PMF_a064_UI_stoppingMode "PMF ECU: a064 UI stopping mode";
CM_ SG_ 1317 PMF_a064_diCrsState "PMF ECU: a064 di crs state";
CM_ SG_ 1317 PMF_a064_pmCrsState "PMF ECU: a064 pm crs state";
CM_ SG_ 1317 PMF_a082_faultAddress "PMF ECU: a082 fault address";
CM_ SG_ 1317 PMF_a082_isWriteNotRead "PMF ECU: a082 is write not read";
CM_ SG_ 1317 PMF_a084_faultAddress "PMF ECU: a084 fault address";
CM_ SG_ 1317 PMF_a084_firewallId "PMF ECU: a084 firewall id";
CM_ SG_ 1317 PMF_a084_privId "PMF ECU: a084 priv id";
CM_ SG_ 1317 PMF_a084_ns "PMF ECU: a084 ns";
CM_ SG_ 1317 PMF_a084_faultType "PMF ECU: a084 fault type";
CM_ SG_ 1317 PMF_a092_pllClockSource "PMF ECU: a092 pll clock source";
CM_ SG_ 1317 PMF_a095_wwdErrIntFlag "PMF ECU: a095 wwd err int flag";
CM_ SG_ 1317 PMF_a095_fwdErrIntFlag "PMF ECU: a095 fwd err int flag";
CM_ SG_ 1317 PMF_a095_errMissStsFlag "PMF ECU: a095 err miss sts flag";
CM_ SG_ 1317 PMF_a095_preRegulatorOT "PMF ECU: a095 pre regulator OT";
CM_ SG_ 1317 PMF_a095_ucLdoOT "PMF ECU: a095 uc ldo OT";
CM_ SG_ 1317 PMF_a095_monitoringOT "PMF ECU: a095 monitoring OT";
CM_ SG_ 1317 PMF_a095_preRegulatorVoltShort "PMF ECU: a095 pre regulator volt short";
CM_ SG_ 1317 PMF_a095_ucLdoShort "PMF ECU: a095 uc ldo short";
CM_ SG_ 1317 PMF_a095_standbyLdoShort "PMF ECU: a095 standby ldo short";
CM_ SG_ 1317 PMF_a095_coreVoltShort "PMF ECU: a095 core volt short";
CM_ SG_ 1317 PMF_a095_preRegulatorOV "PMF ECU: a095 pre regulator OV";
CM_ SG_ 1317 PMF_a095_ucLdoOV "PMF ECU: a095 uc ldo OV";
CM_ SG_ 1317 PMF_a095_standbyLdoOV "PMF ECU: a095 standby ldo OV";
CM_ SG_ 1317 PMF_a095_coreOV "PMF ECU: a095 core OV";
CM_ SG_ 1317 PMF_a095_voltRefOV "PMF ECU: a095 volt ref OV";
CM_ SG_ 1317 PMF_a095_ucLdoUV "PMF ECU: a095 uc ldo UV";
CM_ SG_ 1317 PMF_a095_standbyLdoUV "PMF ECU: a095 standby ldo UV";
CM_ SG_ 1317 PMF_a095_coreUV "PMF ECU: a095 core UV";
CM_ SG_ 1317 PMF_a095_supplyVoltOV "PMF ECU: a095 supply volt OV";
CM_ SG_ 1317 PMF_a095_bandgapComparatorUV "PMF ECU: a095 bandgap comparator UV";
CM_ SG_ 1317 PMF_a095_bandgapComparatorOV "PMF ECU: a095 bandgap comparator OV";
CM_ SG_ 1317 PMF_a095_biasCurrentTooLow "PMF ECU: a095 bias current too low";
CM_ SG_ 1317 PMF_a095_biasCurrentTooHigh "PMF ECU: a095 bias current too high";
CM_ SG_ 1317 PMF_a095_safetyICstate "PMF ECU: a095 safety i cstate";
CM_ SG_ 1317 PMF_a095_motorRPM "PMF ECU: a095 motor RPM";
CM_ SG_ 1317 PMF_a095_wwdErrCounter "PMF ECU: a095 wwd err counter";
CM_ SG_ 1317 PMF_a095_fwdErrCounter "PMF ECU: a095 fwd err counter";
CM_ SG_ 1317 PMF_a100_index1kHzPeriodic "PMF ECU: a100 index1k hz periodic";
CM_ SG_ 1317 PMF_a100_index100HzPeriodic "PMF ECU: a100 index100 hz periodic";
CM_ SG_ 1317 PMF_a100_index10HzPeriodic "PMF ECU: a100 index10 hz periodic";
CM_ SG_ 1317 PMF_a100_indexSWI "PMF ECU: a100 index SWI";
CM_ SG_ 1317 PMF_a100_eepEvent "PMF ECU: a100 eep event";
CM_ SG_ 1317 PMF_a100_module500HzActive "PMF ECU: a100 module500 hz active";
CM_ SG_ 1317 PMF_a100_module50HzActive "PMF ECU: a100 module50 hz active";
CM_ SG_ 1317 PMF_a100_module1HzActive "PMF ECU: a100 module1 hz active";
CM_ SG_ 1317 PMF_a100_task10HzActive "PMF ECU: a100 task10 hz active";
CM_ SG_ 1317 PMF_a100_taskUdsActive "PMF ECU: a100 task uds active";
CM_ BO_ 772 "PMF ECU message: alert matrix";
CM_ SG_ 772 PMF_matrixIndex "PMF ECU: matrix index";
CM_ SG_ 772 PMF_a001_absoluteTorque "PMF ECU: a001 absolute torque";
CM_ SG_ 772 PMF_a002_excessiveAccelTorque "PMF ECU: a002 excessive accel torque";
CM_ SG_ 772 PMF_a003_excessiveReversalTorque "PMF ECU: a003 excessive reversal torque";
CM_ SG_ 772 PMF_a004_excessiveDecelTorque "PMF ECU: a004 excessive decel torque";
CM_ SG_ 772 PMF_a005_torqueInNeutralOrPark "PMF ECU: a005 torque in neutral or park";
CM_ SG_ 772 PMF_a006_underTorqueCheck "PMF ECU: a006 under torque check";
CM_ SG_ 772 PMF_a008_memoryError "PMF ECU: a008 memory error";
CM_ SG_ 772 PMF_a010_diMIA "PMF ECU: a010 di MIA";
CM_ SG_ 772 PMF_a011_phaseCurrentIrrational "PMF ECU: a011 phase current irrational";
CM_ SG_ 772 PMF_a012_canDataBusA "PMF ECU: a012 can data bus a";
CM_ SG_ 772 PMF_a013_canHardwareBusA "PMF ECU: a013 can hardware bus a";
CM_ SG_ 772 PMF_a017_brakeMIA "PMF ECU: a017 brake MIA";
CM_ SG_ 772 PMF_a018_encoderIrrational "PMF ECU: a018 encoder irrational";
CM_ SG_ 772 PMF_a019_statorTempIrrational "PMF ECU: a019 stator temp irrational";
CM_ SG_ 772 PMF_a025_unintendedReset "PMF ECU: a025 unintended reset";
CM_ SG_ 772 PMF_a026_diHeartBeatMIA "PMF ECU: a026 di heart beat MIA";
CM_ SG_ 772 PMF_a027_torqueEstimationOutOfBo "PMF ECU: a027 torque estimation out of bounds";
CM_ SG_ 772 PMF_a028_torqueCmdError "PMF ECU: a028 torque cmd error";
CM_ SG_ 772 PMF_a031_highStackUsage "PMF ECU: a031 high stack usage";
CM_ SG_ 772 PMF_a032_registerConfigError "PMF ECU: a032 register config error";
CM_ SG_ 772 PMF_a033_selfTest "PMF ECU: a033 self test";
CM_ SG_ 772 PMF_a034_trqCrossCheck "PMF ECU: a034 trq cross check";
CM_ SG_ 772 PMF_a035_udsTransactionInitiated "PMF ECU: a035 uds transaction initiated";
CM_ SG_ 772 PMF_a036_preWatchdog "PMF ECU: a036 pre watchdog";
CM_ SG_ 772 PMF_a037_hvpMIA "PMF ECU: a037 hvp MIA";
CM_ SG_ 772 PMF_a039_disMIA "PMF ECU: a039 dis MIA";
CM_ SG_ 772 PMF_a040_pmMIA "PMF ECU: a040 pm MIA";
CM_ SG_ 772 PMF_a042_gtwMIA "PMF ECU: a042 gtw MIA";
CM_ SG_ 772 PMF_a045_motorMovementDetected "PMF ECU: a045 motor movement detected";
CM_ SG_ 772 PMF_a053_vcfrontMIA "PMF ECU: a053 vcfront MIA";
CM_ SG_ 772 PMF_a054_uiMIA "PMF ECU: a054 ui MIA";
CM_ SG_ 772 PMF_a055_resolver "PMF ECU: a055 resolver";
CM_ SG_ 772 PMF_a056_canHardwareBusB "PMF ECU: a056 can hardware bus b";
CM_ SG_ 772 PMF_a057_canDataBusB "PMF ECU: a057 can data bus b";
CM_ SG_ 772 PMF_a058_measuredHvilCurrentFroz "PMF ECU: a058 measured hvil current frozen";
CM_ SG_ 772 PMF_a061_DIPMVersionMismatch "PMF ECU: a061 DIPM version mismatch";
CM_ SG_ 772 PMF_a062_eccError "PMF ECU: a062 ecc error";
CM_ SG_ 772 PMF_a064_torqueIntervention "PMF ECU: a064 torque intervention";
CM_ SG_ 772 PMF_a080_exceptionPrefetchAbort "PMF ECU: a080 exception prefetch abort";
CM_ SG_ 772 PMF_a081_exceptionDataAbort "PMF ECU: a081 exception data abort";
CM_ SG_ 772 PMF_a082_exceptionDataAbort2 "PMF ECU: a082 exception data abort2";
CM_ SG_ 772 PMF_a083_ahbWriteError "PMF ECU: a083 ahb write error";
CM_ SG_ 772 PMF_a084_exceptionMpuFirewall "PMF ECU: a084 exception mpu firewall";
CM_ SG_ 772 PMF_a086_exceptionUndefinedInstr "PMF ECU: a086 exception undefined instruction";
CM_ SG_ 772 PMF_a092_xtalOscillator "PMF ECU: a092 xtal oscillator";
CM_ SG_ 772 PMF_a094_safetyICWarn "PMF ECU: a094 safety IC warn";
CM_ SG_ 772 PMF_a095_safetyICFault "PMF ECU: a095 safety IC fault";
CM_ SG_ 772 PMF_a096_safetyICDebug "PMF ECU: a096 safety IC debug";
CM_ SG_ 772 PMF_a097_lowFlowAlmostTripped "PMF ECU: a097 low flow almost tripped";
CM_ SG_ 772 PMF_a100_diTraceInfo1 "PMF ECU: a100 di trace info1";
CM_ SG_ 772 PMF_a114_ramScrubTimedOut "PMF ECU: a114 ram scrub timed out";
CM_ SG_ 772 PMF_a121_unintendedReset2 "PMF ECU: a121 unintended reset2";
CM_ BO_ 790 "PMF ECU message: info";
CM_ SG_ 790 PMF_infoIndex "PMF ECU: info index";
CM_ SG_ 790 PMF_buildType "PMF ECU: build type";
CM_ SG_ 790 PMF_buildConfigurationId "PMF ECU: build configuration id";
CM_ SG_ 790 PMF_hardwareId "PMF ECU: hardware id";
CM_ SG_ 790 PMF_deviceFused "PMF ECU: device fused";
CM_ SG_ 790 PMF_componentId "PMF ECU: component id";
CM_ SG_ 790 PMF_pcbaId "PMF ECU: pcba id";
CM_ SG_ 790 PMF_assemblyId "PMF ECU: assembly id";
CM_ SG_ 790 PMF_usageId "PMF ECU: usage id";
CM_ SG_ 790 PMF_subUsageId "PMF ECU: sub usage id";
CM_ SG_ 790 PMF_applicationCrc "PMF ECU: application crc";
CM_ SG_ 790 PMF_appGitHash "PMF ECU: app git hash";
CM_ SG_ 790 PMF_bootGitHash "PMF ECU: boot git hash";
CM_ SG_ 790 PMF_platformTyp "PMF ECU: platform typ";
CM_ SG_ 790 PMF_udsProtocolVersion "PMF ECU: uds protocol version";
CM_ SG_ 790 PMF_bootloaderCrc "PMF ECU: bootloader crc";
CM_ BO_ 1316 "PMF ECU message: mfg data";
CM_ SG_ 1316 PMF_processorDieIdLot "PMF ECU: processor die id lot";
CM_ SG_ 1316 PMF_processorDieIdWafer "PMF ECU: processor die id wafer";
CM_ SG_ 1316 PMF_processorDieIdX "PMF ECU: processor die id x";
CM_ SG_ 1316 PMF_processorDieIdY "PMF ECU: processor die id y";
BA_DEF_ BO_ "GenMsgCycleTime" INT 0 3600000;
BA_DEF_ BO_ "GenMsgSendType" ENUM "Cyclic","NotUsed","NotUsed","NotUsed","NotUsed","NotUsed","NotUsed","IfActive","NoMsgSendType","NotUsed";
BA_DEF_ BO_ "VFrameFormat" ENUM "StandardCAN","ExtendedCAN","reserved","J1939PG","reserved","reserved","reserved","reserved","reserved","reserved","reserved","reserved","reserved","reserved","StandardCAN_FD","ExtendedCAN_FD";
BA_DEF_ BO_ "CANFD_BRS" ENUM "0","1";
BA_DEF_ SG_ "SystemSignalLongSymbol" STRING;
BA_DEF_ SG_ "Confidence" ENUM "layout-only","plausible","validated";
BA_DEF_DEF_ "GenMsgCycleTime" 0;
BA_DEF_DEF_ "GenMsgSendType" "NoMsgSendType";
BA_DEF_DEF_ "VFrameFormat" "StandardCAN";
BA_DEF_DEF_ "CANFD_BRS" "1";
BA_DEF_DEF_ "SystemSignalLongSymbol" "";
BA_DEF_DEF_ "Confidence" "layout-only";
BA_ "SystemSignalLongSymbol" SG_ 1060 PCS_a016_phAVoltSrcMissingDetect "PCS_a016_phAVoltSrcMissingDetected";
BA_ "SystemSignalLongSymbol" SG_ 1060 PCS_a016_phBVoltSrcMissingDetect "PCS_a016_phBVoltSrcMissingDetected";
BA_ "SystemSignalLongSymbol" SG_ 1060 PCS_a016_phCVoltSrcMissingDetect "PCS_a016_phCVoltSrcMissingDetected";
BA_ "SystemSignalLongSymbol" SG_ 1060 PCS_a025_bootromRequestStatusFla "PCS_a025_bootromRequestStatusFlag";
BA_ "SystemSignalLongSymbol" SG_ 1060 PCS_a038_dcdcPwmEnableDeasserted "PCS_a038_dcdcPwmEnableDeassertedCount";
BA_ "SystemSignalLongSymbol" SG_ 1060 PCS_a047_cpu1BootLoaderCrcMismat "PCS_a047_cpu1BootLoaderCrcMismatch";
BA_ "SystemSignalLongSymbol" SG_ 1060 PCS_a047_cpu2BootLoaderCrcMismat "PCS_a047_cpu2BootLoaderCrcMismatch";
BA_ "SystemSignalLongSymbol" SG_ 1060 PCS_a061_PllSourceIrrational_L1L "PCS_a061_PllSourceIrrational_L1L2";
BA_ "SystemSignalLongSymbol" SG_ 1060 PCS_a076_dcdcPwmEnableDeasserted "PCS_a076_dcdcPwmEnableDeassertedCount";
BA_ "SystemSignalLongSymbol" SG_ 1060 PCS_a079_eepromOperationErrorCod "PCS_a079_eepromOperationErrorCode";
BA_ "SystemSignalLongSymbol" SG_ 1060 PCS_a100_phKwhCounterDeltaFromMa "PCS_a100_phKwhCounterDeltaFromMax";
BA_ "SystemSignalLongSymbol" SG_ 1060 PCS_a108_installedInAWrongPlatfo "PCS_a108_installedInAWrongPlatform";
BA_ "SystemSignalLongSymbol" SG_ 932 PCS_a032_excessiveGridTransients "PCS_a032_excessiveGridTransientsDetected";
BA_ "SystemSignalLongSymbol" SG_ 932 PCS_a073_unexpectedAcInputVoltag "PCS_a073_unexpectedAcInputVoltage";
BA_ "SystemSignalLongSymbol" SG_ 932 PCS_a084_vDropFastInParasiticDio "PCS_a084_vDropFastInParasiticDiodeRegion";
BA_ "SystemSignalLongSymbol" SG_ 932 PCS_a089_hvBusDischargeIrrationa "PCS_a089_hvBusDischargeIrrational";
BA_ "SystemSignalLongSymbol" SG_ 932 PCS_a090_expectedAcVoltageSource "PCS_a090_expectedAcVoltageSourceMissing";
BA_ "SystemSignalLongSymbol" SG_ 932 PCS_a092_chgPowerLimitedByBusRip "PCS_a092_chgPowerLimitedByBusRipple";
BA_ "SystemSignalLongSymbol" SG_ 932 PCS_a095_dcdcSensorlessModeActiv "PCS_a095_dcdcSensorlessModeActive";
BA_ "SystemSignalLongSymbol" SG_ 932 PCS_a098_gridFreqDroopDetectedSi "PCS_a098_gridFreqDroopDetectedSilent";
BA_ "SystemSignalLongSymbol" SG_ 932 PCS_a099_microGridOverLoadedSile "PCS_a099_microGridOverLoadedSilent";
BA_ "SystemSignalLongSymbol" SG_ 932 PCS_a101_phMachineModelIrrationa "PCS_a101_phMachineModelIrrational";
BA_ "SystemSignalLongSymbol" SG_ 932 PCS_a102_resetWithDCDCCmdAsserte "PCS_a102_resetWithDCDCCmdAsserted";
BA_ "SystemSignalLongSymbol" SG_ 932 PCS_a105_redundantVoltageSourceI "PCS_a105_redundantVoltageSourceIrrational";
BA_ "SystemSignalLongSymbol" SG_ 932 PCS_a106_clockSourceNotFromExter "PCS_a106_clockSourceNotFromExternalCrystal";
BA_ "SystemSignalLongSymbol" SG_ 932 PCS_a108_misconfigurationDetecte "PCS_a108_misconfigurationDetected";
BA_ "SystemSignalLongSymbol" SG_ 932 PCS_a109_deltaChargingL2L3Swappe "PCS_a109_deltaChargingL2L3SwappedDetected";
BA_ "SystemSignalLongSymbol" SG_ 932 PCS_d111_batteryChargerPowerLimi "PCS_d111_batteryChargerPowerLimited";
BA_ "SystemSignalLongSymbol" SG_ 932 PCS_d113_dcdcConverterTempSensor "PCS_d113_dcdcConverterTempSensorAIssue";
BA_ "SystemSignalLongSymbol" SG_ 932 PCS_d114_dcdcConverterVoltSensor "PCS_d114_dcdcConverterVoltSensorAIssue";
BA_ "SystemSignalLongSymbol" SG_ 932 PCS_d115_dcdcConverterTempSensor "PCS_d115_dcdcConverterTempSensorBIssue";
BA_ "SystemSignalLongSymbol" SG_ 932 PCS_d116_dcdcConverterVoltSensor "PCS_d116_dcdcConverterVoltSensorBIssue";
BA_ "Confidence" SG_ 612 PCS_chgInputVoltage 1;
BA_ "Confidence" SG_ 612 PCS_chgLineCurrent 1;
BA_ "Confidence" SG_ 612 PCS_chgAcVoltagePresent 1;
BA_ "Confidence" SG_ 612 PCS_chgInputPower 1;
BA_ "Confidence" SG_ 612 PCS_chgAcCurrentLimit 1;
BA_ "Confidence" SG_ 516 PCS_chgMainState 1;
BA_ "Confidence" SG_ 516 PCS_powerTransferStatus 1;
BA_ "Confidence" SG_ 516 PCS_gridConfig 1;
BA_ "Confidence" SG_ 516 PCS_chgPHAEnable 1;
BA_ "Confidence" SG_ 516 PCS_chgPHBEnable 1;
BA_ "Confidence" SG_ 516 PCS_chgPHCEnable 1;
BA_ "Confidence" SG_ 516 PCS_chgInstantAcPowerAvailable 1;
BA_ "Confidence" SG_ 516 PCS_chgMaxAcPowerAvailable 1;
BA_ "Confidence" SG_ 516 PCS_chgPHALineCurrentRequest 1;
BA_ "Confidence" SG_ 516 PCS_chgPHBLineCurrentRequest 1;
BA_ "Confidence" SG_ 516 PCS_chgPHCLineCurrentRequest 1;
BA_ "Confidence" SG_ 516 PCS_chgPwmEnableLine 1;
BA_ "Confidence" SG_ 516 PCS_powerTransferShutdownRequest 1;
BA_ "Confidence" SG_ 516 PCS_hwVariantType 1;
BA_ "Confidence" SG_ 516 PCS_dcacBidirectionalAllowed 1;
BA_ "Confidence" SG_ 692 PCS_dcdcLvBusVolt 1;
BA_ "Confidence" SG_ 692 PCS_dcdcHvBusVolt 1;
BA_ "Confidence" SG_ 692 PCS_dcdcLvOutputCurrent 1;
BA_ "Confidence" SG_ 548 PCS_dcdcPrechargeStatus 1;
BA_ "Confidence" SG_ 548 PCS_dcdcLvSupportStatus 1;
BA_ "Confidence" SG_ 548 PCS_dcdcHvBusDischargeStatus 1;
BA_ "Confidence" SG_ 548 PCS_dcdcSubState 1;
BA_ "Confidence" SG_ 548 PCS_dcdcFaulted 1;
BA_ "Confidence" SG_ 548 PCS_dcdcEn13V5WithStrongPullup 1;
BA_ "Confidence" SG_ 548 PCS_dcdcOutputIsLimited 1;
BA_ "Confidence" SG_ 548 PCS_dcdcMaxOutputCurrentAllowed 1;
BA_ "Confidence" SG_ 548 PCS_dcdcPwmEnableLine 1;
BA_ "Confidence" SG_ 548 PCS_dcdcSupportingFixedLvTarget 1;
BA_ "Confidence" SG_ 548 PCS_ecuLogUploadRequest 1;
BA_ "Confidence" SG_ 548 PCS_dcdcInitialPrechargeSubState 1;
BA_ "Confidence" SG_ 964 PCS_buildType 1;
BA_ "Confidence" SG_ 964 PCS_pcbaId 1;
BA_ "Confidence" SG_ 964 PCS_usageId 1;
BA_ "Confidence" SG_ 964 PCS_subUsageId 1;
BA_ "Confidence" SG_ 708 PCS_chgPhAInputIrms 1;
BA_ "Confidence" SG_ 708 PCS_chgPhAIntBusV 1;
BA_ "Confidence" SG_ 708 PCS_chgPhAIntBusVTarget 1;
BA_ "Confidence" SG_ 708 PCS_chgPhAOutputI 1;
BA_ "Confidence" SG_ 708 PCS_chgPhAInputCurrentLimitReaso 1;
BA_ "SystemSignalLongSymbol" SG_ 708 PCS_chgPhAInputCurrentLimitReaso "PCS_chgPhAInputCurrentLimitReason";
BA_ "Confidence" SG_ 708 PCS_chgPhBInputIrms 1;
BA_ "Confidence" SG_ 708 PCS_chgPhBIntBusV 1;
BA_ "Confidence" SG_ 708 PCS_chgPhBIntBusVTarget 1;
BA_ "Confidence" SG_ 708 PCS_chgPhBOutputI 1;
BA_ "Confidence" SG_ 708 PCS_chgPhBInputCurrentLimitReaso 1;
BA_ "SystemSignalLongSymbol" SG_ 708 PCS_chgPhBInputCurrentLimitReaso "PCS_chgPhBInputCurrentLimitReason";
BA_ "Confidence" SG_ 708 PCS_chgPhCInputIrms 1;
BA_ "Confidence" SG_ 708 PCS_chgPhCIntBusV 1;
BA_ "Confidence" SG_ 708 PCS_chgPhCIntBusVTarget 1;
BA_ "Confidence" SG_ 708 PCS_chgPhCOutputI 1;
BA_ "Confidence" SG_ 708 PCS_chgPhCInputCurrentLimitReaso 1;
BA_ "SystemSignalLongSymbol" SG_ 708 PCS_chgPhCInputCurrentLimitReaso "PCS_chgPhCInputCurrentLimitReason";
BA_ "Confidence" SG_ 708 PCS_chgInputL1NVrms 1;
BA_ "Confidence" SG_ 708 PCS_chgInputL2NVrms 1;
BA_ "Confidence" SG_ 708 PCS_chgInputL3NVrms 1;
BA_ "Confidence" SG_ 708 PCS_chgInputL1L2Vrms 1;
BA_ "Confidence" SG_ 708 PCS_chgInputNGVrms 1;
BA_ "Confidence" SG_ 708 PCS_chgInputFrequencyL1N 1;
BA_ "Confidence" SG_ 708 PCS_chgInputFrequencyL2N 1;
BA_ "Confidence" SG_ 708 PCS_chgInputFrequencyL3N 1;
BA_ "Confidence" SG_ 708 PCS_chgInternalPhaseConfig 1;
BA_ "Confidence" SG_ 708 PCS_chgPhasesPriority 1;
BA_ "Confidence" SG_ 708 PCS_chgOutputV 1;
BA_ "Confidence" SG_ 708 PCS_chgPhAState 1;
BA_ "Confidence" SG_ 708 PCS_chgPhBState 1;
BA_ "Confidence" SG_ 708 PCS_chgPhCState 1;
BA_ "Confidence" SG_ 708 PCS_chgPhALastShutdownReason 1;
BA_ "Confidence" SG_ 708 PCS_chgPhBLastShutdownReason 1;
BA_ "Confidence" SG_ 708 PCS_chgPhCLastShutdownReason 1;
BA_ "Confidence" SG_ 708 PCS_chgPhARetryCount 1;
BA_ "Confidence" SG_ 708 PCS_chgPhBRetryCount 1;
BA_ "Confidence" SG_ 708 PCS_chgPhCRetryCount 1;
BA_ "Confidence" SG_ 708 PCS_chgRetryCount 1;
BA_ "Confidence" SG_ 708 PCS_chgPhManCurrentToDist 1;
BA_ "Confidence" SG_ 708 PCS_dcdcMaxLvOutputCurrent 1;
BA_ "Confidence" SG_ 708 PCS_dcdcCurrentLimit 1;
BA_ "Confidence" SG_ 708 PCS_dcdcLvOutputCurrentTempLimit 1;
BA_ "Confidence" SG_ 708 PCS_dcdcLvOutputCurrentFiltered 1;
BA_ "Confidence" SG_ 708 PCS_dcdcUnifiedCommand 1;
BA_ "Confidence" SG_ 708 PCS_dcdcCLAControllerOutput 1;
BA_ "Confidence" SG_ 708 PCS_dcdcTankVoltage 1;
BA_ "Confidence" SG_ 708 PCS_dcdcTankVoltageTarget 1;
BA_ "Confidence" SG_ 708 PCS_dcdcClaCurrentFreq 1;
BA_ "Confidence" SG_ 708 PCS_dcdcTCommMeasured 1;
BA_ "Confidence" SG_ 708 PCS_dcdcShortTimeUs 1;
BA_ "Confidence" SG_ 708 PCS_dcdcHalfPeriodUs 1;
BA_ "Confidence" SG_ 708 PCS_dcdcLvBusVoltTargetWithOffse 1;
BA_ "SystemSignalLongSymbol" SG_ 708 PCS_dcdcLvBusVoltTargetWithOffse "PCS_dcdcLvBusVoltTargetWithOffset";
BA_ "Confidence" SG_ 708 PCS_cpu2BootState 1;
BA_ "Confidence" SG_ 708 PCS_acChargeSelfTestState 1;
BA_ "Confidence" SG_ 708 PCS_1V5Min10s 1;
BA_ "Confidence" SG_ 708 PCS_1V5Max10s 1;
BA_ "Confidence" SG_ 708 PCS_1V2Min10s 1;
BA_ "Confidence" SG_ 708 PCS_1V2Max10s 1;
BA_ "Confidence" SG_ 708 PCS_5VNMax10s 1;
BA_ "Confidence" SG_ 708 PCS_chgPhAIntBusVMin10s 1;
BA_ "Confidence" SG_ 708 PCS_chgPhAIntBusVMax10s 1;
BA_ "Confidence" SG_ 708 PCS_chgPhAPchgVoltDeltaMax10s 1;
BA_ "Confidence" SG_ 708 PCS_chgPhALifetimekWh 1;
BA_ "Confidence" SG_ 708 PCS_chgPhATransientRetryCount 1;
BA_ "Confidence" SG_ 708 PCS_chgPhBIntBusVMin10s 1;
BA_ "Confidence" SG_ 708 PCS_chgPhBIntBusVMax10s 1;
BA_ "Confidence" SG_ 708 PCS_chgPhBPchgVoltDeltaMax10s 1;
BA_ "Confidence" SG_ 708 PCS_chgPhBLifetimekWh 1;
BA_ "Confidence" SG_ 708 PCS_chgPhBTransientRetryCount 1;
BA_ "Confidence" SG_ 708 PCS_chgPhCIntBusVMin10s 1;
BA_ "Confidence" SG_ 708 PCS_chgPhCIntBusVMax10s 1;
BA_ "Confidence" SG_ 708 PCS_chgPhCPchgVoltDeltaMax10s 1;
BA_ "Confidence" SG_ 708 PCS_chgPhCLifetimekWh 1;
BA_ "Confidence" SG_ 708 PCS_chgPhCTransientRetryCount 1;
BA_ "Confidence" SG_ 708 PCS_chgPhANoFlowBucket 1;
BA_ "Confidence" SG_ 708 PCS_chgPhBNoFlowBucket 1;
BA_ "Confidence" SG_ 708 PCS_chgPhCNoFlowBucket 1;
BA_ "Confidence" SG_ 708 PCS_chgCurrentSensorOutOfBandUs 1;
BA_ "Confidence" SG_ 708 PCS_chgAcpwHeartbeatState 1;
BA_ "Confidence" SG_ 708 PCS_chgKwhLostByFreqDroop 1;
BA_ "Confidence" SG_ 708 PCS_chgReqKwhLostByFreqDroop 1;
BA_ "Confidence" SG_ 708 PCS_dcdcLvSupportLifetimekWh 1;
BA_ "Confidence" SG_ 708 PCS_dcdcPwmEnableLineErrorCount 1;
BA_ "Confidence" SG_ 708 PCS_dcdcPchgStartLvBusVolt 1;
BA_ "Confidence" SG_ 708 PCS_dcdcPchgStartHvBusVolt 1;
BA_ "Confidence" SG_ 708 PCS_dcdcHvBusEstimated_C_uF 1;
BA_ "Confidence" SG_ 708 PCS_dcdcHvBusEstimated_R_kOhm 1;
BA_ "Confidence" SG_ 676 PCS_chgPhATemp 1;
BA_ "Confidence" SG_ 676 PCS_chgPhBTemp 1;
BA_ "Confidence" SG_ 676 PCS_chgPhCTemp 1;
BA_ "Confidence" SG_ 676 PCS_dcdcTemp 1;
BA_ "Confidence" SG_ 676 PCS_ambientTemp 1;
BA_ "Confidence" SG_ 676 PCS_dcdcBusbarTemp 1;
BA_ "SystemSignalLongSymbol" SG_ 1317 PMF_a011_currentReadingIrrationa "PMF_a011_currentReadingIrrational";
BA_ "SystemSignalLongSymbol" SG_ 1317 PMF_a025_hwSecModuleWatchdogTime "PMF_a025_hwSecModuleWatchdogTimer";
BA_ "SystemSignalLongSymbol" SG_ 772 PMF_a027_torqueEstimationOutOfBo "PMF_a027_torqueEstimationOutOfBounds";
BA_ "SystemSignalLongSymbol" SG_ 772 PMF_a058_measuredHvilCurrentFroz "PMF_a058_measuredHvilCurrentFrozen";
BA_ "SystemSignalLongSymbol" SG_ 772 PMF_a086_exceptionUndefinedInstr "PMF_a086_exceptionUndefinedInstruction";
BA_ "Confidence" SG_ 790 PMF_buildType 1;
VAL_ 516 PCS_chgMainState 9 "PCS_CHG_STATE_CLEAR_FAULTS" 8 "PCS_CHG_STATE_FAULTED" 7 "PCS_CHG_STATE_SHUTDOWN" 6 "PCS_CHG_STATE_ENABLE" 5 "PCS_CHG_STATE_SYSTEM_CONFIG" 4 "PCS_CHG_STATE_QUALIFY_LINE_CONFIG" 3 "PCS_CHG_STATE_WAIT_FOR_LINE_VOLTAGE" 2 "PCS_CHG_STATE_STARTUP" 1 "PCS_CHG_STATE_IDLE" 0 "PCS_CHG_STATE_INIT" ;
VAL_ 516 PCS_powerTransferStatus 3 "PCS_POWER_TRANSFER_FAULTED" 2 "PCS_POWER_TRANSFER_ENABLED" 1 "PCS_POWER_TRANSFER_BLOCKED" 0 "PCS_POWER_TRANSFER_STANDBY" ;
VAL_ 516 PCS_gridConfig 3 "GRID_CONFIG_THREE_PHASE_DELTA" 2 "GRID_CONFIG_THREE_PHASE" 1 "GRID_CONFIG_SINGLE_PHASE" 0 "GRID_CONFIG_SNA" ;
VAL_ 516 PCS_powerTransferShutdownRequest 3 "EMERGENCY_SHUTDOWN_REQUESTED" 2 "ESCALATED_SHUTDOWN_REQUESTED" 1 "GRACEFUL_SHUTDOWN_REQUESTED" 0 "NO_SHUTDOWN_REQUESTED" ;
VAL_ 516 PCS_hwVariantType 3 "PCS_HW_VARIANT_TYPE_SNA" 2 "PCS_THREE_PHASES_VARIANT" 1 "PCS_32A_SINGLE_PHASE_VARIANT" 0 "PCS_48A_SINGLE_PHASE_VARIANT" ;
VAL_ 548 PCS_dcdcPrechargeStatus 3 "PCS_DCDC_PRECHARGE_IMPEDANCE_CHECK" 2 "PCS_DCDC_PRECHARGE_FAULTED" 1 "PCS_DCDC_PRECHARGE_ACTIVE" 0 "PCS_DCDC_PRECHARGE_IDLE" ;
VAL_ 548 PCS_dcdcLvSupportStatus 2 "PCS_DCDC_LV_SUPPORT_FAULTED" 1 "PCS_DCDC_LV_SUPPORT_ACTIVE" 0 "PCS_DCDC_LV_SUPPORT_IDLE" ;
VAL_ 548 PCS_dcdcHvBusDischargeStatus 2 "PCS_DCDC_DIS_HVBUS_FAULTED" 1 "PCS_DCDC_DIS_HVBUS_ACTIVE" 0 "PCS_DCDC_DIS_HVBUS_IDLE" ;
VAL_ 548 PCS_dcdcSubState 18 "DCDC_SUBSTATE_NUM" 17 "DCDC_SUBSTATE_FAULTED" 16 "DCDC_SUBSTATE_CLEAR_FAULTS" 15 "DCDC_SUBSTATE_PCHG_FAULTED" 14 "DCDC_SUBSTATE_DIS_HVBUS_FAULTED" 13 "DCDC_SUBSTATE_LV_SUPPORT_FAULTED" 12 "DCDC_SUBSTATE_SHUTDOWN" 11 "DCDC_SUBSTATE_PCHG_FLT_FAST_DIS_HVBUS" 10 "DCDC_SUBSTATE_PCHG_ACTIVE" 9 "DCDC_SUBSTATE_PCHG_DI_RECOVERY_WAIT" 8 "DCDC_SUBSTATE_PCHG_DWELL_WAIT" 7 "DCDC_SUBSTATE_PCHG_DWELL_CHARGE" 6 "DCDC_SUBSTATE_PCHG_SLOW_DIS_HVBUS" 5 "DCDC_SUBSTATE_PCHG_FAST_DIS_HVBUS" 4 "DCDC_SUBSTATE_SLOW_DIS_HVBUS" 3 "DCDC_SUBSTATE_FAST_DIS_HVBUS" 2 "DCDC_SUBSTATE_LV_SUPPORT_ACTIVE" 1 "DCDC_SUBSTATE_STANDBY" 0 "DCDC_SUBSTATE_PWR_UP_INIT" ;
VAL_ 548 PCS_ecuLogUploadRequest 3 "REQUEST_PRIORITY_3" 2 "REQUEST_PRIORITY_2" 1 "REQUEST_PRIORITY_1" 0 "REQUEST_PRIORITY_NONE" ;
VAL_ 548 PCS_dcdcInitialPrechargeSubState 18 "DCDC_SUBSTATE_NUM" 17 "DCDC_SUBSTATE_FAULTED" 16 "DCDC_SUBSTATE_CLEAR_FAULTS" 15 "DCDC_SUBSTATE_PCHG_FAULTED" 14 "DCDC_SUBSTATE_DIS_HVBUS_FAULTED" 13 "DCDC_SUBSTATE_LV_SUPPORT_FAULTED" 12 "DCDC_SUBSTATE_SHUTDOWN" 11 "DCDC_SUBSTATE_PCHG_FLT_FAST_DIS_HVBUS" 10 "DCDC_SUBSTATE_PCHG_ACTIVE" 9 "DCDC_SUBSTATE_PCHG_DI_RECOVERY_WAIT" 8 "DCDC_SUBSTATE_PCHG_DWELL_WAIT" 7 "DCDC_SUBSTATE_PCHG_DWELL_CHARGE" 6 "DCDC_SUBSTATE_PCHG_SLOW_DIS_HVBUS" 5 "DCDC_SUBSTATE_PCHG_FAST_DIS_HVBUS" 4 "DCDC_SUBSTATE_SLOW_DIS_HVBUS" 3 "DCDC_SUBSTATE_FAST_DIS_HVBUS" 2 "DCDC_SUBSTATE_LV_SUPPORT_ACTIVE" 1 "DCDC_SUBSTATE_STANDBY" 0 "DCDC_SUBSTATE_PWR_UP_INIT" ;
VAL_ 964 PCS_buildType 4 "INFO_MFG_BUILD" 3 "INFO_TRACEABLE_CI_BUILD" 2 "INFO_LOCAL_BUILD" 1 "INFO_PLATFORM_BUILD" 0 "INFO_UNKNOWN_BUILD" ;
VAL_ 708 PCS_chgPhAInputCurrentLimitReaso 5 "PCS_IAC_LIMITED_BY_PHASE_MACHINE_MODEL" 4 "PCS_IAC_LIMITED_BY_PHASE_THERMAL_LIMIT" 3 "PCS_IAC_LIMITED_BY_INPUT_POWER" 2 "PCS_IAC_LIMITED_BY_OUTPUT_POWER" 1 "PCS_IAC_LIMITED_BY_RIPPLE_RELAXED" 0 "PCS_IAC_LIMITED_BY_NONE" ;
VAL_ 708 PCS_chgPhBInputCurrentLimitReaso 5 "PCS_IAC_LIMITED_BY_PHASE_MACHINE_MODEL" 4 "PCS_IAC_LIMITED_BY_PHASE_THERMAL_LIMIT" 3 "PCS_IAC_LIMITED_BY_INPUT_POWER" 2 "PCS_IAC_LIMITED_BY_OUTPUT_POWER" 1 "PCS_IAC_LIMITED_BY_RIPPLE_RELAXED" 0 "PCS_IAC_LIMITED_BY_NONE" ;
VAL_ 708 PCS_chgPhCInputCurrentLimitReaso 5 "PCS_IAC_LIMITED_BY_PHASE_MACHINE_MODEL" 4 "PCS_IAC_LIMITED_BY_PHASE_THERMAL_LIMIT" 3 "PCS_IAC_LIMITED_BY_INPUT_POWER" 2 "PCS_IAC_LIMITED_BY_OUTPUT_POWER" 1 "PCS_IAC_LIMITED_BY_RIPPLE_RELAXED" 0 "PCS_IAC_LIMITED_BY_NONE" ;
VAL_ 708 PCS_chgInternalPhaseConfig 9 "PHASE_CONFIG_TOTAL_NUM" 8 "PHASE_CONFIG_SINGLE_PHASE_EVSE_PARALLEL" 7 "PHASE_CONFIG_SINGLE_PHASE_BRIDGED_HARNESS" 6 "PHASE_CONFIG_MFG_TEST_CONFIG_2" 5 "PHASE_CONFIG_MFG_TEST_CONFIG_1" 4 "PHASE_CONFIG_SINGLE_PHASE_IEC_GB" 3 "PHASE_CONFIG_THREE_PHASE_DELTA" 2 "PHASE_CONFIG_THREE_PHASE" 1 "PHASE_CONFIG_SINGLE_PHASE" 0 "PHASE_CONFIG_SNA" ;
VAL_ 708 PCS_chgPhasesPriority 36 "PHASES_PRIORITY_ABC" 33 "PHASES_PRIORITY_BAC" 24 "PHASES_PRIORITY_ACB" 18 "PHASES_PRIORITY_CAB" 9 "PHASES_PRIORITY_BCA" 6 "PHASES_PRIORITY_CBA" 0 "UNDEFINED_PHASES_PRIORITY" ;
VAL_ 708 PCS_chgPhAState 6 "PCS_PH_STATE_SHUTTING_DOWN" 5 "PCS_PH_STATE_CLEAR_FAULTS" 4 "PCS_PH_STATE_FAULT" 3 "PCS_PH_STATE_ENABLE" 2 "PCS_PH_STATE_PRECHARGE" 1 "PCS_PH_STATE_IDLE" 0 "PCS_PH_STATE_INIT" ;
VAL_ 708 PCS_chgPhBState 6 "PCS_PH_STATE_SHUTTING_DOWN" 5 "PCS_PH_STATE_CLEAR_FAULTS" 4 "PCS_PH_STATE_FAULT" 3 "PCS_PH_STATE_ENABLE" 2 "PCS_PH_STATE_PRECHARGE" 1 "PCS_PH_STATE_IDLE" 0 "PCS_PH_STATE_INIT" ;
VAL_ 708 PCS_chgPhCState 6 "PCS_PH_STATE_SHUTTING_DOWN" 5 "PCS_PH_STATE_CLEAR_FAULTS" 4 "PCS_PH_STATE_FAULT" 3 "PCS_PH_STATE_ENABLE" 2 "PCS_PH_STATE_PRECHARGE" 1 "PCS_PH_STATE_IDLE" 0 "PCS_PH_STATE_INIT" ;
VAL_ 708 PCS_chgPhALastShutdownReason 17 "PCS_PH_SHUTDOWN_LINE_TRANSIENT_FAULT" 16 "PCS_PH_SHUTDOWN_FREQ_OUT_OF_RANGE" 15 "PCS_PH_SHUTDOWN_SENSOR_IRRATIONAL" 14 "PCS_PH_SHUTDOWN_TEMP_IRRATIONAL" 13 "PCS_PH_SHUTDOWN_OVER_TEMPERATURE" 12 "PCS_PH_SHUTDOWN_CONTROL_REGULATION_FAULT" 11 "PCS_PH_SHUTDOWN_INT_BUS_UV" 10 "PCS_PH_SHUTDOWN_PRECHARGE_TIMEOUT" 9 "PCS_PH_SHUTDOWN_OUTPUT_OV" 8 "PCS_PH_SHUTDOWN_OUTPUT_UV" 7 "PCS_PH_SHUTDOWN_INPUT_OV" 6 "PCS_PH_SHUTDOWN_INPUT_UV" 5 "PCS_PH_SHUTDOWN_PLL_NOT_LOCKED" 4 "PCS_PH_SHUTDOWN_HW_FAULT" 3 "PCS_PH_SHUTDOWN_SW_FAULT" 2 "PCS_PH_SHUTDOWN_HW_ENABLE" 1 "PCS_PH_SHUTDOWN_SW_ENABLE" 0 "PCS_PH_SHUTDOWN_REASON_NONE" ;
VAL_ 708 PCS_chgPhBLastShutdownReason 17 "PCS_PH_SHUTDOWN_LINE_TRANSIENT_FAULT" 16 "PCS_PH_SHUTDOWN_FREQ_OUT_OF_RANGE" 15 "PCS_PH_SHUTDOWN_SENSOR_IRRATIONAL" 14 "PCS_PH_SHUTDOWN_TEMP_IRRATIONAL" 13 "PCS_PH_SHUTDOWN_OVER_TEMPERATURE" 12 "PCS_PH_SHUTDOWN_CONTROL_REGULATION_FAULT" 11 "PCS_PH_SHUTDOWN_INT_BUS_UV" 10 "PCS_PH_SHUTDOWN_PRECHARGE_TIMEOUT" 9 "PCS_PH_SHUTDOWN_OUTPUT_OV" 8 "PCS_PH_SHUTDOWN_OUTPUT_UV" 7 "PCS_PH_SHUTDOWN_INPUT_OV" 6 "PCS_PH_SHUTDOWN_INPUT_UV" 5 "PCS_PH_SHUTDOWN_PLL_NOT_LOCKED" 4 "PCS_PH_SHUTDOWN_HW_FAULT" 3 "PCS_PH_SHUTDOWN_SW_FAULT" 2 "PCS_PH_SHUTDOWN_HW_ENABLE" 1 "PCS_PH_SHUTDOWN_SW_ENABLE" 0 "PCS_PH_SHUTDOWN_REASON_NONE" ;
VAL_ 708 PCS_chgPhCLastShutdownReason 17 "PCS_PH_SHUTDOWN_LINE_TRANSIENT_FAULT" 16 "PCS_PH_SHUTDOWN_FREQ_OUT_OF_RANGE" 15 "PCS_PH_SHUTDOWN_SENSOR_IRRATIONAL" 14 "PCS_PH_SHUTDOWN_TEMP_IRRATIONAL" 13 "PCS_PH_SHUTDOWN_OVER_TEMPERATURE" 12 "PCS_PH_SHUTDOWN_CONTROL_REGULATION_FAULT" 11 "PCS_PH_SHUTDOWN_INT_BUS_UV" 10 "PCS_PH_SHUTDOWN_PRECHARGE_TIMEOUT" 9 "PCS_PH_SHUTDOWN_OUTPUT_OV" 8 "PCS_PH_SHUTDOWN_OUTPUT_UV" 7 "PCS_PH_SHUTDOWN_INPUT_OV" 6 "PCS_PH_SHUTDOWN_INPUT_UV" 5 "PCS_PH_SHUTDOWN_PLL_NOT_LOCKED" 4 "PCS_PH_SHUTDOWN_HW_FAULT" 3 "PCS_PH_SHUTDOWN_SW_FAULT" 2 "PCS_PH_SHUTDOWN_HW_ENABLE" 1 "PCS_PH_SHUTDOWN_SW_ENABLE" 0 "PCS_PH_SHUTDOWN_REASON_NONE" ;
VAL_ 708 PCS_cpu2BootState 3 "CPU2_STATE_ERROR" 2 "CPU2_STATE_APPLICATION" 1 "CPU2_STATE_BOOTLOADER" 0 "CPU2_STATE_BOOTROM" ;
VAL_ 708 PCS_acChargeSelfTestState 1 "PCS_SELF_TEST_STARTED" 0 "PCS_SELF_TEST_IDLE" ;
VAL_ 708 PCS_chgAcpwHeartbeatState 4 "PCS_ACPW_HEARTBEAT_STATE_NUM" 3 "PCS_ACPW_HEARTBEAT_STATE_DETECTED_ONGRID" 2 "PCS_ACPW_HEARTBEAT_STATE_DETECTED_OFFGRID" 1 "PCS_ACPW_HEARTBEAT_STATE_NOT_DETECTED" 0 "PCS_ACPW_HEARTBEAT_STATE_UNKNOWN" ;
VAL_ 790 PMF_buildType 4 "INFO_MFG_BUILD" 3 "INFO_TRACEABLE_CI_BUILD" 2 "INFO_LOCAL_BUILD" 1 "INFO_PLATFORM_BUILD" 0 "INFO_UNKNOWN_BUILD" ;
